[part 2 of 2: package /MICROSAR/Dem_swc/ComponentTypes]
AUTOSAR XML (schema 00049)
package /MICROSAR/Dem_swc/ComponentTypes  (continued)
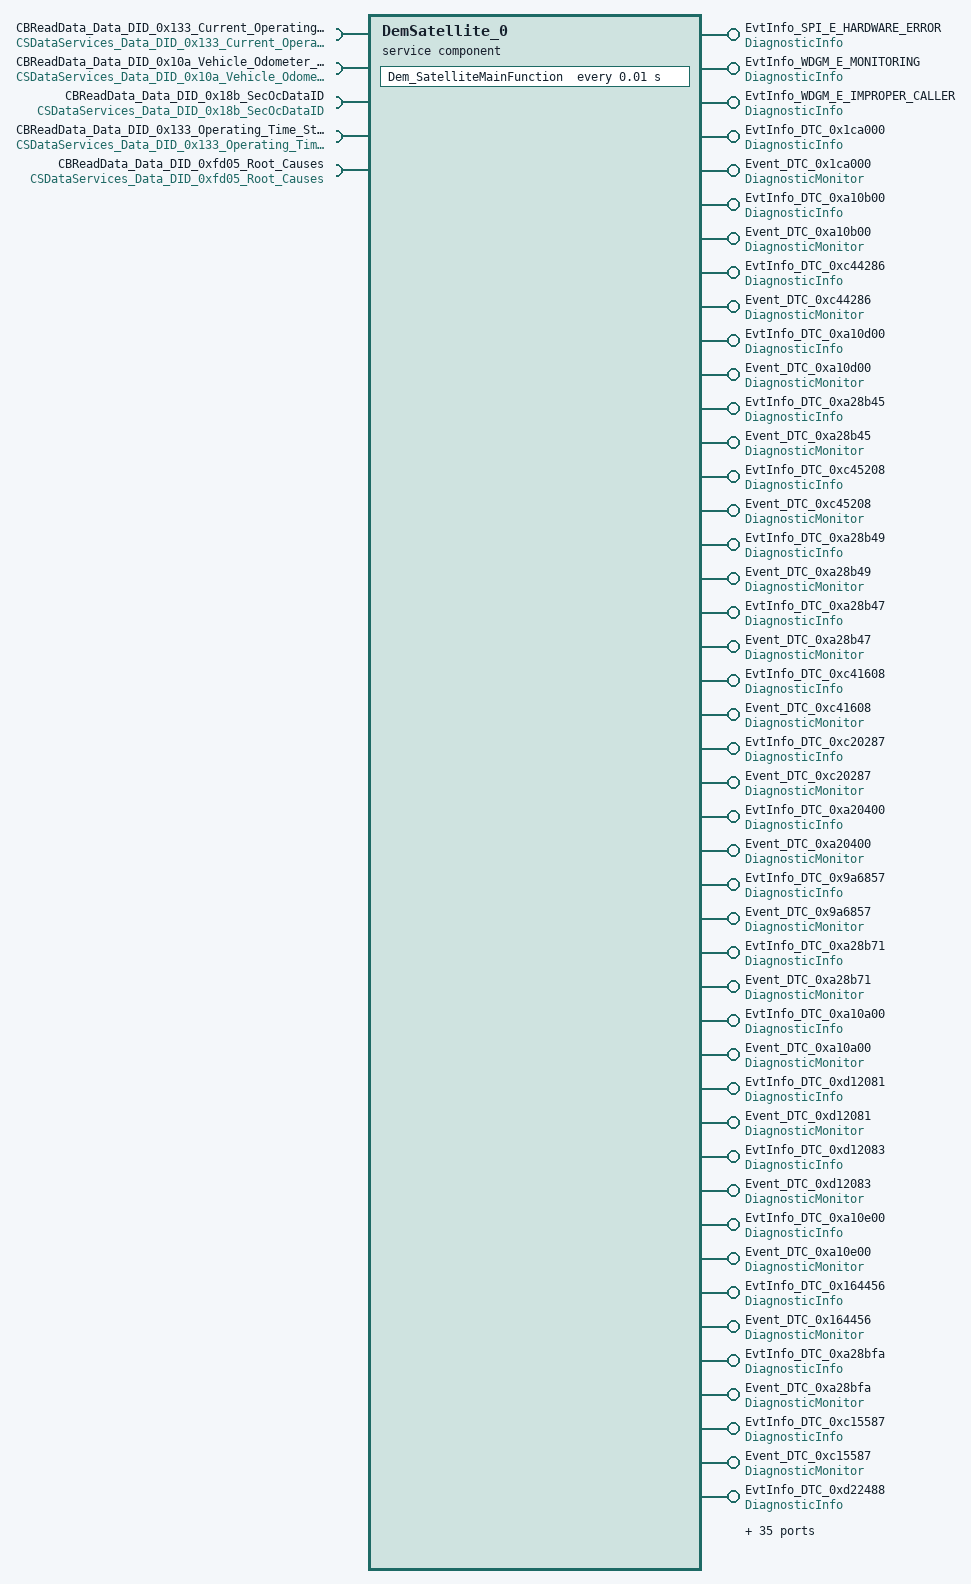
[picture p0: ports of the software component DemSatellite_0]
  service sw component type DemSatellite_0: category=SERVICE_COMPONENT
    70 x provide port:
      EvtInfo_SPI_E_HARDWARE_ERROR: provided-interface=DiagnosticInfo
      EvtInfo_WDGM_E_MONITORING: provided-interface=DiagnosticInfo
      EvtInfo_WDGM_E_IMPROPER_CALLER: provided-interface=DiagnosticInfo
      EvtInfo_DTC_0x1ca000: provided-interface=DiagnosticInfo
      Event_DTC_0x1ca000: provided-interface=DiagnosticMonitor
      EvtInfo_DTC_0xa10b00: provided-interface=DiagnosticInfo
      Event_DTC_0xa10b00: provided-interface=DiagnosticMonitor
      EvtInfo_DTC_0xc44286: provided-interface=DiagnosticInfo
      Event_DTC_0xc44286: provided-interface=DiagnosticMonitor
      EvtInfo_DTC_0xa10d00: provided-interface=DiagnosticInfo
      Event_DTC_0xa10d00: provided-interface=DiagnosticMonitor
      EvtInfo_DTC_0xa28b45: provided-interface=DiagnosticInfo
      Event_DTC_0xa28b45: provided-interface=DiagnosticMonitor
      EvtInfo_DTC_0xc45208: provided-interface=DiagnosticInfo
      Event_DTC_0xc45208: provided-interface=DiagnosticMonitor
      EvtInfo_DTC_0xa28b49: provided-interface=DiagnosticInfo
      Event_DTC_0xa28b49: provided-interface=DiagnosticMonitor
      EvtInfo_DTC_0xa28b47: provided-interface=DiagnosticInfo
      Event_DTC_0xa28b47: provided-interface=DiagnosticMonitor
      EvtInfo_DTC_0xc41608: provided-interface=DiagnosticInfo
      Event_DTC_0xc41608: provided-interface=DiagnosticMonitor
      EvtInfo_DTC_0xc20287: provided-interface=DiagnosticInfo
      Event_DTC_0xc20287: provided-interface=DiagnosticMonitor
      EvtInfo_DTC_0xa20400: provided-interface=DiagnosticInfo
      Event_DTC_0xa20400: provided-interface=DiagnosticMonitor
      EvtInfo_DTC_0x9a6857: provided-interface=DiagnosticInfo
      Event_DTC_0x9a6857: provided-interface=DiagnosticMonitor
      EvtInfo_DTC_0xa28b71: provided-interface=DiagnosticInfo
      Event_DTC_0xa28b71: provided-interface=DiagnosticMonitor
      EvtInfo_DTC_0xa10a00: provided-interface=DiagnosticInfo
      Event_DTC_0xa10a00: provided-interface=DiagnosticMonitor
      EvtInfo_DTC_0xd12081: provided-interface=DiagnosticInfo
      Event_DTC_0xd12081: provided-interface=DiagnosticMonitor
      EvtInfo_DTC_0xd12083: provided-interface=DiagnosticInfo
      Event_DTC_0xd12083: provided-interface=DiagnosticMonitor
      EvtInfo_DTC_0xa10e00: provided-interface=DiagnosticInfo
      Event_DTC_0xa10e00: provided-interface=DiagnosticMonitor
      EvtInfo_DTC_0x164456: provided-interface=DiagnosticInfo
      Event_DTC_0x164456: provided-interface=DiagnosticMonitor
      EvtInfo_DTC_0xa28bfa: provided-interface=DiagnosticInfo
      Event_DTC_0xa28bfa: provided-interface=DiagnosticMonitor
      EvtInfo_DTC_0xc15587: provided-interface=DiagnosticInfo
      Event_DTC_0xc15587: provided-interface=DiagnosticMonitor
      EvtInfo_DTC_0xd22488: provided-interface=DiagnosticInfo
      Event_DTC_0xd22488: provided-interface=DiagnosticMonitor
      EvtInfo_DTC_0xd12087: provided-interface=DiagnosticInfo
      Event_DTC_0xd12087: provided-interface=DiagnosticMonitor
      EvtInfo_DTC_0xc11587: provided-interface=DiagnosticInfo
      Event_DTC_0xc11587: provided-interface=DiagnosticMonitor
      EvtInfo_DTC_0xc15187: provided-interface=DiagnosticInfo
      Event_DTC_0xc15187: provided-interface=DiagnosticMonitor
      EvtInfo_DTC_0xc20187: provided-interface=DiagnosticInfo
      Event_DTC_0xc20187: provided-interface=DiagnosticMonitor
      EvtInfo_DTC_0xa28b4b: provided-interface=DiagnosticInfo
      Event_DTC_0xa28b4b: provided-interface=DiagnosticMonitor
      EvtInfo_DTC_0xa28b96: provided-interface=DiagnosticInfo
      Event_DTC_0xa28b96: provided-interface=DiagnosticMonitor
      EvtInfo_DTC_0xc12287: provided-interface=DiagnosticInfo
      Event_DTC_0xc12287: provided-interface=DiagnosticMonitor
      EvtInfo_DTC_0xc16887: provided-interface=DiagnosticInfo
      Event_DTC_0xc16887: provided-interface=DiagnosticMonitor
      EvtInfo_DTC_0xa28b97: provided-interface=DiagnosticInfo
      Event_DTC_0xa28b97: provided-interface=DiagnosticMonitor
      EvtInfo_DTC_0xa28b16: provided-interface=DiagnosticInfo
      Event_DTC_0xa28b16: provided-interface=DiagnosticMonitor
      EvtInfo_DTC_0xc42708: provided-interface=DiagnosticInfo
      Event_DTC_0xc42708: provided-interface=DiagnosticMonitor
      EvtInfo_DTC_0xa28b17: provided-interface=DiagnosticInfo
      Event_DTC_0xa28b17: provided-interface=DiagnosticMonitor
      GeneralEvtInfo: provided-interface=GeneralDiagnosticInfo
    4 x require port:
      CBReadData_Data_DID_0x133_Current_Operating_Time: required-interface=CSDataServices_Data_DID_0x133_Current_Operating_Time
      CBReadData_Data_DID_0x10a_Vehicle_Odometer_in_Low_Resolution: required-interface=CSDataServices_Data_DID_0x10a_Vehicle_Odometer_in_Low_Resolution
      CBReadData_Data_DID_0x18b_SecOcDataID: required-interface=CSDataServices_Data_DID_0x18b_SecOcDataID
      CBReadData_Data_DID_0x133_Operating_Time_Status: required-interface=CSDataServices_Data_DID_0x133_Operating_Time_Status
    9 x provide port:
      EvtInfo_ADC_ERROR_Dummy: provided-interface=DiagnosticInfo
      Event_ADC_ERROR_Dummy: provided-interface=DiagnosticMonitor
      EvtInfo_MCU_E_OSC_FAILURE: provided-interface=DiagnosticInfo
      EvtInfo_MCU_E_SYSTEM_PLL_LOCK_LOSS: provided-interface=DiagnosticInfo
      EvtInfo_FEE_E_READ: provided-interface=DiagnosticInfo
      EvtInfo_DTC_0xd88987: provided-interface=DiagnosticInfo
      Event_DTC_0xd88987: provided-interface=DiagnosticMonitor
      EvtInfo_DTC_0xd88a08: provided-interface=DiagnosticInfo
      Event_DTC_0xd88a08: provided-interface=DiagnosticMonitor
    require port CBReadData_Data_DID_0xfd05_Root_Causes: required-interface=CSDataServices_Data_DID_0xfd05_Root_Causes
    behavior DemSatellite_0InternalBehavior: handle-termination-and-restart=NO-SUPPORT, included-data-type-set=data-type=[Dem_EventIdType, Dem_RatioIdType, Dem_EventStatusType, Dem_UdsStatusByteType, Dem_DTCFormatType, Dem_InitMonitorReasonType, Dem_OperationCycleStateType, Dem_DTCStatusMaskType, Dem_IndicatorStatusType, Dem_MaxDataValueType, Dem_DTCKindType, Dem_DTCGroupType, Dem_IumprDenomCondIdType, Dem_IumprDenomCondStatusType, Dem_DebounceResetStatusType, Dem_DebouncingStateType, Dem_IumprReadinessGroupType, Dem_DTRControlType, Dem_DTCSeverityType, Dem_MonitorStatusType]
      timing event Timer_Dem_SatelliteMainFunction: start-on-event=Dem_SatelliteMainFunction, period=0.01
      869 x operation invoked event:
        OpEventGetEventUdsStatus_GetEventUdsStatus_EvtInfo_SPI_E_HARDWARE_ERROR: start-on-event=DemSatellite_0InternalBehavior/GetEventUdsStatus, operation=EvtInfo_SPI_E_HARDWARE_ERROR.GetEventUdsStatus
        OpEventGetEventUdsStatus_GetEventUdsStatus_EvtInfo_WDGM_E_MONITORING: start-on-event=DemSatellite_0InternalBehavior/GetEventUdsStatus, operation=EvtInfo_WDGM_E_MONITORING.GetEventUdsStatus
        OpEventGetEventUdsStatus_GetEventUdsStatus_EvtInfo_WDGM_E_IMPROPER_CALLER: start-on-event=DemSatellite_0InternalBehavior/GetEventUdsStatus, operation=EvtInfo_WDGM_E_IMPROPER_CALLER.GetEventUdsStatus
        OpEventGetEventUdsStatus_GetEventUdsStatus_EvtInfo_DTC_0x1ca000: start-on-event=DemSatellite_0InternalBehavior/GetEventUdsStatus, operation=EvtInfo_DTC_0x1ca000.GetEventUdsStatus
        OpEventGetEventUdsStatus_GetEventUdsStatus_Event_DTC_0x1ca000: start-on-event=DemSatellite_0InternalBehavior/GetEventUdsStatus, operation=Event_DTC_0x1ca000.GetEventUdsStatus
        OpEventGetEventUdsStatus_GetEventUdsStatus_EvtInfo_DTC_0xa10b00: start-on-event=DemSatellite_0InternalBehavior/GetEventUdsStatus, operation=EvtInfo_DTC_0xa10b00.GetEventUdsStatus
        OpEventGetEventUdsStatus_GetEventUdsStatus_Event_DTC_0xa10b00: start-on-event=DemSatellite_0InternalBehavior/GetEventUdsStatus, operation=Event_DTC_0xa10b00.GetEventUdsStatus
        OpEventGetEventUdsStatus_GetEventUdsStatus_EvtInfo_DTC_0xc44286: start-on-event=DemSatellite_0InternalBehavior/GetEventUdsStatus, operation=EvtInfo_DTC_0xc44286.GetEventUdsStatus
        OpEventGetEventUdsStatus_GetEventUdsStatus_Event_DTC_0xc44286: start-on-event=DemSatellite_0InternalBehavior/GetEventUdsStatus, operation=Event_DTC_0xc44286.GetEventUdsStatus
        OpEventGetEventUdsStatus_GetEventUdsStatus_EvtInfo_DTC_0xa10d00: start-on-event=DemSatellite_0InternalBehavior/GetEventUdsStatus, operation=EvtInfo_DTC_0xa10d00.GetEventUdsStatus
        OpEventGetEventUdsStatus_GetEventUdsStatus_Event_DTC_0xa10d00: start-on-event=DemSatellite_0InternalBehavior/GetEventUdsStatus, operation=Event_DTC_0xa10d00.GetEventUdsStatus
        OpEventGetEventUdsStatus_GetEventUdsStatus_EvtInfo_DTC_0xa28b45: start-on-event=DemSatellite_0InternalBehavior/GetEventUdsStatus, operation=EvtInfo_DTC_0xa28b45.GetEventUdsStatus
        OpEventGetEventUdsStatus_GetEventUdsStatus_Event_DTC_0xa28b45: start-on-event=DemSatellite_0InternalBehavior/GetEventUdsStatus, operation=Event_DTC_0xa28b45.GetEventUdsStatus
        OpEventGetEventUdsStatus_GetEventUdsStatus_EvtInfo_DTC_0xc45208: start-on-event=DemSatellite_0InternalBehavior/GetEventUdsStatus, operation=EvtInfo_DTC_0xc45208.GetEventUdsStatus
        OpEventGetEventUdsStatus_GetEventUdsStatus_Event_DTC_0xc45208: start-on-event=DemSatellite_0InternalBehavior/GetEventUdsStatus, operation=Event_DTC_0xc45208.GetEventUdsStatus
        OpEventGetEventUdsStatus_GetEventUdsStatus_EvtInfo_DTC_0xa28b49: start-on-event=DemSatellite_0InternalBehavior/GetEventUdsStatus, operation=EvtInfo_DTC_0xa28b49.GetEventUdsStatus
        OpEventGetEventUdsStatus_GetEventUdsStatus_Event_DTC_0xa28b49: start-on-event=DemSatellite_0InternalBehavior/GetEventUdsStatus, operation=Event_DTC_0xa28b49.GetEventUdsStatus
        OpEventGetEventUdsStatus_GetEventUdsStatus_EvtInfo_DTC_0xa28b47: start-on-event=DemSatellite_0InternalBehavior/GetEventUdsStatus, operation=EvtInfo_DTC_0xa28b47.GetEventUdsStatus
        OpEventGetEventUdsStatus_GetEventUdsStatus_Event_DTC_0xa28b47: start-on-event=DemSatellite_0InternalBehavior/GetEventUdsStatus, operation=Event_DTC_0xa28b47.GetEventUdsStatus
        OpEventGetEventUdsStatus_GetEventUdsStatus_EvtInfo_DTC_0xc41608: start-on-event=DemSatellite_0InternalBehavior/GetEventUdsStatus, operation=EvtInfo_DTC_0xc41608.GetEventUdsStatus
        OpEventGetEventUdsStatus_GetEventUdsStatus_Event_DTC_0xc41608: start-on-event=DemSatellite_0InternalBehavior/GetEventUdsStatus, operation=Event_DTC_0xc41608.GetEventUdsStatus
        OpEventGetEventUdsStatus_GetEventUdsStatus_EvtInfo_DTC_0xc20287: start-on-event=DemSatellite_0InternalBehavior/GetEventUdsStatus, operation=EvtInfo_DTC_0xc20287.GetEventUdsStatus
        OpEventGetEventUdsStatus_GetEventUdsStatus_Event_DTC_0xc20287: start-on-event=DemSatellite_0InternalBehavior/GetEventUdsStatus, operation=Event_DTC_0xc20287.GetEventUdsStatus
        OpEventGetEventUdsStatus_GetEventUdsStatus_EvtInfo_DTC_0xa20400: start-on-event=DemSatellite_0InternalBehavior/GetEventUdsStatus, operation=EvtInfo_DTC_0xa20400.GetEventUdsStatus
        OpEventGetEventUdsStatus_GetEventUdsStatus_Event_DTC_0xa20400: start-on-event=DemSatellite_0InternalBehavior/GetEventUdsStatus, operation=Event_DTC_0xa20400.GetEventUdsStatus
        OpEventGetEventUdsStatus_GetEventUdsStatus_EvtInfo_DTC_0x9a6857: start-on-event=DemSatellite_0InternalBehavior/GetEventUdsStatus, operation=EvtInfo_DTC_0x9a6857.GetEventUdsStatus
        OpEventGetEventUdsStatus_GetEventUdsStatus_Event_DTC_0x9a6857: start-on-event=DemSatellite_0InternalBehavior/GetEventUdsStatus, operation=Event_DTC_0x9a6857.GetEventUdsStatus
        OpEventGetEventUdsStatus_GetEventUdsStatus_EvtInfo_DTC_0xa28b71: start-on-event=DemSatellite_0InternalBehavior/GetEventUdsStatus, operation=EvtInfo_DTC_0xa28b71.GetEventUdsStatus
        OpEventGetEventUdsStatus_GetEventUdsStatus_Event_DTC_0xa28b71: start-on-event=DemSatellite_0InternalBehavior/GetEventUdsStatus, operation=Event_DTC_0xa28b71.GetEventUdsStatus
        OpEventGetEventUdsStatus_GetEventUdsStatus_EvtInfo_DTC_0xa10a00: start-on-event=DemSatellite_0InternalBehavior/GetEventUdsStatus, operation=EvtInfo_DTC_0xa10a00.GetEventUdsStatus
        OpEventGetEventUdsStatus_GetEventUdsStatus_Event_DTC_0xa10a00: start-on-event=DemSatellite_0InternalBehavior/GetEventUdsStatus, operation=Event_DTC_0xa10a00.GetEventUdsStatus
        OpEventGetEventUdsStatus_GetEventUdsStatus_EvtInfo_DTC_0xd12081: start-on-event=DemSatellite_0InternalBehavior/GetEventUdsStatus, operation=EvtInfo_DTC_0xd12081.GetEventUdsStatus
        OpEventGetEventUdsStatus_GetEventUdsStatus_Event_DTC_0xd12081: start-on-event=DemSatellite_0InternalBehavior/GetEventUdsStatus, operation=Event_DTC_0xd12081.GetEventUdsStatus
        OpEventGetEventUdsStatus_GetEventUdsStatus_EvtInfo_DTC_0xd12083: start-on-event=DemSatellite_0InternalBehavior/GetEventUdsStatus, operation=EvtInfo_DTC_0xd12083.GetEventUdsStatus
        OpEventGetEventUdsStatus_GetEventUdsStatus_Event_DTC_0xd12083: start-on-event=DemSatellite_0InternalBehavior/GetEventUdsStatus, operation=Event_DTC_0xd12083.GetEventUdsStatus
        OpEventGetEventUdsStatus_GetEventUdsStatus_EvtInfo_DTC_0xa10e00: start-on-event=DemSatellite_0InternalBehavior/GetEventUdsStatus, operation=EvtInfo_DTC_0xa10e00.GetEventUdsStatus
        OpEventGetEventUdsStatus_GetEventUdsStatus_Event_DTC_0xa10e00: start-on-event=DemSatellite_0InternalBehavior/GetEventUdsStatus, operation=Event_DTC_0xa10e00.GetEventUdsStatus
        OpEventGetEventUdsStatus_GetEventUdsStatus_EvtInfo_DTC_0x164456: start-on-event=DemSatellite_0InternalBehavior/GetEventUdsStatus, operation=EvtInfo_DTC_0x164456.GetEventUdsStatus
        OpEventGetEventUdsStatus_GetEventUdsStatus_Event_DTC_0x164456: start-on-event=DemSatellite_0InternalBehavior/GetEventUdsStatus, operation=Event_DTC_0x164456.GetEventUdsStatus
        OpEventGetEventUdsStatus_GetEventUdsStatus_EvtInfo_DTC_0xa28bfa: start-on-event=DemSatellite_0InternalBehavior/GetEventUdsStatus, operation=EvtInfo_DTC_0xa28bfa.GetEventUdsStatus
        OpEventGetEventUdsStatus_GetEventUdsStatus_Event_DTC_0xa28bfa: start-on-event=DemSatellite_0InternalBehavior/GetEventUdsStatus, operation=Event_DTC_0xa28bfa.GetEventUdsStatus
        OpEventGetEventUdsStatus_GetEventUdsStatus_EvtInfo_DTC_0xc15587: start-on-event=DemSatellite_0InternalBehavior/GetEventUdsStatus, operation=EvtInfo_DTC_0xc15587.GetEventUdsStatus
        OpEventGetEventUdsStatus_GetEventUdsStatus_Event_DTC_0xc15587: start-on-event=DemSatellite_0InternalBehavior/GetEventUdsStatus, operation=Event_DTC_0xc15587.GetEventUdsStatus
        OpEventGetEventUdsStatus_GetEventUdsStatus_EvtInfo_DTC_0xd22488: start-on-event=DemSatellite_0InternalBehavior/GetEventUdsStatus, operation=EvtInfo_DTC_0xd22488.GetEventUdsStatus
        OpEventGetEventUdsStatus_GetEventUdsStatus_Event_DTC_0xd22488: start-on-event=DemSatellite_0InternalBehavior/GetEventUdsStatus, operation=Event_DTC_0xd22488.GetEventUdsStatus
        OpEventGetEventUdsStatus_GetEventUdsStatus_EvtInfo_DTC_0xd12087: start-on-event=DemSatellite_0InternalBehavior/GetEventUdsStatus, operation=EvtInfo_DTC_0xd12087.GetEventUdsStatus
        OpEventGetEventUdsStatus_GetEventUdsStatus_Event_DTC_0xd12087: start-on-event=DemSatellite_0InternalBehavior/GetEventUdsStatus, operation=Event_DTC_0xd12087.GetEventUdsStatus
        OpEventGetEventUdsStatus_GetEventUdsStatus_EvtInfo_DTC_0xc11587: start-on-event=DemSatellite_0InternalBehavior/GetEventUdsStatus, operation=EvtInfo_DTC_0xc11587.GetEventUdsStatus
        OpEventGetEventUdsStatus_GetEventUdsStatus_Event_DTC_0xc11587: start-on-event=DemSatellite_0InternalBehavior/GetEventUdsStatus, operation=Event_DTC_0xc11587.GetEventUdsStatus
        OpEventGetEventUdsStatus_GetEventUdsStatus_EvtInfo_DTC_0xc15187: start-on-event=DemSatellite_0InternalBehavior/GetEventUdsStatus, operation=EvtInfo_DTC_0xc15187.GetEventUdsStatus
        OpEventGetEventUdsStatus_GetEventUdsStatus_Event_DTC_0xc15187: start-on-event=DemSatellite_0InternalBehavior/GetEventUdsStatus, operation=Event_DTC_0xc15187.GetEventUdsStatus
        OpEventGetEventUdsStatus_GetEventUdsStatus_EvtInfo_DTC_0xc20187: start-on-event=DemSatellite_0InternalBehavior/GetEventUdsStatus, operation=EvtInfo_DTC_0xc20187.GetEventUdsStatus
        OpEventGetEventUdsStatus_GetEventUdsStatus_Event_DTC_0xc20187: start-on-event=DemSatellite_0InternalBehavior/GetEventUdsStatus, operation=Event_DTC_0xc20187.GetEventUdsStatus
        OpEventGetEventUdsStatus_GetEventUdsStatus_EvtInfo_DTC_0xa28b4b: start-on-event=DemSatellite_0InternalBehavior/GetEventUdsStatus, operation=EvtInfo_DTC_0xa28b4b.GetEventUdsStatus
        OpEventGetEventUdsStatus_GetEventUdsStatus_Event_DTC_0xa28b4b: start-on-event=DemSatellite_0InternalBehavior/GetEventUdsStatus, operation=Event_DTC_0xa28b4b.GetEventUdsStatus
        OpEventGetEventUdsStatus_GetEventUdsStatus_EvtInfo_DTC_0xa28b96: start-on-event=DemSatellite_0InternalBehavior/GetEventUdsStatus, operation=EvtInfo_DTC_0xa28b96.GetEventUdsStatus
        OpEventGetEventUdsStatus_GetEventUdsStatus_Event_DTC_0xa28b96: start-on-event=DemSatellite_0InternalBehavior/GetEventUdsStatus, operation=Event_DTC_0xa28b96.GetEventUdsStatus
        OpEventGetEventUdsStatus_GetEventUdsStatus_EvtInfo_DTC_0xc12287: start-on-event=DemSatellite_0InternalBehavior/GetEventUdsStatus, operation=EvtInfo_DTC_0xc12287.GetEventUdsStatus
        OpEventGetEventUdsStatus_GetEventUdsStatus_Event_DTC_0xc12287: start-on-event=DemSatellite_0InternalBehavior/GetEventUdsStatus, operation=Event_DTC_0xc12287.GetEventUdsStatus
        OpEventGetEventUdsStatus_GetEventUdsStatus_EvtInfo_DTC_0xc16887: start-on-event=DemSatellite_0InternalBehavior/GetEventUdsStatus, operation=EvtInfo_DTC_0xc16887.GetEventUdsStatus
        OpEventGetEventUdsStatus_GetEventUdsStatus_Event_DTC_0xc16887: start-on-event=DemSatellite_0InternalBehavior/GetEventUdsStatus, operation=Event_DTC_0xc16887.GetEventUdsStatus
        OpEventGetEventUdsStatus_GetEventUdsStatus_EvtInfo_DTC_0xa28b97: start-on-event=DemSatellite_0InternalBehavior/GetEventUdsStatus, operation=EvtInfo_DTC_0xa28b97.GetEventUdsStatus
        OpEventGetEventUdsStatus_GetEventUdsStatus_Event_DTC_0xa28b97: start-on-event=DemSatellite_0InternalBehavior/GetEventUdsStatus, operation=Event_DTC_0xa28b97.GetEventUdsStatus
        OpEventGetEventUdsStatus_GetEventUdsStatus_EvtInfo_DTC_0xa28b16: start-on-event=DemSatellite_0InternalBehavior/GetEventUdsStatus, operation=EvtInfo_DTC_0xa28b16.GetEventUdsStatus
        OpEventGetEventUdsStatus_GetEventUdsStatus_Event_DTC_0xa28b16: start-on-event=DemSatellite_0InternalBehavior/GetEventUdsStatus, operation=Event_DTC_0xa28b16.GetEventUdsStatus
        OpEventGetEventUdsStatus_GetEventUdsStatus_EvtInfo_DTC_0xc42708: start-on-event=DemSatellite_0InternalBehavior/GetEventUdsStatus, operation=EvtInfo_DTC_0xc42708.GetEventUdsStatus
        OpEventGetEventUdsStatus_GetEventUdsStatus_Event_DTC_0xc42708: start-on-event=DemSatellite_0InternalBehavior/GetEventUdsStatus, operation=Event_DTC_0xc42708.GetEventUdsStatus
        OpEventGetEventUdsStatus_GetEventUdsStatus_EvtInfo_DTC_0xa28b17: start-on-event=DemSatellite_0InternalBehavior/GetEventUdsStatus, operation=EvtInfo_DTC_0xa28b17.GetEventUdsStatus
        OpEventGetEventUdsStatus_GetEventUdsStatus_Event_DTC_0xa28b17: start-on-event=DemSatellite_0InternalBehavior/GetEventUdsStatus, operation=Event_DTC_0xa28b17.GetEventUdsStatus
        OpEventGetEventUdsStatus_GetEventUdsStatus_GeneralEvtInfo: start-on-event=DemSatellite_0InternalBehavior/GetEventUdsStatus, operation=GeneralEvtInfo.GetEventUdsStatus
        OpEventGetEventStatus_GetEventStatus_EvtInfo_SPI_E_HARDWARE_ERROR: start-on-event=DemSatellite_0InternalBehavior/GetEventStatus, operation=EvtInfo_SPI_E_HARDWARE_ERROR.GetEventStatus
        OpEventGetEventStatus_GetEventStatus_EvtInfo_WDGM_E_MONITORING: start-on-event=DemSatellite_0InternalBehavior/GetEventStatus, operation=EvtInfo_WDGM_E_MONITORING.GetEventStatus
        OpEventGetEventStatus_GetEventStatus_EvtInfo_WDGM_E_IMPROPER_CALLER: start-on-event=DemSatellite_0InternalBehavior/GetEventStatus, operation=EvtInfo_WDGM_E_IMPROPER_CALLER.GetEventStatus
        OpEventGetEventStatus_GetEventStatus_EvtInfo_DTC_0x1ca000: start-on-event=DemSatellite_0InternalBehavior/GetEventStatus, operation=EvtInfo_DTC_0x1ca000.GetEventStatus
        OpEventGetEventStatus_GetEventStatus_Event_DTC_0x1ca000: start-on-event=DemSatellite_0InternalBehavior/GetEventStatus, operation=Event_DTC_0x1ca000.GetEventStatus
        OpEventGetEventStatus_GetEventStatus_EvtInfo_DTC_0xa10b00: start-on-event=DemSatellite_0InternalBehavior/GetEventStatus, operation=EvtInfo_DTC_0xa10b00.GetEventStatus
        OpEventGetEventStatus_GetEventStatus_Event_DTC_0xa10b00: start-on-event=DemSatellite_0InternalBehavior/GetEventStatus, operation=Event_DTC_0xa10b00.GetEventStatus
        OpEventGetEventStatus_GetEventStatus_EvtInfo_DTC_0xc44286: start-on-event=DemSatellite_0InternalBehavior/GetEventStatus, operation=EvtInfo_DTC_0xc44286.GetEventStatus
        OpEventGetEventStatus_GetEventStatus_Event_DTC_0xc44286: start-on-event=DemSatellite_0InternalBehavior/GetEventStatus, operation=Event_DTC_0xc44286.GetEventStatus
        OpEventGetEventStatus_GetEventStatus_EvtInfo_DTC_0xa10d00: start-on-event=DemSatellite_0InternalBehavior/GetEventStatus, operation=EvtInfo_DTC_0xa10d00.GetEventStatus
        OpEventGetEventStatus_GetEventStatus_Event_DTC_0xa10d00: start-on-event=DemSatellite_0InternalBehavior/GetEventStatus, operation=Event_DTC_0xa10d00.GetEventStatus
        OpEventGetEventStatus_GetEventStatus_EvtInfo_DTC_0xa28b45: start-on-event=DemSatellite_0InternalBehavior/GetEventStatus, operation=EvtInfo_DTC_0xa28b45.GetEventStatus
        OpEventGetEventStatus_GetEventStatus_Event_DTC_0xa28b45: start-on-event=DemSatellite_0InternalBehavior/GetEventStatus, operation=Event_DTC_0xa28b45.GetEventStatus
        OpEventGetEventStatus_GetEventStatus_EvtInfo_DTC_0xc45208: start-on-event=DemSatellite_0InternalBehavior/GetEventStatus, operation=EvtInfo_DTC_0xc45208.GetEventStatus
        OpEventGetEventStatus_GetEventStatus_Event_DTC_0xc45208: start-on-event=DemSatellite_0InternalBehavior/GetEventStatus, operation=Event_DTC_0xc45208.GetEventStatus
        OpEventGetEventStatus_GetEventStatus_EvtInfo_DTC_0xa28b49: start-on-event=DemSatellite_0InternalBehavior/GetEventStatus, operation=EvtInfo_DTC_0xa28b49.GetEventStatus
        OpEventGetEventStatus_GetEventStatus_Event_DTC_0xa28b49: start-on-event=DemSatellite_0InternalBehavior/GetEventStatus, operation=Event_DTC_0xa28b49.GetEventStatus
        OpEventGetEventStatus_GetEventStatus_EvtInfo_DTC_0xa28b47: start-on-event=DemSatellite_0InternalBehavior/GetEventStatus, operation=EvtInfo_DTC_0xa28b47.GetEventStatus
        OpEventGetEventStatus_GetEventStatus_Event_DTC_0xa28b47: start-on-event=DemSatellite_0InternalBehavior/GetEventStatus, operation=Event_DTC_0xa28b47.GetEventStatus
        OpEventGetEventStatus_GetEventStatus_EvtInfo_DTC_0xc41608: start-on-event=DemSatellite_0InternalBehavior/GetEventStatus, operation=EvtInfo_DTC_0xc41608.GetEventStatus
        OpEventGetEventStatus_GetEventStatus_Event_DTC_0xc41608: start-on-event=DemSatellite_0InternalBehavior/GetEventStatus, operation=Event_DTC_0xc41608.GetEventStatus
        OpEventGetEventStatus_GetEventStatus_EvtInfo_DTC_0xc20287: start-on-event=DemSatellite_0InternalBehavior/GetEventStatus, operation=EvtInfo_DTC_0xc20287.GetEventStatus
        OpEventGetEventStatus_GetEventStatus_Event_DTC_0xc20287: start-on-event=DemSatellite_0InternalBehavior/GetEventStatus, operation=Event_DTC_0xc20287.GetEventStatus
        OpEventGetEventStatus_GetEventStatus_EvtInfo_DTC_0xa20400: start-on-event=DemSatellite_0InternalBehavior/GetEventStatus, operation=EvtInfo_DTC_0xa20400.GetEventStatus
        OpEventGetEventStatus_GetEventStatus_Event_DTC_0xa20400: start-on-event=DemSatellite_0InternalBehavior/GetEventStatus, operation=Event_DTC_0xa20400.GetEventStatus
        OpEventGetEventStatus_GetEventStatus_EvtInfo_DTC_0x9a6857: start-on-event=DemSatellite_0InternalBehavior/GetEventStatus, operation=EvtInfo_DTC_0x9a6857.GetEventStatus
        OpEventGetEventStatus_GetEventStatus_Event_DTC_0x9a6857: start-on-event=DemSatellite_0InternalBehavior/GetEventStatus, operation=Event_DTC_0x9a6857.GetEventStatus
        OpEventGetEventStatus_GetEventStatus_EvtInfo_DTC_0xa28b71: start-on-event=DemSatellite_0InternalBehavior/GetEventStatus, operation=EvtInfo_DTC_0xa28b71.GetEventStatus
        OpEventGetEventStatus_GetEventStatus_Event_DTC_0xa28b71: start-on-event=DemSatellite_0InternalBehavior/GetEventStatus, operation=Event_DTC_0xa28b71.GetEventStatus
        OpEventGetEventStatus_GetEventStatus_EvtInfo_DTC_0xa10a00: start-on-event=DemSatellite_0InternalBehavior/GetEventStatus, operation=EvtInfo_DTC_0xa10a00.GetEventStatus
        OpEventGetEventStatus_GetEventStatus_Event_DTC_0xa10a00: start-on-event=DemSatellite_0InternalBehavior/GetEventStatus, operation=Event_DTC_0xa10a00.GetEventStatus
        OpEventGetEventStatus_GetEventStatus_EvtInfo_DTC_0xd12081: start-on-event=DemSatellite_0InternalBehavior/GetEventStatus, operation=EvtInfo_DTC_0xd12081.GetEventStatus
        OpEventGetEventStatus_GetEventStatus_Event_DTC_0xd12081: start-on-event=DemSatellite_0InternalBehavior/GetEventStatus, operation=Event_DTC_0xd12081.GetEventStatus
        OpEventGetEventStatus_GetEventStatus_EvtInfo_DTC_0xd12083: start-on-event=DemSatellite_0InternalBehavior/GetEventStatus, operation=EvtInfo_DTC_0xd12083.GetEventStatus
        OpEventGetEventStatus_GetEventStatus_Event_DTC_0xd12083: start-on-event=DemSatellite_0InternalBehavior/GetEventStatus, operation=Event_DTC_0xd12083.GetEventStatus
        OpEventGetEventStatus_GetEventStatus_EvtInfo_DTC_0xa10e00: start-on-event=DemSatellite_0InternalBehavior/GetEventStatus, operation=EvtInfo_DTC_0xa10e00.GetEventStatus
        OpEventGetEventStatus_GetEventStatus_Event_DTC_0xa10e00: start-on-event=DemSatellite_0InternalBehavior/GetEventStatus, operation=Event_DTC_0xa10e00.GetEventStatus
        OpEventGetEventStatus_GetEventStatus_EvtInfo_DTC_0x164456: start-on-event=DemSatellite_0InternalBehavior/GetEventStatus, operation=EvtInfo_DTC_0x164456.GetEventStatus
        OpEventGetEventStatus_GetEventStatus_Event_DTC_0x164456: start-on-event=DemSatellite_0InternalBehavior/GetEventStatus, operation=Event_DTC_0x164456.GetEventStatus
        OpEventGetEventStatus_GetEventStatus_EvtInfo_DTC_0xa28bfa: start-on-event=DemSatellite_0InternalBehavior/GetEventStatus, operation=EvtInfo_DTC_0xa28bfa.GetEventStatus
        OpEventGetEventStatus_GetEventStatus_Event_DTC_0xa28bfa: start-on-event=DemSatellite_0InternalBehavior/GetEventStatus, operation=Event_DTC_0xa28bfa.GetEventStatus
        OpEventGetEventStatus_GetEventStatus_EvtInfo_DTC_0xc15587: start-on-event=DemSatellite_0InternalBehavior/GetEventStatus, operation=EvtInfo_DTC_0xc15587.GetEventStatus
        OpEventGetEventStatus_GetEventStatus_Event_DTC_0xc15587: start-on-event=DemSatellite_0InternalBehavior/GetEventStatus, operation=Event_DTC_0xc15587.GetEventStatus
        OpEventGetEventStatus_GetEventStatus_EvtInfo_DTC_0xd22488: start-on-event=DemSatellite_0InternalBehavior/GetEventStatus, operation=EvtInfo_DTC_0xd22488.GetEventStatus
        OpEventGetEventStatus_GetEventStatus_Event_DTC_0xd22488: start-on-event=DemSatellite_0InternalBehavior/GetEventStatus, operation=Event_DTC_0xd22488.GetEventStatus
        OpEventGetEventStatus_GetEventStatus_EvtInfo_DTC_0xd12087: start-on-event=DemSatellite_0InternalBehavior/GetEventStatus, operation=EvtInfo_DTC_0xd12087.GetEventStatus
        OpEventGetEventStatus_GetEventStatus_Event_DTC_0xd12087: start-on-event=DemSatellite_0InternalBehavior/GetEventStatus, operation=Event_DTC_0xd12087.GetEventStatus
        OpEventGetEventStatus_GetEventStatus_EvtInfo_DTC_0xc11587: start-on-event=DemSatellite_0InternalBehavior/GetEventStatus, operation=EvtInfo_DTC_0xc11587.GetEventStatus
        OpEventGetEventStatus_GetEventStatus_Event_DTC_0xc11587: start-on-event=DemSatellite_0InternalBehavior/GetEventStatus, operation=Event_DTC_0xc11587.GetEventStatus
        OpEventGetEventStatus_GetEventStatus_EvtInfo_DTC_0xc15187: start-on-event=DemSatellite_0InternalBehavior/GetEventStatus, operation=EvtInfo_DTC_0xc15187.GetEventStatus
        OpEventGetEventStatus_GetEventStatus_Event_DTC_0xc15187: start-on-event=DemSatellite_0InternalBehavior/GetEventStatus, operation=Event_DTC_0xc15187.GetEventStatus
        OpEventGetEventStatus_GetEventStatus_EvtInfo_DTC_0xc20187: start-on-event=DemSatellite_0InternalBehavior/GetEventStatus, operation=EvtInfo_DTC_0xc20187.GetEventStatus
        OpEventGetEventStatus_GetEventStatus_Event_DTC_0xc20187: start-on-event=DemSatellite_0InternalBehavior/GetEventStatus, operation=Event_DTC_0xc20187.GetEventStatus
        OpEventGetEventStatus_GetEventStatus_EvtInfo_DTC_0xa28b4b: start-on-event=DemSatellite_0InternalBehavior/GetEventStatus, operation=EvtInfo_DTC_0xa28b4b.GetEventStatus
        OpEventGetEventStatus_GetEventStatus_Event_DTC_0xa28b4b: start-on-event=DemSatellite_0InternalBehavior/GetEventStatus, operation=Event_DTC_0xa28b4b.GetEventStatus
        OpEventGetEventStatus_GetEventStatus_EvtInfo_DTC_0xa28b96: start-on-event=DemSatellite_0InternalBehavior/GetEventStatus, operation=EvtInfo_DTC_0xa28b96.GetEventStatus
        OpEventGetEventStatus_GetEventStatus_Event_DTC_0xa28b96: start-on-event=DemSatellite_0InternalBehavior/GetEventStatus, operation=Event_DTC_0xa28b96.GetEventStatus
        OpEventGetEventStatus_GetEventStatus_EvtInfo_DTC_0xc12287: start-on-event=DemSatellite_0InternalBehavior/GetEventStatus, operation=EvtInfo_DTC_0xc12287.GetEventStatus
        OpEventGetEventStatus_GetEventStatus_Event_DTC_0xc12287: start-on-event=DemSatellite_0InternalBehavior/GetEventStatus, operation=Event_DTC_0xc12287.GetEventStatus
        OpEventGetEventStatus_GetEventStatus_EvtInfo_DTC_0xc16887: start-on-event=DemSatellite_0InternalBehavior/GetEventStatus, operation=EvtInfo_DTC_0xc16887.GetEventStatus
        OpEventGetEventStatus_GetEventStatus_Event_DTC_0xc16887: start-on-event=DemSatellite_0InternalBehavior/GetEventStatus, operation=Event_DTC_0xc16887.GetEventStatus
        OpEventGetEventStatus_GetEventStatus_EvtInfo_DTC_0xa28b97: start-on-event=DemSatellite_0InternalBehavior/GetEventStatus, operation=EvtInfo_DTC_0xa28b97.GetEventStatus
        OpEventGetEventStatus_GetEventStatus_Event_DTC_0xa28b97: start-on-event=DemSatellite_0InternalBehavior/GetEventStatus, operation=Event_DTC_0xa28b97.GetEventStatus
        OpEventGetEventStatus_GetEventStatus_EvtInfo_DTC_0xa28b16: start-on-event=DemSatellite_0InternalBehavior/GetEventStatus, operation=EvtInfo_DTC_0xa28b16.GetEventStatus
        OpEventGetEventStatus_GetEventStatus_Event_DTC_0xa28b16: start-on-event=DemSatellite_0InternalBehavior/GetEventStatus, operation=Event_DTC_0xa28b16.GetEventStatus
        OpEventGetEventStatus_GetEventStatus_EvtInfo_DTC_0xc42708: start-on-event=DemSatellite_0InternalBehavior/GetEventStatus, operation=EvtInfo_DTC_0xc42708.GetEventStatus
        OpEventGetEventStatus_GetEventStatus_Event_DTC_0xc42708: start-on-event=DemSatellite_0InternalBehavior/GetEventStatus, operation=Event_DTC_0xc42708.GetEventStatus
        OpEventGetEventStatus_GetEventStatus_EvtInfo_DTC_0xa28b17: start-on-event=DemSatellite_0InternalBehavior/GetEventStatus, operation=EvtInfo_DTC_0xa28b17.GetEventStatus
        OpEventGetEventStatus_GetEventStatus_Event_DTC_0xa28b17: start-on-event=DemSatellite_0InternalBehavior/GetEventStatus, operation=Event_DTC_0xa28b17.GetEventStatus
        OpEventGetEventStatus_GetEventStatus_GeneralEvtInfo: start-on-event=DemSatellite_0InternalBehavior/GetEventStatus, operation=GeneralEvtInfo.GetEventStatus
        OpEventGetEventFailed_GetEventFailed_EvtInfo_SPI_E_HARDWARE_ERROR: start-on-event=DemSatellite_0InternalBehavior/GetEventFailed, operation=EvtInfo_SPI_E_HARDWARE_ERROR.GetEventFailed
        OpEventGetEventFailed_GetEventFailed_EvtInfo_WDGM_E_MONITORING: start-on-event=DemSatellite_0InternalBehavior/GetEventFailed, operation=EvtInfo_WDGM_E_MONITORING.GetEventFailed
        OpEventGetEventFailed_GetEventFailed_EvtInfo_WDGM_E_IMPROPER_CALLER: start-on-event=DemSatellite_0InternalBehavior/GetEventFailed, operation=EvtInfo_WDGM_E_IMPROPER_CALLER.GetEventFailed
        OpEventGetEventFailed_GetEventFailed_EvtInfo_DTC_0x1ca000: start-on-event=DemSatellite_0InternalBehavior/GetEventFailed, operation=EvtInfo_DTC_0x1ca000.GetEventFailed
        OpEventGetEventFailed_GetEventFailed_Event_DTC_0x1ca000: start-on-event=DemSatellite_0InternalBehavior/GetEventFailed, operation=Event_DTC_0x1ca000.GetEventFailed
        OpEventGetEventFailed_GetEventFailed_EvtInfo_DTC_0xa10b00: start-on-event=DemSatellite_0InternalBehavior/GetEventFailed, operation=EvtInfo_DTC_0xa10b00.GetEventFailed
        OpEventGetEventFailed_GetEventFailed_Event_DTC_0xa10b00: start-on-event=DemSatellite_0InternalBehavior/GetEventFailed, operation=Event_DTC_0xa10b00.GetEventFailed
        OpEventGetEventFailed_GetEventFailed_EvtInfo_DTC_0xc44286: start-on-event=DemSatellite_0InternalBehavior/GetEventFailed, operation=EvtInfo_DTC_0xc44286.GetEventFailed
        OpEventGetEventFailed_GetEventFailed_Event_DTC_0xc44286: start-on-event=DemSatellite_0InternalBehavior/GetEventFailed, operation=Event_DTC_0xc44286.GetEventFailed
        OpEventGetEventFailed_GetEventFailed_EvtInfo_DTC_0xa10d00: start-on-event=DemSatellite_0InternalBehavior/GetEventFailed, operation=EvtInfo_DTC_0xa10d00.GetEventFailed
        OpEventGetEventFailed_GetEventFailed_Event_DTC_0xa10d00: start-on-event=DemSatellite_0InternalBehavior/GetEventFailed, operation=Event_DTC_0xa10d00.GetEventFailed
        OpEventGetEventFailed_GetEventFailed_EvtInfo_DTC_0xa28b45: start-on-event=DemSatellite_0InternalBehavior/GetEventFailed, operation=EvtInfo_DTC_0xa28b45.GetEventFailed
        OpEventGetEventFailed_GetEventFailed_Event_DTC_0xa28b45: start-on-event=DemSatellite_0InternalBehavior/GetEventFailed, operation=Event_DTC_0xa28b45.GetEventFailed
        OpEventGetEventFailed_GetEventFailed_EvtInfo_DTC_0xc45208: start-on-event=DemSatellite_0InternalBehavior/GetEventFailed, operation=EvtInfo_DTC_0xc45208.GetEventFailed
        OpEventGetEventFailed_GetEventFailed_Event_DTC_0xc45208: start-on-event=DemSatellite_0InternalBehavior/GetEventFailed, operation=Event_DTC_0xc45208.GetEventFailed
        OpEventGetEventFailed_GetEventFailed_EvtInfo_DTC_0xa28b49: start-on-event=DemSatellite_0InternalBehavior/GetEventFailed, operation=EvtInfo_DTC_0xa28b49.GetEventFailed
        OpEventGetEventFailed_GetEventFailed_Event_DTC_0xa28b49: start-on-event=DemSatellite_0InternalBehavior/GetEventFailed, operation=Event_DTC_0xa28b49.GetEventFailed
        OpEventGetEventFailed_GetEventFailed_EvtInfo_DTC_0xa28b47: start-on-event=DemSatellite_0InternalBehavior/GetEventFailed, operation=EvtInfo_DTC_0xa28b47.GetEventFailed
        OpEventGetEventFailed_GetEventFailed_Event_DTC_0xa28b47: start-on-event=DemSatellite_0InternalBehavior/GetEventFailed, operation=Event_DTC_0xa28b47.GetEventFailed
        OpEventGetEventFailed_GetEventFailed_EvtInfo_DTC_0xc41608: start-on-event=DemSatellite_0InternalBehavior/GetEventFailed, operation=EvtInfo_DTC_0xc41608.GetEventFailed
        OpEventGetEventFailed_GetEventFailed_Event_DTC_0xc41608: start-on-event=DemSatellite_0InternalBehavior/GetEventFailed, operation=Event_DTC_0xc41608.GetEventFailed
        OpEventGetEventFailed_GetEventFailed_EvtInfo_DTC_0xc20287: start-on-event=DemSatellite_0InternalBehavior/GetEventFailed, operation=EvtInfo_DTC_0xc20287.GetEventFailed
        OpEventGetEventFailed_GetEventFailed_Event_DTC_0xc20287: start-on-event=DemSatellite_0InternalBehavior/GetEventFailed, operation=Event_DTC_0xc20287.GetEventFailed
        OpEventGetEventFailed_GetEventFailed_EvtInfo_DTC_0xa20400: start-on-event=DemSatellite_0InternalBehavior/GetEventFailed, operation=EvtInfo_DTC_0xa20400.GetEventFailed
        OpEventGetEventFailed_GetEventFailed_Event_DTC_0xa20400: start-on-event=DemSatellite_0InternalBehavior/GetEventFailed, operation=Event_DTC_0xa20400.GetEventFailed
        OpEventGetEventFailed_GetEventFailed_EvtInfo_DTC_0x9a6857: start-on-event=DemSatellite_0InternalBehavior/GetEventFailed, operation=EvtInfo_DTC_0x9a6857.GetEventFailed
        OpEventGetEventFailed_GetEventFailed_Event_DTC_0x9a6857: start-on-event=DemSatellite_0InternalBehavior/GetEventFailed, operation=Event_DTC_0x9a6857.GetEventFailed
        OpEventGetEventFailed_GetEventFailed_EvtInfo_DTC_0xa28b71: start-on-event=DemSatellite_0InternalBehavior/GetEventFailed, operation=EvtInfo_DTC_0xa28b71.GetEventFailed
        OpEventGetEventFailed_GetEventFailed_Event_DTC_0xa28b71: start-on-event=DemSatellite_0InternalBehavior/GetEventFailed, operation=Event_DTC_0xa28b71.GetEventFailed
        OpEventGetEventFailed_GetEventFailed_EvtInfo_DTC_0xa10a00: start-on-event=DemSatellite_0InternalBehavior/GetEventFailed, operation=EvtInfo_DTC_0xa10a00.GetEventFailed
        OpEventGetEventFailed_GetEventFailed_Event_DTC_0xa10a00: start-on-event=DemSatellite_0InternalBehavior/GetEventFailed, operation=Event_DTC_0xa10a00.GetEventFailed
        OpEventGetEventFailed_GetEventFailed_EvtInfo_DTC_0xd12081: start-on-event=DemSatellite_0InternalBehavior/GetEventFailed, operation=EvtInfo_DTC_0xd12081.GetEventFailed
        OpEventGetEventFailed_GetEventFailed_Event_DTC_0xd12081: start-on-event=DemSatellite_0InternalBehavior/GetEventFailed, operation=Event_DTC_0xd12081.GetEventFailed
        OpEventGetEventFailed_GetEventFailed_EvtInfo_DTC_0xd12083: start-on-event=DemSatellite_0InternalBehavior/GetEventFailed, operation=EvtInfo_DTC_0xd12083.GetEventFailed
        OpEventGetEventFailed_GetEventFailed_Event_DTC_0xd12083: start-on-event=DemSatellite_0InternalBehavior/GetEventFailed, operation=Event_DTC_0xd12083.GetEventFailed
        OpEventGetEventFailed_GetEventFailed_EvtInfo_DTC_0xa10e00: start-on-event=DemSatellite_0InternalBehavior/GetEventFailed, operation=EvtInfo_DTC_0xa10e00.GetEventFailed
        OpEventGetEventFailed_GetEventFailed_Event_DTC_0xa10e00: start-on-event=DemSatellite_0InternalBehavior/GetEventFailed, operation=Event_DTC_0xa10e00.GetEventFailed
        OpEventGetEventFailed_GetEventFailed_EvtInfo_DTC_0x164456: start-on-event=DemSatellite_0InternalBehavior/GetEventFailed, operation=EvtInfo_DTC_0x164456.GetEventFailed
        OpEventGetEventFailed_GetEventFailed_Event_DTC_0x164456: start-on-event=DemSatellite_0InternalBehavior/GetEventFailed, operation=Event_DTC_0x164456.GetEventFailed
        OpEventGetEventFailed_GetEventFailed_EvtInfo_DTC_0xa28bfa: start-on-event=DemSatellite_0InternalBehavior/GetEventFailed, operation=EvtInfo_DTC_0xa28bfa.GetEventFailed
        OpEventGetEventFailed_GetEventFailed_Event_DTC_0xa28bfa: start-on-event=DemSatellite_0InternalBehavior/GetEventFailed, operation=Event_DTC_0xa28bfa.GetEventFailed
        OpEventGetEventFailed_GetEventFailed_EvtInfo_DTC_0xc15587: start-on-event=DemSatellite_0InternalBehavior/GetEventFailed, operation=EvtInfo_DTC_0xc15587.GetEventFailed
        OpEventGetEventFailed_GetEventFailed_Event_DTC_0xc15587: start-on-event=DemSatellite_0InternalBehavior/GetEventFailed, operation=Event_DTC_0xc15587.GetEventFailed
        OpEventGetEventFailed_GetEventFailed_EvtInfo_DTC_0xd22488: start-on-event=DemSatellite_0InternalBehavior/GetEventFailed, operation=EvtInfo_DTC_0xd22488.GetEventFailed
        OpEventGetEventFailed_GetEventFailed_Event_DTC_0xd22488: start-on-event=DemSatellite_0InternalBehavior/GetEventFailed, operation=Event_DTC_0xd22488.GetEventFailed
        OpEventGetEventFailed_GetEventFailed_EvtInfo_DTC_0xd12087: start-on-event=DemSatellite_0InternalBehavior/GetEventFailed, operation=EvtInfo_DTC_0xd12087.GetEventFailed
        OpEventGetEventFailed_GetEventFailed_Event_DTC_0xd12087: start-on-event=DemSatellite_0InternalBehavior/GetEventFailed, operation=Event_DTC_0xd12087.GetEventFailed
        OpEventGetEventFailed_GetEventFailed_EvtInfo_DTC_0xc11587: start-on-event=DemSatellite_0InternalBehavior/GetEventFailed, operation=EvtInfo_DTC_0xc11587.GetEventFailed
        OpEventGetEventFailed_GetEventFailed_Event_DTC_0xc11587: start-on-event=DemSatellite_0InternalBehavior/GetEventFailed, operation=Event_DTC_0xc11587.GetEventFailed
        OpEventGetEventFailed_GetEventFailed_EvtInfo_DTC_0xc15187: start-on-event=DemSatellite_0InternalBehavior/GetEventFailed, operation=EvtInfo_DTC_0xc15187.GetEventFailed
        OpEventGetEventFailed_GetEventFailed_Event_DTC_0xc15187: start-on-event=DemSatellite_0InternalBehavior/GetEventFailed, operation=Event_DTC_0xc15187.GetEventFailed
        OpEventGetEventFailed_GetEventFailed_EvtInfo_DTC_0xc20187: start-on-event=DemSatellite_0InternalBehavior/GetEventFailed, operation=EvtInfo_DTC_0xc20187.GetEventFailed
        OpEventGetEventFailed_GetEventFailed_Event_DTC_0xc20187: start-on-event=DemSatellite_0InternalBehavior/GetEventFailed, operation=Event_DTC_0xc20187.GetEventFailed
        OpEventGetEventFailed_GetEventFailed_EvtInfo_DTC_0xa28b4b: start-on-event=DemSatellite_0InternalBehavior/GetEventFailed, operation=EvtInfo_DTC_0xa28b4b.GetEventFailed
        OpEventGetEventFailed_GetEventFailed_Event_DTC_0xa28b4b: start-on-event=DemSatellite_0InternalBehavior/GetEventFailed, operation=Event_DTC_0xa28b4b.GetEventFailed
        OpEventGetEventFailed_GetEventFailed_EvtInfo_DTC_0xa28b96: start-on-event=DemSatellite_0InternalBehavior/GetEventFailed, operation=EvtInfo_DTC_0xa28b96.GetEventFailed
        OpEventGetEventFailed_GetEventFailed_Event_DTC_0xa28b96: start-on-event=DemSatellite_0InternalBehavior/GetEventFailed, operation=Event_DTC_0xa28b96.GetEventFailed
        OpEventGetEventFailed_GetEventFailed_EvtInfo_DTC_0xc12287: start-on-event=DemSatellite_0InternalBehavior/GetEventFailed, operation=EvtInfo_DTC_0xc12287.GetEventFailed
        OpEventGetEventFailed_GetEventFailed_Event_DTC_0xc12287: start-on-event=DemSatellite_0InternalBehavior/GetEventFailed, operation=Event_DTC_0xc12287.GetEventFailed
        OpEventGetEventFailed_GetEventFailed_EvtInfo_DTC_0xc16887: start-on-event=DemSatellite_0InternalBehavior/GetEventFailed, operation=EvtInfo_DTC_0xc16887.GetEventFailed
        OpEventGetEventFailed_GetEventFailed_Event_DTC_0xc16887: start-on-event=DemSatellite_0InternalBehavior/GetEventFailed, operation=Event_DTC_0xc16887.GetEventFailed
        OpEventGetEventFailed_GetEventFailed_EvtInfo_DTC_0xa28b97: start-on-event=DemSatellite_0InternalBehavior/GetEventFailed, operation=EvtInfo_DTC_0xa28b97.GetEventFailed
        OpEventGetEventFailed_GetEventFailed_Event_DTC_0xa28b97: start-on-event=DemSatellite_0InternalBehavior/GetEventFailed, operation=Event_DTC_0xa28b97.GetEventFailed
        OpEventGetEventFailed_GetEventFailed_EvtInfo_DTC_0xa28b16: start-on-event=DemSatellite_0InternalBehavior/GetEventFailed, operation=EvtInfo_DTC_0xa28b16.GetEventFailed
        OpEventGetEventFailed_GetEventFailed_Event_DTC_0xa28b16: start-on-event=DemSatellite_0InternalBehavior/GetEventFailed, operation=Event_DTC_0xa28b16.GetEventFailed
        OpEventGetEventFailed_GetEventFailed_EvtInfo_DTC_0xc42708: start-on-event=DemSatellite_0InternalBehavior/GetEventFailed, operation=EvtInfo_DTC_0xc42708.GetEventFailed
        OpEventGetEventFailed_GetEventFailed_Event_DTC_0xc42708: start-on-event=DemSatellite_0InternalBehavior/GetEventFailed, operation=Event_DTC_0xc42708.GetEventFailed
        OpEventGetEventFailed_GetEventFailed_EvtInfo_DTC_0xa28b17: start-on-event=DemSatellite_0InternalBehavior/GetEventFailed, operation=EvtInfo_DTC_0xa28b17.GetEventFailed
        OpEventGetEventFailed_GetEventFailed_Event_DTC_0xa28b17: start-on-event=DemSatellite_0InternalBehavior/GetEventFailed, operation=Event_DTC_0xa28b17.GetEventFailed
        OpEventGetEventFailed_GetEventFailed_GeneralEvtInfo: start-on-event=DemSatellite_0InternalBehavior/GetEventFailed, operation=GeneralEvtInfo.GetEventFailed
        OpEventGetEventTested_GetEventTested_EvtInfo_SPI_E_HARDWARE_ERROR: start-on-event=DemSatellite_0InternalBehavior/GetEventTested, operation=EvtInfo_SPI_E_HARDWARE_ERROR.GetEventTested
        OpEventGetEventTested_GetEventTested_EvtInfo_WDGM_E_MONITORING: start-on-event=DemSatellite_0InternalBehavior/GetEventTested, operation=EvtInfo_WDGM_E_MONITORING.GetEventTested
        OpEventGetEventTested_GetEventTested_EvtInfo_WDGM_E_IMPROPER_CALLER: start-on-event=DemSatellite_0InternalBehavior/GetEventTested, operation=EvtInfo_WDGM_E_IMPROPER_CALLER.GetEventTested
        OpEventGetEventTested_GetEventTested_EvtInfo_DTC_0x1ca000: start-on-event=DemSatellite_0InternalBehavior/GetEventTested, operation=EvtInfo_DTC_0x1ca000.GetEventTested
        OpEventGetEventTested_GetEventTested_Event_DTC_0x1ca000: start-on-event=DemSatellite_0InternalBehavior/GetEventTested, operation=Event_DTC_0x1ca000.GetEventTested
        OpEventGetEventTested_GetEventTested_EvtInfo_DTC_0xa10b00: start-on-event=DemSatellite_0InternalBehavior/GetEventTested, operation=EvtInfo_DTC_0xa10b00.GetEventTested
        OpEventGetEventTested_GetEventTested_Event_DTC_0xa10b00: start-on-event=DemSatellite_0InternalBehavior/GetEventTested, operation=Event_DTC_0xa10b00.GetEventTested
        OpEventGetEventTested_GetEventTested_EvtInfo_DTC_0xc44286: start-on-event=DemSatellite_0InternalBehavior/GetEventTested, operation=EvtInfo_DTC_0xc44286.GetEventTested
        OpEventGetEventTested_GetEventTested_Event_DTC_0xc44286: start-on-event=DemSatellite_0InternalBehavior/GetEventTested, operation=Event_DTC_0xc44286.GetEventTested
        OpEventGetEventTested_GetEventTested_EvtInfo_DTC_0xa10d00: start-on-event=DemSatellite_0InternalBehavior/GetEventTested, operation=EvtInfo_DTC_0xa10d00.GetEventTested
        OpEventGetEventTested_GetEventTested_Event_DTC_0xa10d00: start-on-event=DemSatellite_0InternalBehavior/GetEventTested, operation=Event_DTC_0xa10d00.GetEventTested
        OpEventGetEventTested_GetEventTested_EvtInfo_DTC_0xa28b45: start-on-event=DemSatellite_0InternalBehavior/GetEventTested, operation=EvtInfo_DTC_0xa28b45.GetEventTested
        OpEventGetEventTested_GetEventTested_Event_DTC_0xa28b45: start-on-event=DemSatellite_0InternalBehavior/GetEventTested, operation=Event_DTC_0xa28b45.GetEventTested
        OpEventGetEventTested_GetEventTested_EvtInfo_DTC_0xc45208: start-on-event=DemSatellite_0InternalBehavior/GetEventTested, operation=EvtInfo_DTC_0xc45208.GetEventTested
        OpEventGetEventTested_GetEventTested_Event_DTC_0xc45208: start-on-event=DemSatellite_0InternalBehavior/GetEventTested, operation=Event_DTC_0xc45208.GetEventTested
        OpEventGetEventTested_GetEventTested_EvtInfo_DTC_0xa28b49: start-on-event=DemSatellite_0InternalBehavior/GetEventTested, operation=EvtInfo_DTC_0xa28b49.GetEventTested
        OpEventGetEventTested_GetEventTested_Event_DTC_0xa28b49: start-on-event=DemSatellite_0InternalBehavior/GetEventTested, operation=Event_DTC_0xa28b49.GetEventTested
        OpEventGetEventTested_GetEventTested_EvtInfo_DTC_0xa28b47: start-on-event=DemSatellite_0InternalBehavior/GetEventTested, operation=EvtInfo_DTC_0xa28b47.GetEventTested
        OpEventGetEventTested_GetEventTested_Event_DTC_0xa28b47: start-on-event=DemSatellite_0InternalBehavior/GetEventTested, operation=Event_DTC_0xa28b47.GetEventTested
        OpEventGetEventTested_GetEventTested_EvtInfo_DTC_0xc41608: start-on-event=DemSatellite_0InternalBehavior/GetEventTested, operation=EvtInfo_DTC_0xc41608.GetEventTested
        OpEventGetEventTested_GetEventTested_Event_DTC_0xc41608: start-on-event=DemSatellite_0InternalBehavior/GetEventTested, operation=Event_DTC_0xc41608.GetEventTested
        OpEventGetEventTested_GetEventTested_EvtInfo_DTC_0xc20287: start-on-event=DemSatellite_0InternalBehavior/GetEventTested, operation=EvtInfo_DTC_0xc20287.GetEventTested
        OpEventGetEventTested_GetEventTested_Event_DTC_0xc20287: start-on-event=DemSatellite_0InternalBehavior/GetEventTested, operation=Event_DTC_0xc20287.GetEventTested
        OpEventGetEventTested_GetEventTested_EvtInfo_DTC_0xa20400: start-on-event=DemSatellite_0InternalBehavior/GetEventTested, operation=EvtInfo_DTC_0xa20400.GetEventTested
        OpEventGetEventTested_GetEventTested_Event_DTC_0xa20400: start-on-event=DemSatellite_0InternalBehavior/GetEventTested, operation=Event_DTC_0xa20400.GetEventTested
        OpEventGetEventTested_GetEventTested_EvtInfo_DTC_0x9a6857: start-on-event=DemSatellite_0InternalBehavior/GetEventTested, operation=EvtInfo_DTC_0x9a6857.GetEventTested
        OpEventGetEventTested_GetEventTested_Event_DTC_0x9a6857: start-on-event=DemSatellite_0InternalBehavior/GetEventTested, operation=Event_DTC_0x9a6857.GetEventTested
        OpEventGetEventTested_GetEventTested_EvtInfo_DTC_0xa28b71: start-on-event=DemSatellite_0InternalBehavior/GetEventTested, operation=EvtInfo_DTC_0xa28b71.GetEventTested
        OpEventGetEventTested_GetEventTested_Event_DTC_0xa28b71: start-on-event=DemSatellite_0InternalBehavior/GetEventTested, operation=Event_DTC_0xa28b71.GetEventTested
        OpEventGetEventTested_GetEventTested_EvtInfo_DTC_0xa10a00: start-on-event=DemSatellite_0InternalBehavior/GetEventTested, operation=EvtInfo_DTC_0xa10a00.GetEventTested
        OpEventGetEventTested_GetEventTested_Event_DTC_0xa10a00: start-on-event=DemSatellite_0InternalBehavior/GetEventTested, operation=Event_DTC_0xa10a00.GetEventTested
        OpEventGetEventTested_GetEventTested_EvtInfo_DTC_0xd12081: start-on-event=DemSatellite_0InternalBehavior/GetEventTested, operation=EvtInfo_DTC_0xd12081.GetEventTested
        OpEventGetEventTested_GetEventTested_Event_DTC_0xd12081: start-on-event=DemSatellite_0InternalBehavior/GetEventTested, operation=Event_DTC_0xd12081.GetEventTested
        OpEventGetEventTested_GetEventTested_EvtInfo_DTC_0xd12083: start-on-event=DemSatellite_0InternalBehavior/GetEventTested, operation=EvtInfo_DTC_0xd12083.GetEventTested
        OpEventGetEventTested_GetEventTested_Event_DTC_0xd12083: start-on-event=DemSatellite_0InternalBehavior/GetEventTested, operation=Event_DTC_0xd12083.GetEventTested
        OpEventGetEventTested_GetEventTested_EvtInfo_DTC_0xa10e00: start-on-event=DemSatellite_0InternalBehavior/GetEventTested, operation=EvtInfo_DTC_0xa10e00.GetEventTested
        OpEventGetEventTested_GetEventTested_Event_DTC_0xa10e00: start-on-event=DemSatellite_0InternalBehavior/GetEventTested, operation=Event_DTC_0xa10e00.GetEventTested
        OpEventGetEventTested_GetEventTested_EvtInfo_DTC_0x164456: start-on-event=DemSatellite_0InternalBehavior/GetEventTested, operation=EvtInfo_DTC_0x164456.GetEventTested
        OpEventGetEventTested_GetEventTested_Event_DTC_0x164456: start-on-event=DemSatellite_0InternalBehavior/GetEventTested, operation=Event_DTC_0x164456.GetEventTested
        OpEventGetEventTested_GetEventTested_EvtInfo_DTC_0xa28bfa: start-on-event=DemSatellite_0InternalBehavior/GetEventTested, operation=EvtInfo_DTC_0xa28bfa.GetEventTested
        OpEventGetEventTested_GetEventTested_Event_DTC_0xa28bfa: start-on-event=DemSatellite_0InternalBehavior/GetEventTested, operation=Event_DTC_0xa28bfa.GetEventTested
        OpEventGetEventTested_GetEventTested_EvtInfo_DTC_0xc15587: start-on-event=DemSatellite_0InternalBehavior/GetEventTested, operation=EvtInfo_DTC_0xc15587.GetEventTested
        OpEventGetEventTested_GetEventTested_Event_DTC_0xc15587: start-on-event=DemSatellite_0InternalBehavior/GetEventTested, operation=Event_DTC_0xc15587.GetEventTested
        OpEventGetEventTested_GetEventTested_EvtInfo_DTC_0xd22488: start-on-event=DemSatellite_0InternalBehavior/GetEventTested, operation=EvtInfo_DTC_0xd22488.GetEventTested
        OpEventGetEventTested_GetEventTested_Event_DTC_0xd22488: start-on-event=DemSatellite_0InternalBehavior/GetEventTested, operation=Event_DTC_0xd22488.GetEventTested
        OpEventGetEventTested_GetEventTested_EvtInfo_DTC_0xd12087: start-on-event=DemSatellite_0InternalBehavior/GetEventTested, operation=EvtInfo_DTC_0xd12087.GetEventTested
        OpEventGetEventTested_GetEventTested_Event_DTC_0xd12087: start-on-event=DemSatellite_0InternalBehavior/GetEventTested, operation=Event_DTC_0xd12087.GetEventTested
        OpEventGetEventTested_GetEventTested_EvtInfo_DTC_0xc11587: start-on-event=DemSatellite_0InternalBehavior/GetEventTested, operation=EvtInfo_DTC_0xc11587.GetEventTested
        OpEventGetEventTested_GetEventTested_Event_DTC_0xc11587: start-on-event=DemSatellite_0InternalBehavior/GetEventTested, operation=Event_DTC_0xc11587.GetEventTested
        OpEventGetEventTested_GetEventTested_EvtInfo_DTC_0xc15187: start-on-event=DemSatellite_0InternalBehavior/GetEventTested, operation=EvtInfo_DTC_0xc15187.GetEventTested
        OpEventGetEventTested_GetEventTested_Event_DTC_0xc15187: start-on-event=DemSatellite_0InternalBehavior/GetEventTested, operation=Event_DTC_0xc15187.GetEventTested
        OpEventGetEventTested_GetEventTested_EvtInfo_DTC_0xc20187: start-on-event=DemSatellite_0InternalBehavior/GetEventTested, operation=EvtInfo_DTC_0xc20187.GetEventTested
        OpEventGetEventTested_GetEventTested_Event_DTC_0xc20187: start-on-event=DemSatellite_0InternalBehavior/GetEventTested, operation=Event_DTC_0xc20187.GetEventTested
        OpEventGetEventTested_GetEventTested_EvtInfo_DTC_0xa28b4b: start-on-event=DemSatellite_0InternalBehavior/GetEventTested, operation=EvtInfo_DTC_0xa28b4b.GetEventTested
        OpEventGetEventTested_GetEventTested_Event_DTC_0xa28b4b: start-on-event=DemSatellite_0InternalBehavior/GetEventTested, operation=Event_DTC_0xa28b4b.GetEventTested
        OpEventGetEventTested_GetEventTested_EvtInfo_DTC_0xa28b96: start-on-event=DemSatellite_0InternalBehavior/GetEventTested, operation=EvtInfo_DTC_0xa28b96.GetEventTested
        OpEventGetEventTested_GetEventTested_Event_DTC_0xa28b96: start-on-event=DemSatellite_0InternalBehavior/GetEventTested, operation=Event_DTC_0xa28b96.GetEventTested
        OpEventGetEventTested_GetEventTested_EvtInfo_DTC_0xc12287: start-on-event=DemSatellite_0InternalBehavior/GetEventTested, operation=EvtInfo_DTC_0xc12287.GetEventTested
        OpEventGetEventTested_GetEventTested_Event_DTC_0xc12287: start-on-event=DemSatellite_0InternalBehavior/GetEventTested, operation=Event_DTC_0xc12287.GetEventTested
        OpEventGetEventTested_GetEventTested_EvtInfo_DTC_0xc16887: start-on-event=DemSatellite_0InternalBehavior/GetEventTested, operation=EvtInfo_DTC_0xc16887.GetEventTested
        OpEventGetEventTested_GetEventTested_Event_DTC_0xc16887: start-on-event=DemSatellite_0InternalBehavior/GetEventTested, operation=Event_DTC_0xc16887.GetEventTested
        OpEventGetEventTested_GetEventTested_EvtInfo_DTC_0xa28b97: start-on-event=DemSatellite_0InternalBehavior/GetEventTested, operation=EvtInfo_DTC_0xa28b97.GetEventTested
        OpEventGetEventTested_GetEventTested_Event_DTC_0xa28b97: start-on-event=DemSatellite_0InternalBehavior/GetEventTested, operation=Event_DTC_0xa28b97.GetEventTested
        OpEventGetEventTested_GetEventTested_EvtInfo_DTC_0xa28b16: start-on-event=DemSatellite_0InternalBehavior/GetEventTested, operation=EvtInfo_DTC_0xa28b16.GetEventTested
        OpEventGetEventTested_GetEventTested_Event_DTC_0xa28b16: start-on-event=DemSatellite_0InternalBehavior/GetEventTested, operation=Event_DTC_0xa28b16.GetEventTested
        OpEventGetEventTested_GetEventTested_EvtInfo_DTC_0xc42708: start-on-event=DemSatellite_0InternalBehavior/GetEventTested, operation=EvtInfo_DTC_0xc42708.GetEventTested
        OpEventGetEventTested_GetEventTested_Event_DTC_0xc42708: start-on-event=DemSatellite_0InternalBehavior/GetEventTested, operation=Event_DTC_0xc42708.GetEventTested
        OpEventGetEventTested_GetEventTested_EvtInfo_DTC_0xa28b17: start-on-event=DemSatellite_0InternalBehavior/GetEventTested, operation=EvtInfo_DTC_0xa28b17.GetEventTested
        OpEventGetEventTested_GetEventTested_Event_DTC_0xa28b17: start-on-event=DemSatellite_0InternalBehavior/GetEventTested, operation=Event_DTC_0xa28b17.GetEventTested
        OpEventGetEventTested_GetEventTested_GeneralEvtInfo: start-on-event=DemSatellite_0InternalBehavior/GetEventTested, operation=GeneralEvtInfo.GetEventTested
        OpEventGetDTCOfEvent_GetDTCOfEvent_EvtInfo_SPI_E_HARDWARE_ERROR: start-on-event=DemSatellite_0InternalBehavior/GetDTCOfEvent, operation=EvtInfo_SPI_E_HARDWARE_ERROR.GetDTCOfEvent
        OpEventGetDTCOfEvent_GetDTCOfEvent_EvtInfo_WDGM_E_MONITORING: start-on-event=DemSatellite_0InternalBehavior/GetDTCOfEvent, operation=EvtInfo_WDGM_E_MONITORING.GetDTCOfEvent
        OpEventGetDTCOfEvent_GetDTCOfEvent_EvtInfo_WDGM_E_IMPROPER_CALLER: start-on-event=DemSatellite_0InternalBehavior/GetDTCOfEvent, operation=EvtInfo_WDGM_E_IMPROPER_CALLER.GetDTCOfEvent
        OpEventGetDTCOfEvent_GetDTCOfEvent_EvtInfo_DTC_0x1ca000: start-on-event=DemSatellite_0InternalBehavior/GetDTCOfEvent, operation=EvtInfo_DTC_0x1ca000.GetDTCOfEvent
        OpEventGetDTCOfEvent_GetDTCOfEvent_Event_DTC_0x1ca000: start-on-event=DemSatellite_0InternalBehavior/GetDTCOfEvent, operation=Event_DTC_0x1ca000.GetDTCOfEvent
        OpEventGetDTCOfEvent_GetDTCOfEvent_EvtInfo_DTC_0xa10b00: start-on-event=DemSatellite_0InternalBehavior/GetDTCOfEvent, operation=EvtInfo_DTC_0xa10b00.GetDTCOfEvent
        OpEventGetDTCOfEvent_GetDTCOfEvent_Event_DTC_0xa10b00: start-on-event=DemSatellite_0InternalBehavior/GetDTCOfEvent, operation=Event_DTC_0xa10b00.GetDTCOfEvent
        OpEventGetDTCOfEvent_GetDTCOfEvent_EvtInfo_DTC_0xc44286: start-on-event=DemSatellite_0InternalBehavior/GetDTCOfEvent, operation=EvtInfo_DTC_0xc44286.GetDTCOfEvent
        OpEventGetDTCOfEvent_GetDTCOfEvent_Event_DTC_0xc44286: start-on-event=DemSatellite_0InternalBehavior/GetDTCOfEvent, operation=Event_DTC_0xc44286.GetDTCOfEvent
        OpEventGetDTCOfEvent_GetDTCOfEvent_EvtInfo_DTC_0xa10d00: start-on-event=DemSatellite_0InternalBehavior/GetDTCOfEvent, operation=EvtInfo_DTC_0xa10d00.GetDTCOfEvent
        OpEventGetDTCOfEvent_GetDTCOfEvent_Event_DTC_0xa10d00: start-on-event=DemSatellite_0InternalBehavior/GetDTCOfEvent, operation=Event_DTC_0xa10d00.GetDTCOfEvent
        OpEventGetDTCOfEvent_GetDTCOfEvent_EvtInfo_DTC_0xa28b45: start-on-event=DemSatellite_0InternalBehavior/GetDTCOfEvent, operation=EvtInfo_DTC_0xa28b45.GetDTCOfEvent
        OpEventGetDTCOfEvent_GetDTCOfEvent_Event_DTC_0xa28b45: start-on-event=DemSatellite_0InternalBehavior/GetDTCOfEvent, operation=Event_DTC_0xa28b45.GetDTCOfEvent
        OpEventGetDTCOfEvent_GetDTCOfEvent_EvtInfo_DTC_0xc45208: start-on-event=DemSatellite_0InternalBehavior/GetDTCOfEvent, operation=EvtInfo_DTC_0xc45208.GetDTCOfEvent
        OpEventGetDTCOfEvent_GetDTCOfEvent_Event_DTC_0xc45208: start-on-event=DemSatellite_0InternalBehavior/GetDTCOfEvent, operation=Event_DTC_0xc45208.GetDTCOfEvent
        OpEventGetDTCOfEvent_GetDTCOfEvent_EvtInfo_DTC_0xa28b49: start-on-event=DemSatellite_0InternalBehavior/GetDTCOfEvent, operation=EvtInfo_DTC_0xa28b49.GetDTCOfEvent
        OpEventGetDTCOfEvent_GetDTCOfEvent_Event_DTC_0xa28b49: start-on-event=DemSatellite_0InternalBehavior/GetDTCOfEvent, operation=Event_DTC_0xa28b49.GetDTCOfEvent
        OpEventGetDTCOfEvent_GetDTCOfEvent_EvtInfo_DTC_0xa28b47: start-on-event=DemSatellite_0InternalBehavior/GetDTCOfEvent, operation=EvtInfo_DTC_0xa28b47.GetDTCOfEvent
        OpEventGetDTCOfEvent_GetDTCOfEvent_Event_DTC_0xa28b47: start-on-event=DemSatellite_0InternalBehavior/GetDTCOfEvent, operation=Event_DTC_0xa28b47.GetDTCOfEvent
        OpEventGetDTCOfEvent_GetDTCOfEvent_EvtInfo_DTC_0xc41608: start-on-event=DemSatellite_0InternalBehavior/GetDTCOfEvent, operation=EvtInfo_DTC_0xc41608.GetDTCOfEvent
        OpEventGetDTCOfEvent_GetDTCOfEvent_Event_DTC_0xc41608: start-on-event=DemSatellite_0InternalBehavior/GetDTCOfEvent, operation=Event_DTC_0xc41608.GetDTCOfEvent
        OpEventGetDTCOfEvent_GetDTCOfEvent_EvtInfo_DTC_0xc20287: start-on-event=DemSatellite_0InternalBehavior/GetDTCOfEvent, operation=EvtInfo_DTC_0xc20287.GetDTCOfEvent
        OpEventGetDTCOfEvent_GetDTCOfEvent_Event_DTC_0xc20287: start-on-event=DemSatellite_0InternalBehavior/GetDTCOfEvent, operation=Event_DTC_0xc20287.GetDTCOfEvent
        OpEventGetDTCOfEvent_GetDTCOfEvent_EvtInfo_DTC_0xa20400: start-on-event=DemSatellite_0InternalBehavior/GetDTCOfEvent, operation=EvtInfo_DTC_0xa20400.GetDTCOfEvent
        OpEventGetDTCOfEvent_GetDTCOfEvent_Event_DTC_0xa20400: start-on-event=DemSatellite_0InternalBehavior/GetDTCOfEvent, operation=Event_DTC_0xa20400.GetDTCOfEvent
        OpEventGetDTCOfEvent_GetDTCOfEvent_EvtInfo_DTC_0x9a6857: start-on-event=DemSatellite_0InternalBehavior/GetDTCOfEvent, operation=EvtInfo_DTC_0x9a6857.GetDTCOfEvent
        OpEventGetDTCOfEvent_GetDTCOfEvent_Event_DTC_0x9a6857: start-on-event=DemSatellite_0InternalBehavior/GetDTCOfEvent, operation=Event_DTC_0x9a6857.GetDTCOfEvent
        OpEventGetDTCOfEvent_GetDTCOfEvent_EvtInfo_DTC_0xa28b71: start-on-event=DemSatellite_0InternalBehavior/GetDTCOfEvent, operation=EvtInfo_DTC_0xa28b71.GetDTCOfEvent
        OpEventGetDTCOfEvent_GetDTCOfEvent_Event_DTC_0xa28b71: start-on-event=DemSatellite_0InternalBehavior/GetDTCOfEvent, operation=Event_DTC_0xa28b71.GetDTCOfEvent
        OpEventGetDTCOfEvent_GetDTCOfEvent_EvtInfo_DTC_0xa10a00: start-on-event=DemSatellite_0InternalBehavior/GetDTCOfEvent, operation=EvtInfo_DTC_0xa10a00.GetDTCOfEvent
        OpEventGetDTCOfEvent_GetDTCOfEvent_Event_DTC_0xa10a00: start-on-event=DemSatellite_0InternalBehavior/GetDTCOfEvent, operation=Event_DTC_0xa10a00.GetDTCOfEvent
        OpEventGetDTCOfEvent_GetDTCOfEvent_EvtInfo_DTC_0xd12081: start-on-event=DemSatellite_0InternalBehavior/GetDTCOfEvent, operation=EvtInfo_DTC_0xd12081.GetDTCOfEvent
        OpEventGetDTCOfEvent_GetDTCOfEvent_Event_DTC_0xd12081: start-on-event=DemSatellite_0InternalBehavior/GetDTCOfEvent, operation=Event_DTC_0xd12081.GetDTCOfEvent
        OpEventGetDTCOfEvent_GetDTCOfEvent_EvtInfo_DTC_0xd12083: start-on-event=DemSatellite_0InternalBehavior/GetDTCOfEvent, operation=EvtInfo_DTC_0xd12083.GetDTCOfEvent
        OpEventGetDTCOfEvent_GetDTCOfEvent_Event_DTC_0xd12083: start-on-event=DemSatellite_0InternalBehavior/GetDTCOfEvent, operation=Event_DTC_0xd12083.GetDTCOfEvent
        OpEventGetDTCOfEvent_GetDTCOfEvent_EvtInfo_DTC_0xa10e00: start-on-event=DemSatellite_0InternalBehavior/GetDTCOfEvent, operation=EvtInfo_DTC_0xa10e00.GetDTCOfEvent
        OpEventGetDTCOfEvent_GetDTCOfEvent_Event_DTC_0xa10e00: start-on-event=DemSatellite_0InternalBehavior/GetDTCOfEvent, operation=Event_DTC_0xa10e00.GetDTCOfEvent
        OpEventGetDTCOfEvent_GetDTCOfEvent_EvtInfo_DTC_0x164456: start-on-event=DemSatellite_0InternalBehavior/GetDTCOfEvent, operation=EvtInfo_DTC_0x164456.GetDTCOfEvent
        OpEventGetDTCOfEvent_GetDTCOfEvent_Event_DTC_0x164456: start-on-event=DemSatellite_0InternalBehavior/GetDTCOfEvent, operation=Event_DTC_0x164456.GetDTCOfEvent
        OpEventGetDTCOfEvent_GetDTCOfEvent_EvtInfo_DTC_0xa28bfa: start-on-event=DemSatellite_0InternalBehavior/GetDTCOfEvent, operation=EvtInfo_DTC_0xa28bfa.GetDTCOfEvent
        OpEventGetDTCOfEvent_GetDTCOfEvent_Event_DTC_0xa28bfa: start-on-event=DemSatellite_0InternalBehavior/GetDTCOfEvent, operation=Event_DTC_0xa28bfa.GetDTCOfEvent
        OpEventGetDTCOfEvent_GetDTCOfEvent_EvtInfo_DTC_0xc15587: start-on-event=DemSatellite_0InternalBehavior/GetDTCOfEvent, operation=EvtInfo_DTC_0xc15587.GetDTCOfEvent
        OpEventGetDTCOfEvent_GetDTCOfEvent_Event_DTC_0xc15587: start-on-event=DemSatellite_0InternalBehavior/GetDTCOfEvent, operation=Event_DTC_0xc15587.GetDTCOfEvent
        OpEventGetDTCOfEvent_GetDTCOfEvent_EvtInfo_DTC_0xd22488: start-on-event=DemSatellite_0InternalBehavior/GetDTCOfEvent, operation=EvtInfo_DTC_0xd22488.GetDTCOfEvent
        OpEventGetDTCOfEvent_GetDTCOfEvent_Event_DTC_0xd22488: start-on-event=DemSatellite_0InternalBehavior/GetDTCOfEvent, operation=Event_DTC_0xd22488.GetDTCOfEvent
        OpEventGetDTCOfEvent_GetDTCOfEvent_EvtInfo_DTC_0xd12087: start-on-event=DemSatellite_0InternalBehavior/GetDTCOfEvent, operation=EvtInfo_DTC_0xd12087.GetDTCOfEvent
        OpEventGetDTCOfEvent_GetDTCOfEvent_Event_DTC_0xd12087: start-on-event=DemSatellite_0InternalBehavior/GetDTCOfEvent, operation=Event_DTC_0xd12087.GetDTCOfEvent
        OpEventGetDTCOfEvent_GetDTCOfEvent_EvtInfo_DTC_0xc11587: start-on-event=DemSatellite_0InternalBehavior/GetDTCOfEvent, operation=EvtInfo_DTC_0xc11587.GetDTCOfEvent
        OpEventGetDTCOfEvent_GetDTCOfEvent_Event_DTC_0xc11587: start-on-event=DemSatellite_0InternalBehavior/GetDTCOfEvent, operation=Event_DTC_0xc11587.GetDTCOfEvent
        OpEventGetDTCOfEvent_GetDTCOfEvent_EvtInfo_DTC_0xc15187: start-on-event=DemSatellite_0InternalBehavior/GetDTCOfEvent, operation=EvtInfo_DTC_0xc15187.GetDTCOfEvent
        OpEventGetDTCOfEvent_GetDTCOfEvent_Event_DTC_0xc15187: start-on-event=DemSatellite_0InternalBehavior/GetDTCOfEvent, operation=Event_DTC_0xc15187.GetDTCOfEvent
        OpEventGetDTCOfEvent_GetDTCOfEvent_EvtInfo_DTC_0xc20187: start-on-event=DemSatellite_0InternalBehavior/GetDTCOfEvent, operation=EvtInfo_DTC_0xc20187.GetDTCOfEvent
        OpEventGetDTCOfEvent_GetDTCOfEvent_Event_DTC_0xc20187: start-on-event=DemSatellite_0InternalBehavior/GetDTCOfEvent, operation=Event_DTC_0xc20187.GetDTCOfEvent
        OpEventGetDTCOfEvent_GetDTCOfEvent_EvtInfo_DTC_0xa28b4b: start-on-event=DemSatellite_0InternalBehavior/GetDTCOfEvent, operation=EvtInfo_DTC_0xa28b4b.GetDTCOfEvent
        OpEventGetDTCOfEvent_GetDTCOfEvent_Event_DTC_0xa28b4b: start-on-event=DemSatellite_0InternalBehavior/GetDTCOfEvent, operation=Event_DTC_0xa28b4b.GetDTCOfEvent
        OpEventGetDTCOfEvent_GetDTCOfEvent_EvtInfo_DTC_0xa28b96: start-on-event=DemSatellite_0InternalBehavior/GetDTCOfEvent, operation=EvtInfo_DTC_0xa28b96.GetDTCOfEvent
        OpEventGetDTCOfEvent_GetDTCOfEvent_Event_DTC_0xa28b96: start-on-event=DemSatellite_0InternalBehavior/GetDTCOfEvent, operation=Event_DTC_0xa28b96.GetDTCOfEvent
        OpEventGetDTCOfEvent_GetDTCOfEvent_EvtInfo_DTC_0xc12287: start-on-event=DemSatellite_0InternalBehavior/GetDTCOfEvent, operation=EvtInfo_DTC_0xc12287.GetDTCOfEvent
        OpEventGetDTCOfEvent_GetDTCOfEvent_Event_DTC_0xc12287: start-on-event=DemSatellite_0InternalBehavior/GetDTCOfEvent, operation=Event_DTC_0xc12287.GetDTCOfEvent
        OpEventGetDTCOfEvent_GetDTCOfEvent_EvtInfo_DTC_0xc16887: start-on-event=DemSatellite_0InternalBehavior/GetDTCOfEvent, operation=EvtInfo_DTC_0xc16887.GetDTCOfEvent
        OpEventGetDTCOfEvent_GetDTCOfEvent_Event_DTC_0xc16887: start-on-event=DemSatellite_0InternalBehavior/GetDTCOfEvent, operation=Event_DTC_0xc16887.GetDTCOfEvent
        OpEventGetDTCOfEvent_GetDTCOfEvent_EvtInfo_DTC_0xa28b97: start-on-event=DemSatellite_0InternalBehavior/GetDTCOfEvent, operation=EvtInfo_DTC_0xa28b97.GetDTCOfEvent
        OpEventGetDTCOfEvent_GetDTCOfEvent_Event_DTC_0xa28b97: start-on-event=DemSatellite_0InternalBehavior/GetDTCOfEvent, operation=Event_DTC_0xa28b97.GetDTCOfEvent
        OpEventGetDTCOfEvent_GetDTCOfEvent_EvtInfo_DTC_0xa28b16: start-on-event=DemSatellite_0InternalBehavior/GetDTCOfEvent, operation=EvtInfo_DTC_0xa28b16.GetDTCOfEvent
        OpEventGetDTCOfEvent_GetDTCOfEvent_Event_DTC_0xa28b16: start-on-event=DemSatellite_0InternalBehavior/GetDTCOfEvent, operation=Event_DTC_0xa28b16.GetDTCOfEvent
        OpEventGetDTCOfEvent_GetDTCOfEvent_EvtInfo_DTC_0xc42708: start-on-event=DemSatellite_0InternalBehavior/GetDTCOfEvent, operation=EvtInfo_DTC_0xc42708.GetDTCOfEvent
        OpEventGetDTCOfEvent_GetDTCOfEvent_Event_DTC_0xc42708: start-on-event=DemSatellite_0InternalBehavior/GetDTCOfEvent, operation=Event_DTC_0xc42708.GetDTCOfEvent
        OpEventGetDTCOfEvent_GetDTCOfEvent_EvtInfo_DTC_0xa28b17: start-on-event=DemSatellite_0InternalBehavior/GetDTCOfEvent, operation=EvtInfo_DTC_0xa28b17.GetDTCOfEvent
        OpEventGetDTCOfEvent_GetDTCOfEvent_Event_DTC_0xa28b17: start-on-event=DemSatellite_0InternalBehavior/GetDTCOfEvent, operation=Event_DTC_0xa28b17.GetDTCOfEvent
        OpEventGetDTCOfEvent_GetDTCOfEvent_GeneralEvtInfo: start-on-event=DemSatellite_0InternalBehavior/GetDTCOfEvent, operation=GeneralEvtInfo.GetDTCOfEvent
        OpEventGetFaultDetectionCounter_GetFaultDetectionCounter_EvtInfo_SPI_E_HARDWARE_ERROR: start-on-event=DemSatellite_0InternalBehavior/GetFaultDetectionCounter, operation=EvtInfo_SPI_E_HARDWARE_ERROR.GetFaultDetectionCounter
        OpEventGetFaultDetectionCounter_GetFaultDetectionCounter_EvtInfo_WDGM_E_MONITORING: start-on-event=DemSatellite_0InternalBehavior/GetFaultDetectionCounter, operation=EvtInfo_WDGM_E_MONITORING.GetFaultDetectionCounter
        OpEventGetFaultDetectionCounter_GetFaultDetectionCounter_EvtInfo_WDGM_E_IMPROPER_CALLER: start-on-event=DemSatellite_0InternalBehavior/GetFaultDetectionCounter, operation=EvtInfo_WDGM_E_IMPROPER_CALLER.GetFaultDetectionCounter
        OpEventGetFaultDetectionCounter_GetFaultDetectionCounter_EvtInfo_DTC_0x1ca000: start-on-event=DemSatellite_0InternalBehavior/GetFaultDetectionCounter, operation=EvtInfo_DTC_0x1ca000.GetFaultDetectionCounter
        OpEventGetFaultDetectionCounter_GetFaultDetectionCounter_Event_DTC_0x1ca000: start-on-event=DemSatellite_0InternalBehavior/GetFaultDetectionCounter, operation=Event_DTC_0x1ca000.GetFaultDetectionCounter
        OpEventGetFaultDetectionCounter_GetFaultDetectionCounter_EvtInfo_DTC_0xa10b00: start-on-event=DemSatellite_0InternalBehavior/GetFaultDetectionCounter, operation=EvtInfo_DTC_0xa10b00.GetFaultDetectionCounter
        OpEventGetFaultDetectionCounter_GetFaultDetectionCounter_Event_DTC_0xa10b00: start-on-event=DemSatellite_0InternalBehavior/GetFaultDetectionCounter, operation=Event_DTC_0xa10b00.GetFaultDetectionCounter
        OpEventGetFaultDetectionCounter_GetFaultDetectionCounter_EvtInfo_DTC_0xc44286: start-on-event=DemSatellite_0InternalBehavior/GetFaultDetectionCounter, operation=EvtInfo_DTC_0xc44286.GetFaultDetectionCounter
        OpEventGetFaultDetectionCounter_GetFaultDetectionCounter_Event_DTC_0xc44286: start-on-event=DemSatellite_0InternalBehavior/GetFaultDetectionCounter, operation=Event_DTC_0xc44286.GetFaultDetectionCounter
        OpEventGetFaultDetectionCounter_GetFaultDetectionCounter_EvtInfo_DTC_0xa10d00: start-on-event=DemSatellite_0InternalBehavior/GetFaultDetectionCounter, operation=EvtInfo_DTC_0xa10d00.GetFaultDetectionCounter
        OpEventGetFaultDetectionCounter_GetFaultDetectionCounter_Event_DTC_0xa10d00: start-on-event=DemSatellite_0InternalBehavior/GetFaultDetectionCounter, operation=Event_DTC_0xa10d00.GetFaultDetectionCounter
        OpEventGetFaultDetectionCounter_GetFaultDetectionCounter_EvtInfo_DTC_0xa28b45: start-on-event=DemSatellite_0InternalBehavior/GetFaultDetectionCounter, operation=EvtInfo_DTC_0xa28b45.GetFaultDetectionCounter
        OpEventGetFaultDetectionCounter_GetFaultDetectionCounter_Event_DTC_0xa28b45: start-on-event=DemSatellite_0InternalBehavior/GetFaultDetectionCounter, operation=Event_DTC_0xa28b45.GetFaultDetectionCounter
        OpEventGetFaultDetectionCounter_GetFaultDetectionCounter_EvtInfo_DTC_0xc45208: start-on-event=DemSatellite_0InternalBehavior/GetFaultDetectionCounter, operation=EvtInfo_DTC_0xc45208.GetFaultDetectionCounter
        OpEventGetFaultDetectionCounter_GetFaultDetectionCounter_Event_DTC_0xc45208: start-on-event=DemSatellite_0InternalBehavior/GetFaultDetectionCounter, operation=Event_DTC_0xc45208.GetFaultDetectionCounter
        OpEventGetFaultDetectionCounter_GetFaultDetectionCounter_EvtInfo_DTC_0xa28b49: start-on-event=DemSatellite_0InternalBehavior/GetFaultDetectionCounter, operation=EvtInfo_DTC_0xa28b49.GetFaultDetectionCounter
        OpEventGetFaultDetectionCounter_GetFaultDetectionCounter_Event_DTC_0xa28b49: start-on-event=DemSatellite_0InternalBehavior/GetFaultDetectionCounter, operation=Event_DTC_0xa28b49.GetFaultDetectionCounter
        OpEventGetFaultDetectionCounter_GetFaultDetectionCounter_EvtInfo_DTC_0xa28b47: start-on-event=DemSatellite_0InternalBehavior/GetFaultDetectionCounter, operation=EvtInfo_DTC_0xa28b47.GetFaultDetectionCounter
        OpEventGetFaultDetectionCounter_GetFaultDetectionCounter_Event_DTC_0xa28b47: start-on-event=DemSatellite_0InternalBehavior/GetFaultDetectionCounter, operation=Event_DTC_0xa28b47.GetFaultDetectionCounter
        OpEventGetFaultDetectionCounter_GetFaultDetectionCounter_EvtInfo_DTC_0xc41608: start-on-event=DemSatellite_0InternalBehavior/GetFaultDetectionCounter, operation=EvtInfo_DTC_0xc41608.GetFaultDetectionCounter
        OpEventGetFaultDetectionCounter_GetFaultDetectionCounter_Event_DTC_0xc41608: start-on-event=DemSatellite_0InternalBehavior/GetFaultDetectionCounter, operation=Event_DTC_0xc41608.GetFaultDetectionCounter
        OpEventGetFaultDetectionCounter_GetFaultDetectionCounter_EvtInfo_DTC_0xc20287: start-on-event=DemSatellite_0InternalBehavior/GetFaultDetectionCounter, operation=EvtInfo_DTC_0xc20287.GetFaultDetectionCounter
        OpEventGetFaultDetectionCounter_GetFaultDetectionCounter_Event_DTC_0xc20287: start-on-event=DemSatellite_0InternalBehavior/GetFaultDetectionCounter, operation=Event_DTC_0xc20287.GetFaultDetectionCounter
        OpEventGetFaultDetectionCounter_GetFaultDetectionCounter_EvtInfo_DTC_0xa20400: start-on-event=DemSatellite_0InternalBehavior/GetFaultDetectionCounter, operation=EvtInfo_DTC_0xa20400.GetFaultDetectionCounter
        OpEventGetFaultDetectionCounter_GetFaultDetectionCounter_Event_DTC_0xa20400: start-on-event=DemSatellite_0InternalBehavior/GetFaultDetectionCounter, operation=Event_DTC_0xa20400.GetFaultDetectionCounter
        OpEventGetFaultDetectionCounter_GetFaultDetectionCounter_EvtInfo_DTC_0x9a6857: start-on-event=DemSatellite_0InternalBehavior/GetFaultDetectionCounter, operation=EvtInfo_DTC_0x9a6857.GetFaultDetectionCounter
        OpEventGetFaultDetectionCounter_GetFaultDetectionCounter_Event_DTC_0x9a6857: start-on-event=DemSatellite_0InternalBehavior/GetFaultDetectionCounter, operation=Event_DTC_0x9a6857.GetFaultDetectionCounter
        OpEventGetFaultDetectionCounter_GetFaultDetectionCounter_EvtInfo_DTC_0xa28b71: start-on-event=DemSatellite_0InternalBehavior/GetFaultDetectionCounter, operation=EvtInfo_DTC_0xa28b71.GetFaultDetectionCounter
        OpEventGetFaultDetectionCounter_GetFaultDetectionCounter_Event_DTC_0xa28b71: start-on-event=DemSatellite_0InternalBehavior/GetFaultDetectionCounter, operation=Event_DTC_0xa28b71.GetFaultDetectionCounter
        OpEventGetFaultDetectionCounter_GetFaultDetectionCounter_EvtInfo_DTC_0xa10a00: start-on-event=DemSatellite_0InternalBehavior/GetFaultDetectionCounter, operation=EvtInfo_DTC_0xa10a00.GetFaultDetectionCounter
        OpEventGetFaultDetectionCounter_GetFaultDetectionCounter_Event_DTC_0xa10a00: start-on-event=DemSatellite_0InternalBehavior/GetFaultDetectionCounter, operation=Event_DTC_0xa10a00.GetFaultDetectionCounter
        OpEventGetFaultDetectionCounter_GetFaultDetectionCounter_EvtInfo_DTC_0xd12081: start-on-event=DemSatellite_0InternalBehavior/GetFaultDetectionCounter, operation=EvtInfo_DTC_0xd12081.GetFaultDetectionCounter
        OpEventGetFaultDetectionCounter_GetFaultDetectionCounter_Event_DTC_0xd12081: start-on-event=DemSatellite_0InternalBehavior/GetFaultDetectionCounter, operation=Event_DTC_0xd12081.GetFaultDetectionCounter
        OpEventGetFaultDetectionCounter_GetFaultDetectionCounter_EvtInfo_DTC_0xd12083: start-on-event=DemSatellite_0InternalBehavior/GetFaultDetectionCounter, operation=EvtInfo_DTC_0xd12083.GetFaultDetectionCounter
        OpEventGetFaultDetectionCounter_GetFaultDetectionCounter_Event_DTC_0xd12083: start-on-event=DemSatellite_0InternalBehavior/GetFaultDetectionCounter, operation=Event_DTC_0xd12083.GetFaultDetectionCounter
        OpEventGetFaultDetectionCounter_GetFaultDetectionCounter_EvtInfo_DTC_0xa10e00: start-on-event=DemSatellite_0InternalBehavior/GetFaultDetectionCounter, operation=EvtInfo_DTC_0xa10e00.GetFaultDetectionCounter
        OpEventGetFaultDetectionCounter_GetFaultDetectionCounter_Event_DTC_0xa10e00: start-on-event=DemSatellite_0InternalBehavior/GetFaultDetectionCounter, operation=Event_DTC_0xa10e00.GetFaultDetectionCounter
        OpEventGetFaultDetectionCounter_GetFaultDetectionCounter_EvtInfo_DTC_0x164456: start-on-event=DemSatellite_0InternalBehavior/GetFaultDetectionCounter, operation=EvtInfo_DTC_0x164456.GetFaultDetectionCounter
        OpEventGetFaultDetectionCounter_GetFaultDetectionCounter_Event_DTC_0x164456: start-on-event=DemSatellite_0InternalBehavior/GetFaultDetectionCounter, operation=Event_DTC_0x164456.GetFaultDetectionCounter
        OpEventGetFaultDetectionCounter_GetFaultDetectionCounter_EvtInfo_DTC_0xa28bfa: start-on-event=DemSatellite_0InternalBehavior/GetFaultDetectionCounter, operation=EvtInfo_DTC_0xa28bfa.GetFaultDetectionCounter
        OpEventGetFaultDetectionCounter_GetFaultDetectionCounter_Event_DTC_0xa28bfa: start-on-event=DemSatellite_0InternalBehavior/GetFaultDetectionCounter, operation=Event_DTC_0xa28bfa.GetFaultDetectionCounter
        OpEventGetFaultDetectionCounter_GetFaultDetectionCounter_EvtInfo_DTC_0xc15587: start-on-event=DemSatellite_0InternalBehavior/GetFaultDetectionCounter, operation=EvtInfo_DTC_0xc15587.GetFaultDetectionCounter
        OpEventGetFaultDetectionCounter_GetFaultDetectionCounter_Event_DTC_0xc15587: start-on-event=DemSatellite_0InternalBehavior/GetFaultDetectionCounter, operation=Event_DTC_0xc15587.GetFaultDetectionCounter
        OpEventGetFaultDetectionCounter_GetFaultDetectionCounter_EvtInfo_DTC_0xd22488: start-on-event=DemSatellite_0InternalBehavior/GetFaultDetectionCounter, operation=EvtInfo_DTC_0xd22488.GetFaultDetectionCounter
        OpEventGetFaultDetectionCounter_GetFaultDetectionCounter_Event_DTC_0xd22488: start-on-event=DemSatellite_0InternalBehavior/GetFaultDetectionCounter, operation=Event_DTC_0xd22488.GetFaultDetectionCounter
        OpEventGetFaultDetectionCounter_GetFaultDetectionCounter_EvtInfo_DTC_0xd12087: start-on-event=DemSatellite_0InternalBehavior/GetFaultDetectionCounter, operation=EvtInfo_DTC_0xd12087.GetFaultDetectionCounter
        OpEventGetFaultDetectionCounter_GetFaultDetectionCounter_Event_DTC_0xd12087: start-on-event=DemSatellite_0InternalBehavior/GetFaultDetectionCounter, operation=Event_DTC_0xd12087.GetFaultDetectionCounter
        OpEventGetFaultDetectionCounter_GetFaultDetectionCounter_EvtInfo_DTC_0xc11587: start-on-event=DemSatellite_0InternalBehavior/GetFaultDetectionCounter, operation=EvtInfo_DTC_0xc11587.GetFaultDetectionCounter
        OpEventGetFaultDetectionCounter_GetFaultDetectionCounter_Event_DTC_0xc11587: start-on-event=DemSatellite_0InternalBehavior/GetFaultDetectionCounter, operation=Event_DTC_0xc11587.GetFaultDetectionCounter
        OpEventGetFaultDetectionCounter_GetFaultDetectionCounter_EvtInfo_DTC_0xc15187: start-on-event=DemSatellite_0InternalBehavior/GetFaultDetectionCounter, operation=EvtInfo_DTC_0xc15187.GetFaultDetectionCounter
        OpEventGetFaultDetectionCounter_GetFaultDetectionCounter_Event_DTC_0xc15187: start-on-event=DemSatellite_0InternalBehavior/GetFaultDetectionCounter, operation=Event_DTC_0xc15187.GetFaultDetectionCounter
        OpEventGetFaultDetectionCounter_GetFaultDetectionCounter_EvtInfo_DTC_0xc20187: start-on-event=DemSatellite_0InternalBehavior/GetFaultDetectionCounter, operation=EvtInfo_DTC_0xc20187.GetFaultDetectionCounter
        OpEventGetFaultDetectionCounter_GetFaultDetectionCounter_Event_DTC_0xc20187: start-on-event=DemSatellite_0InternalBehavior/GetFaultDetectionCounter, operation=Event_DTC_0xc20187.GetFaultDetectionCounter
        OpEventGetFaultDetectionCounter_GetFaultDetectionCounter_EvtInfo_DTC_0xa28b4b: start-on-event=DemSatellite_0InternalBehavior/GetFaultDetectionCounter, operation=EvtInfo_DTC_0xa28b4b.GetFaultDetectionCounter
        OpEventGetFaultDetectionCounter_GetFaultDetectionCounter_Event_DTC_0xa28b4b: start-on-event=DemSatellite_0InternalBehavior/GetFaultDetectionCounter, operation=Event_DTC_0xa28b4b.GetFaultDetectionCounter
        OpEventGetFaultDetectionCounter_GetFaultDetectionCounter_EvtInfo_DTC_0xa28b96: start-on-event=DemSatellite_0InternalBehavior/GetFaultDetectionCounter, operation=EvtInfo_DTC_0xa28b96.GetFaultDetectionCounter
        OpEventGetFaultDetectionCounter_GetFaultDetectionCounter_Event_DTC_0xa28b96: start-on-event=DemSatellite_0InternalBehavior/GetFaultDetectionCounter, operation=Event_DTC_0xa28b96.GetFaultDetectionCounter
        OpEventGetFaultDetectionCounter_GetFaultDetectionCounter_EvtInfo_DTC_0xc12287: start-on-event=DemSatellite_0InternalBehavior/GetFaultDetectionCounter, operation=EvtInfo_DTC_0xc12287.GetFaultDetectionCounter
        OpEventGetFaultDetectionCounter_GetFaultDetectionCounter_Event_DTC_0xc12287: start-on-event=DemSatellite_0InternalBehavior/GetFaultDetectionCounter, operation=Event_DTC_0xc12287.GetFaultDetectionCounter
        OpEventGetFaultDetectionCounter_GetFaultDetectionCounter_EvtInfo_DTC_0xc16887: start-on-event=DemSatellite_0InternalBehavior/GetFaultDetectionCounter, operation=EvtInfo_DTC_0xc16887.GetFaultDetectionCounter
        OpEventGetFaultDetectionCounter_GetFaultDetectionCounter_Event_DTC_0xc16887: start-on-event=DemSatellite_0InternalBehavior/GetFaultDetectionCounter, operation=Event_DTC_0xc16887.GetFaultDetectionCounter
        OpEventGetFaultDetectionCounter_GetFaultDetectionCounter_EvtInfo_DTC_0xa28b97: start-on-event=DemSatellite_0InternalBehavior/GetFaultDetectionCounter, operation=EvtInfo_DTC_0xa28b97.GetFaultDetectionCounter
        OpEventGetFaultDetectionCounter_GetFaultDetectionCounter_Event_DTC_0xa28b97: start-on-event=DemSatellite_0InternalBehavior/GetFaultDetectionCounter, operation=Event_DTC_0xa28b97.GetFaultDetectionCounter
        OpEventGetFaultDetectionCounter_GetFaultDetectionCounter_EvtInfo_DTC_0xa28b16: start-on-event=DemSatellite_0InternalBehavior/GetFaultDetectionCounter, operation=EvtInfo_DTC_0xa28b16.GetFaultDetectionCounter
        OpEventGetFaultDetectionCounter_GetFaultDetectionCounter_Event_DTC_0xa28b16: start-on-event=DemSatellite_0InternalBehavior/GetFaultDetectionCounter, operation=Event_DTC_0xa28b16.GetFaultDetectionCounter
        OpEventGetFaultDetectionCounter_GetFaultDetectionCounter_EvtInfo_DTC_0xc42708: start-on-event=DemSatellite_0InternalBehavior/GetFaultDetectionCounter, operation=EvtInfo_DTC_0xc42708.GetFaultDetectionCounter
        OpEventGetFaultDetectionCounter_GetFaultDetectionCounter_Event_DTC_0xc42708: start-on-event=DemSatellite_0InternalBehavior/GetFaultDetectionCounter, operation=Event_DTC_0xc42708.GetFaultDetectionCounter
        OpEventGetFaultDetectionCounter_GetFaultDetectionCounter_EvtInfo_DTC_0xa28b17: start-on-event=DemSatellite_0InternalBehavior/GetFaultDetectionCounter, operation=EvtInfo_DTC_0xa28b17.GetFaultDetectionCounter
        OpEventGetFaultDetectionCounter_GetFaultDetectionCounter_Event_DTC_0xa28b17: start-on-event=DemSatellite_0InternalBehavior/GetFaultDetectionCounter, operation=Event_DTC_0xa28b17.GetFaultDetectionCounter
        OpEventGetFaultDetectionCounter_GetFaultDetectionCounter_GeneralEvtInfo: start-on-event=DemSatellite_0InternalBehavior/GetFaultDetectionCounter, operation=GeneralEvtInfo.GetFaultDetectionCounter
        OpEventGetEventFreezeFrameDataEx_GetEventFreezeFrameDataEx_EvtInfo_SPI_E_HARDWARE_ERROR: start-on-event=DemSatellite_0InternalBehavior/GetEventFreezeFrameDataEx, operation=EvtInfo_SPI_E_HARDWARE_ERROR.GetEventFreezeFrameDataEx
        OpEventGetEventFreezeFrameDataEx_GetEventFreezeFrameDataEx_EvtInfo_WDGM_E_MONITORING: start-on-event=DemSatellite_0InternalBehavior/GetEventFreezeFrameDataEx, operation=EvtInfo_WDGM_E_MONITORING.GetEventFreezeFrameDataEx
        OpEventGetEventFreezeFrameDataEx_GetEventFreezeFrameDataEx_EvtInfo_WDGM_E_IMPROPER_CALLER: start-on-event=DemSatellite_0InternalBehavior/GetEventFreezeFrameDataEx, operation=EvtInfo_WDGM_E_IMPROPER_CALLER.GetEventFreezeFrameDataEx
        OpEventGetEventFreezeFrameDataEx_GetEventFreezeFrameDataEx_EvtInfo_DTC_0x1ca000: start-on-event=DemSatellite_0InternalBehavior/GetEventFreezeFrameDataEx, operation=EvtInfo_DTC_0x1ca000.GetEventFreezeFrameDataEx
        OpEventGetEventFreezeFrameDataEx_GetEventFreezeFrameDataEx_Event_DTC_0x1ca000: start-on-event=DemSatellite_0InternalBehavior/GetEventFreezeFrameDataEx, operation=Event_DTC_0x1ca000.GetEventFreezeFrameDataEx
        OpEventGetEventFreezeFrameDataEx_GetEventFreezeFrameDataEx_EvtInfo_DTC_0xa10b00: start-on-event=DemSatellite_0InternalBehavior/GetEventFreezeFrameDataEx, operation=EvtInfo_DTC_0xa10b00.GetEventFreezeFrameDataEx
        OpEventGetEventFreezeFrameDataEx_GetEventFreezeFrameDataEx_Event_DTC_0xa10b00: start-on-event=DemSatellite_0InternalBehavior/GetEventFreezeFrameDataEx, operation=Event_DTC_0xa10b00.GetEventFreezeFrameDataEx
        OpEventGetEventFreezeFrameDataEx_GetEventFreezeFrameDataEx_EvtInfo_DTC_0xc44286: start-on-event=DemSatellite_0InternalBehavior/GetEventFreezeFrameDataEx, operation=EvtInfo_DTC_0xc44286.GetEventFreezeFrameDataEx
        OpEventGetEventFreezeFrameDataEx_GetEventFreezeFrameDataEx_Event_DTC_0xc44286: start-on-event=DemSatellite_0InternalBehavior/GetEventFreezeFrameDataEx, operation=Event_DTC_0xc44286.GetEventFreezeFrameDataEx
        OpEventGetEventFreezeFrameDataEx_GetEventFreezeFrameDataEx_EvtInfo_DTC_0xa10d00: start-on-event=DemSatellite_0InternalBehavior/GetEventFreezeFrameDataEx, operation=EvtInfo_DTC_0xa10d00.GetEventFreezeFrameDataEx
        OpEventGetEventFreezeFrameDataEx_GetEventFreezeFrameDataEx_Event_DTC_0xa10d00: start-on-event=DemSatellite_0InternalBehavior/GetEventFreezeFrameDataEx, operation=Event_DTC_0xa10d00.GetEventFreezeFrameDataEx
        OpEventGetEventFreezeFrameDataEx_GetEventFreezeFrameDataEx_EvtInfo_DTC_0xa28b45: start-on-event=DemSatellite_0InternalBehavior/GetEventFreezeFrameDataEx, operation=EvtInfo_DTC_0xa28b45.GetEventFreezeFrameDataEx
        OpEventGetEventFreezeFrameDataEx_GetEventFreezeFrameDataEx_Event_DTC_0xa28b45: start-on-event=DemSatellite_0InternalBehavior/GetEventFreezeFrameDataEx, operation=Event_DTC_0xa28b45.GetEventFreezeFrameDataEx
        OpEventGetEventFreezeFrameDataEx_GetEventFreezeFrameDataEx_EvtInfo_DTC_0xc45208: start-on-event=DemSatellite_0InternalBehavior/GetEventFreezeFrameDataEx, operation=EvtInfo_DTC_0xc45208.GetEventFreezeFrameDataEx
        OpEventGetEventFreezeFrameDataEx_GetEventFreezeFrameDataEx_Event_DTC_0xc45208: start-on-event=DemSatellite_0InternalBehavior/GetEventFreezeFrameDataEx, operation=Event_DTC_0xc45208.GetEventFreezeFrameDataEx
        OpEventGetEventFreezeFrameDataEx_GetEventFreezeFrameDataEx_EvtInfo_DTC_0xa28b49: start-on-event=DemSatellite_0InternalBehavior/GetEventFreezeFrameDataEx, operation=EvtInfo_DTC_0xa28b49.GetEventFreezeFrameDataEx
        OpEventGetEventFreezeFrameDataEx_GetEventFreezeFrameDataEx_Event_DTC_0xa28b49: start-on-event=DemSatellite_0InternalBehavior/GetEventFreezeFrameDataEx, operation=Event_DTC_0xa28b49.GetEventFreezeFrameDataEx
        OpEventGetEventFreezeFrameDataEx_GetEventFreezeFrameDataEx_EvtInfo_DTC_0xa28b47: start-on-event=DemSatellite_0InternalBehavior/GetEventFreezeFrameDataEx, operation=EvtInfo_DTC_0xa28b47.GetEventFreezeFrameDataEx
        OpEventGetEventFreezeFrameDataEx_GetEventFreezeFrameDataEx_Event_DTC_0xa28b47: start-on-event=DemSatellite_0InternalBehavior/GetEventFreezeFrameDataEx, operation=Event_DTC_0xa28b47.GetEventFreezeFrameDataEx
        OpEventGetEventFreezeFrameDataEx_GetEventFreezeFrameDataEx_EvtInfo_DTC_0xc41608: start-on-event=DemSatellite_0InternalBehavior/GetEventFreezeFrameDataEx, operation=EvtInfo_DTC_0xc41608.GetEventFreezeFrameDataEx
        OpEventGetEventFreezeFrameDataEx_GetEventFreezeFrameDataEx_Event_DTC_0xc41608: start-on-event=DemSatellite_0InternalBehavior/GetEventFreezeFrameDataEx, operation=Event_DTC_0xc41608.GetEventFreezeFrameDataEx
        OpEventGetEventFreezeFrameDataEx_GetEventFreezeFrameDataEx_EvtInfo_DTC_0xc20287: start-on-event=DemSatellite_0InternalBehavior/GetEventFreezeFrameDataEx, operation=EvtInfo_DTC_0xc20287.GetEventFreezeFrameDataEx
        OpEventGetEventFreezeFrameDataEx_GetEventFreezeFrameDataEx_Event_DTC_0xc20287: start-on-event=DemSatellite_0InternalBehavior/GetEventFreezeFrameDataEx, operation=Event_DTC_0xc20287.GetEventFreezeFrameDataEx
        OpEventGetEventFreezeFrameDataEx_GetEventFreezeFrameDataEx_EvtInfo_DTC_0xa20400: start-on-event=DemSatellite_0InternalBehavior/GetEventFreezeFrameDataEx, operation=EvtInfo_DTC_0xa20400.GetEventFreezeFrameDataEx
        OpEventGetEventFreezeFrameDataEx_GetEventFreezeFrameDataEx_Event_DTC_0xa20400: start-on-event=DemSatellite_0InternalBehavior/GetEventFreezeFrameDataEx, operation=Event_DTC_0xa20400.GetEventFreezeFrameDataEx
        OpEventGetEventFreezeFrameDataEx_GetEventFreezeFrameDataEx_EvtInfo_DTC_0x9a6857: start-on-event=DemSatellite_0InternalBehavior/GetEventFreezeFrameDataEx, operation=EvtInfo_DTC_0x9a6857.GetEventFreezeFrameDataEx
        OpEventGetEventFreezeFrameDataEx_GetEventFreezeFrameDataEx_Event_DTC_0x9a6857: start-on-event=DemSatellite_0InternalBehavior/GetEventFreezeFrameDataEx, operation=Event_DTC_0x9a6857.GetEventFreezeFrameDataEx
        OpEventGetEventFreezeFrameDataEx_GetEventFreezeFrameDataEx_EvtInfo_DTC_0xa28b71: start-on-event=DemSatellite_0InternalBehavior/GetEventFreezeFrameDataEx, operation=EvtInfo_DTC_0xa28b71.GetEventFreezeFrameDataEx
        OpEventGetEventFreezeFrameDataEx_GetEventFreezeFrameDataEx_Event_DTC_0xa28b71: start-on-event=DemSatellite_0InternalBehavior/GetEventFreezeFrameDataEx, operation=Event_DTC_0xa28b71.GetEventFreezeFrameDataEx
        OpEventGetEventFreezeFrameDataEx_GetEventFreezeFrameDataEx_EvtInfo_DTC_0xa10a00: start-on-event=DemSatellite_0InternalBehavior/GetEventFreezeFrameDataEx, operation=EvtInfo_DTC_0xa10a00.GetEventFreezeFrameDataEx
        OpEventGetEventFreezeFrameDataEx_GetEventFreezeFrameDataEx_Event_DTC_0xa10a00: start-on-event=DemSatellite_0InternalBehavior/GetEventFreezeFrameDataEx, operation=Event_DTC_0xa10a00.GetEventFreezeFrameDataEx
        OpEventGetEventFreezeFrameDataEx_GetEventFreezeFrameDataEx_EvtInfo_DTC_0xd12081: start-on-event=DemSatellite_0InternalBehavior/GetEventFreezeFrameDataEx, operation=EvtInfo_DTC_0xd12081.GetEventFreezeFrameDataEx
        OpEventGetEventFreezeFrameDataEx_GetEventFreezeFrameDataEx_Event_DTC_0xd12081: start-on-event=DemSatellite_0InternalBehavior/GetEventFreezeFrameDataEx, operation=Event_DTC_0xd12081.GetEventFreezeFrameDataEx
        OpEventGetEventFreezeFrameDataEx_GetEventFreezeFrameDataEx_EvtInfo_DTC_0xd12083: start-on-event=DemSatellite_0InternalBehavior/GetEventFreezeFrameDataEx, operation=EvtInfo_DTC_0xd12083.GetEventFreezeFrameDataEx
        OpEventGetEventFreezeFrameDataEx_GetEventFreezeFrameDataEx_Event_DTC_0xd12083: start-on-event=DemSatellite_0InternalBehavior/GetEventFreezeFrameDataEx, operation=Event_DTC_0xd12083.GetEventFreezeFrameDataEx
        OpEventGetEventFreezeFrameDataEx_GetEventFreezeFrameDataEx_EvtInfo_DTC_0xa10e00: start-on-event=DemSatellite_0InternalBehavior/GetEventFreezeFrameDataEx, operation=EvtInfo_DTC_0xa10e00.GetEventFreezeFrameDataEx
        OpEventGetEventFreezeFrameDataEx_GetEventFreezeFrameDataEx_Event_DTC_0xa10e00: start-on-event=DemSatellite_0InternalBehavior/GetEventFreezeFrameDataEx, operation=Event_DTC_0xa10e00.GetEventFreezeFrameDataEx
        OpEventGetEventFreezeFrameDataEx_GetEventFreezeFrameDataEx_EvtInfo_DTC_0x164456: start-on-event=DemSatellite_0InternalBehavior/GetEventFreezeFrameDataEx, operation=EvtInfo_DTC_0x164456.GetEventFreezeFrameDataEx
        OpEventGetEventFreezeFrameDataEx_GetEventFreezeFrameDataEx_Event_DTC_0x164456: start-on-event=DemSatellite_0InternalBehavior/GetEventFreezeFrameDataEx, operation=Event_DTC_0x164456.GetEventFreezeFrameDataEx
        OpEventGetEventFreezeFrameDataEx_GetEventFreezeFrameDataEx_EvtInfo_DTC_0xa28bfa: start-on-event=DemSatellite_0InternalBehavior/GetEventFreezeFrameDataEx, operation=EvtInfo_DTC_0xa28bfa.GetEventFreezeFrameDataEx
        OpEventGetEventFreezeFrameDataEx_GetEventFreezeFrameDataEx_Event_DTC_0xa28bfa: start-on-event=DemSatellite_0InternalBehavior/GetEventFreezeFrameDataEx, operation=Event_DTC_0xa28bfa.GetEventFreezeFrameDataEx
        OpEventGetEventFreezeFrameDataEx_GetEventFreezeFrameDataEx_EvtInfo_DTC_0xc15587: start-on-event=DemSatellite_0InternalBehavior/GetEventFreezeFrameDataEx, operation=EvtInfo_DTC_0xc15587.GetEventFreezeFrameDataEx
        OpEventGetEventFreezeFrameDataEx_GetEventFreezeFrameDataEx_Event_DTC_0xc15587: start-on-event=DemSatellite_0InternalBehavior/GetEventFreezeFrameDataEx, operation=Event_DTC_0xc15587.GetEventFreezeFrameDataEx
        OpEventGetEventFreezeFrameDataEx_GetEventFreezeFrameDataEx_EvtInfo_DTC_0xd22488: start-on-event=DemSatellite_0InternalBehavior/GetEventFreezeFrameDataEx, operation=EvtInfo_DTC_0xd22488.GetEventFreezeFrameDataEx
        OpEventGetEventFreezeFrameDataEx_GetEventFreezeFrameDataEx_Event_DTC_0xd22488: start-on-event=DemSatellite_0InternalBehavior/GetEventFreezeFrameDataEx, operation=Event_DTC_0xd22488.GetEventFreezeFrameDataEx
        OpEventGetEventFreezeFrameDataEx_GetEventFreezeFrameDataEx_EvtInfo_DTC_0xd12087: start-on-event=DemSatellite_0InternalBehavior/GetEventFreezeFrameDataEx, operation=EvtInfo_DTC_0xd12087.GetEventFreezeFrameDataEx
        OpEventGetEventFreezeFrameDataEx_GetEventFreezeFrameDataEx_Event_DTC_0xd12087: start-on-event=DemSatellite_0InternalBehavior/GetEventFreezeFrameDataEx, operation=Event_DTC_0xd12087.GetEventFreezeFrameDataEx
        OpEventGetEventFreezeFrameDataEx_GetEventFreezeFrameDataEx_EvtInfo_DTC_0xc11587: start-on-event=DemSatellite_0InternalBehavior/GetEventFreezeFrameDataEx, operation=EvtInfo_DTC_0xc11587.GetEventFreezeFrameDataEx
        OpEventGetEventFreezeFrameDataEx_GetEventFreezeFrameDataEx_Event_DTC_0xc11587: start-on-event=DemSatellite_0InternalBehavior/GetEventFreezeFrameDataEx, operation=Event_DTC_0xc11587.GetEventFreezeFrameDataEx
        OpEventGetEventFreezeFrameDataEx_GetEventFreezeFrameDataEx_EvtInfo_DTC_0xc15187: start-on-event=DemSatellite_0InternalBehavior/GetEventFreezeFrameDataEx, operation=EvtInfo_DTC_0xc15187.GetEventFreezeFrameDataEx
        OpEventGetEventFreezeFrameDataEx_GetEventFreezeFrameDataEx_Event_DTC_0xc15187: start-on-event=DemSatellite_0InternalBehavior/GetEventFreezeFrameDataEx, operation=Event_DTC_0xc15187.GetEventFreezeFrameDataEx
        OpEventGetEventFreezeFrameDataEx_GetEventFreezeFrameDataEx_EvtInfo_DTC_0xc20187: start-on-event=DemSatellite_0InternalBehavior/GetEventFreezeFrameDataEx, operation=EvtInfo_DTC_0xc20187.GetEventFreezeFrameDataEx
        OpEventGetEventFreezeFrameDataEx_GetEventFreezeFrameDataEx_Event_DTC_0xc20187: start-on-event=DemSatellite_0InternalBehavior/GetEventFreezeFrameDataEx, operation=Event_DTC_0xc20187.GetEventFreezeFrameDataEx
        OpEventGetEventFreezeFrameDataEx_GetEventFreezeFrameDataEx_EvtInfo_DTC_0xa28b4b: start-on-event=DemSatellite_0InternalBehavior/GetEventFreezeFrameDataEx, operation=EvtInfo_DTC_0xa28b4b.GetEventFreezeFrameDataEx
        OpEventGetEventFreezeFrameDataEx_GetEventFreezeFrameDataEx_Event_DTC_0xa28b4b: start-on-event=DemSatellite_0InternalBehavior/GetEventFreezeFrameDataEx, operation=Event_DTC_0xa28b4b.GetEventFreezeFrameDataEx
        OpEventGetEventFreezeFrameDataEx_GetEventFreezeFrameDataEx_EvtInfo_DTC_0xa28b96: start-on-event=DemSatellite_0InternalBehavior/GetEventFreezeFrameDataEx, operation=EvtInfo_DTC_0xa28b96.GetEventFreezeFrameDataEx
        OpEventGetEventFreezeFrameDataEx_GetEventFreezeFrameDataEx_Event_DTC_0xa28b96: start-on-event=DemSatellite_0InternalBehavior/GetEventFreezeFrameDataEx, operation=Event_DTC_0xa28b96.GetEventFreezeFrameDataEx
        OpEventGetEventFreezeFrameDataEx_GetEventFreezeFrameDataEx_EvtInfo_DTC_0xc12287: start-on-event=DemSatellite_0InternalBehavior/GetEventFreezeFrameDataEx, operation=EvtInfo_DTC_0xc12287.GetEventFreezeFrameDataEx
        OpEventGetEventFreezeFrameDataEx_GetEventFreezeFrameDataEx_Event_DTC_0xc12287: start-on-event=DemSatellite_0InternalBehavior/GetEventFreezeFrameDataEx, operation=Event_DTC_0xc12287.GetEventFreezeFrameDataEx
        OpEventGetEventFreezeFrameDataEx_GetEventFreezeFrameDataEx_EvtInfo_DTC_0xc16887: start-on-event=DemSatellite_0InternalBehavior/GetEventFreezeFrameDataEx, operation=EvtInfo_DTC_0xc16887.GetEventFreezeFrameDataEx
        OpEventGetEventFreezeFrameDataEx_GetEventFreezeFrameDataEx_Event_DTC_0xc16887: start-on-event=DemSatellite_0InternalBehavior/GetEventFreezeFrameDataEx, operation=Event_DTC_0xc16887.GetEventFreezeFrameDataEx
        OpEventGetEventFreezeFrameDataEx_GetEventFreezeFrameDataEx_EvtInfo_DTC_0xa28b97: start-on-event=DemSatellite_0InternalBehavior/GetEventFreezeFrameDataEx, operation=EvtInfo_DTC_0xa28b97.GetEventFreezeFrameDataEx
        OpEventGetEventFreezeFrameDataEx_GetEventFreezeFrameDataEx_Event_DTC_0xa28b97: start-on-event=DemSatellite_0InternalBehavior/GetEventFreezeFrameDataEx, operation=Event_DTC_0xa28b97.GetEventFreezeFrameDataEx
        OpEventGetEventFreezeFrameDataEx_GetEventFreezeFrameDataEx_EvtInfo_DTC_0xa28b16: start-on-event=DemSatellite_0InternalBehavior/GetEventFreezeFrameDataEx, operation=EvtInfo_DTC_0xa28b16.GetEventFreezeFrameDataEx
        OpEventGetEventFreezeFrameDataEx_GetEventFreezeFrameDataEx_Event_DTC_0xa28b16: start-on-event=DemSatellite_0InternalBehavior/GetEventFreezeFrameDataEx, operation=Event_DTC_0xa28b16.GetEventFreezeFrameDataEx
        OpEventGetEventFreezeFrameDataEx_GetEventFreezeFrameDataEx_EvtInfo_DTC_0xc42708: start-on-event=DemSatellite_0InternalBehavior/GetEventFreezeFrameDataEx, operation=EvtInfo_DTC_0xc42708.GetEventFreezeFrameDataEx
        OpEventGetEventFreezeFrameDataEx_GetEventFreezeFrameDataEx_Event_DTC_0xc42708: start-on-event=DemSatellite_0InternalBehavior/GetEventFreezeFrameDataEx, operation=Event_DTC_0xc42708.GetEventFreezeFrameDataEx
        OpEventGetEventFreezeFrameDataEx_GetEventFreezeFrameDataEx_EvtInfo_DTC_0xa28b17: start-on-event=DemSatellite_0InternalBehavior/GetEventFreezeFrameDataEx, operation=EvtInfo_DTC_0xa28b17.GetEventFreezeFrameDataEx
        OpEventGetEventFreezeFrameDataEx_GetEventFreezeFrameDataEx_Event_DTC_0xa28b17: start-on-event=DemSatellite_0InternalBehavior/GetEventFreezeFrameDataEx, operation=Event_DTC_0xa28b17.GetEventFreezeFrameDataEx
        OpEventGetEventFreezeFrameDataEx_GetEventFreezeFrameDataEx_GeneralEvtInfo: start-on-event=DemSatellite_0InternalBehavior/GetEventFreezeFrameDataEx, operation=GeneralEvtInfo.GetEventFreezeFrameDataEx
        OpEventGetEventExtendedDataRecordEx_GetEventExtendedDataRecordEx_EvtInfo_SPI_E_HARDWARE_ERROR: start-on-event=DemSatellite_0InternalBehavior/GetEventExtendedDataRecordEx, operation=EvtInfo_SPI_E_HARDWARE_ERROR.GetEventExtendedDataRecordEx
        OpEventGetEventExtendedDataRecordEx_GetEventExtendedDataRecordEx_EvtInfo_WDGM_E_MONITORING: start-on-event=DemSatellite_0InternalBehavior/GetEventExtendedDataRecordEx, operation=EvtInfo_WDGM_E_MONITORING.GetEventExtendedDataRecordEx
        OpEventGetEventExtendedDataRecordEx_GetEventExtendedDataRecordEx_EvtInfo_WDGM_E_IMPROPER_CALLER: start-on-event=DemSatellite_0InternalBehavior/GetEventExtendedDataRecordEx, operation=EvtInfo_WDGM_E_IMPROPER_CALLER.GetEventExtendedDataRecordEx
        OpEventGetEventExtendedDataRecordEx_GetEventExtendedDataRecordEx_EvtInfo_DTC_0x1ca000: start-on-event=DemSatellite_0InternalBehavior/GetEventExtendedDataRecordEx, operation=EvtInfo_DTC_0x1ca000.GetEventExtendedDataRecordEx
        OpEventGetEventExtendedDataRecordEx_GetEventExtendedDataRecordEx_Event_DTC_0x1ca000: start-on-event=DemSatellite_0InternalBehavior/GetEventExtendedDataRecordEx, operation=Event_DTC_0x1ca000.GetEventExtendedDataRecordEx
        OpEventGetEventExtendedDataRecordEx_GetEventExtendedDataRecordEx_EvtInfo_DTC_0xa10b00: start-on-event=DemSatellite_0InternalBehavior/GetEventExtendedDataRecordEx, operation=EvtInfo_DTC_0xa10b00.GetEventExtendedDataRecordEx
        OpEventGetEventExtendedDataRecordEx_GetEventExtendedDataRecordEx_Event_DTC_0xa10b00: start-on-event=DemSatellite_0InternalBehavior/GetEventExtendedDataRecordEx, operation=Event_DTC_0xa10b00.GetEventExtendedDataRecordEx
        OpEventGetEventExtendedDataRecordEx_GetEventExtendedDataRecordEx_EvtInfo_DTC_0xc44286: start-on-event=DemSatellite_0InternalBehavior/GetEventExtendedDataRecordEx, operation=EvtInfo_DTC_0xc44286.GetEventExtendedDataRecordEx
        OpEventGetEventExtendedDataRecordEx_GetEventExtendedDataRecordEx_Event_DTC_0xc44286: start-on-event=DemSatellite_0InternalBehavior/GetEventExtendedDataRecordEx, operation=Event_DTC_0xc44286.GetEventExtendedDataRecordEx
        OpEventGetEventExtendedDataRecordEx_GetEventExtendedDataRecordEx_EvtInfo_DTC_0xa10d00: start-on-event=DemSatellite_0InternalBehavior/GetEventExtendedDataRecordEx, operation=EvtInfo_DTC_0xa10d00.GetEventExtendedDataRecordEx
        OpEventGetEventExtendedDataRecordEx_GetEventExtendedDataRecordEx_Event_DTC_0xa10d00: start-on-event=DemSatellite_0InternalBehavior/GetEventExtendedDataRecordEx, operation=Event_DTC_0xa10d00.GetEventExtendedDataRecordEx
        OpEventGetEventExtendedDataRecordEx_GetEventExtendedDataRecordEx_EvtInfo_DTC_0xa28b45: start-on-event=DemSatellite_0InternalBehavior/GetEventExtendedDataRecordEx, operation=EvtInfo_DTC_0xa28b45.GetEventExtendedDataRecordEx
        OpEventGetEventExtendedDataRecordEx_GetEventExtendedDataRecordEx_Event_DTC_0xa28b45: start-on-event=DemSatellite_0InternalBehavior/GetEventExtendedDataRecordEx, operation=Event_DTC_0xa28b45.GetEventExtendedDataRecordEx
        OpEventGetEventExtendedDataRecordEx_GetEventExtendedDataRecordEx_EvtInfo_DTC_0xc45208: start-on-event=DemSatellite_0InternalBehavior/GetEventExtendedDataRecordEx, operation=EvtInfo_DTC_0xc45208.GetEventExtendedDataRecordEx
        OpEventGetEventExtendedDataRecordEx_GetEventExtendedDataRecordEx_Event_DTC_0xc45208: start-on-event=DemSatellite_0InternalBehavior/GetEventExtendedDataRecordEx, operation=Event_DTC_0xc45208.GetEventExtendedDataRecordEx
        OpEventGetEventExtendedDataRecordEx_GetEventExtendedDataRecordEx_EvtInfo_DTC_0xa28b49: start-on-event=DemSatellite_0InternalBehavior/GetEventExtendedDataRecordEx, operation=EvtInfo_DTC_0xa28b49.GetEventExtendedDataRecordEx
        OpEventGetEventExtendedDataRecordEx_GetEventExtendedDataRecordEx_Event_DTC_0xa28b49: start-on-event=DemSatellite_0InternalBehavior/GetEventExtendedDataRecordEx, operation=Event_DTC_0xa28b49.GetEventExtendedDataRecordEx
        OpEventGetEventExtendedDataRecordEx_GetEventExtendedDataRecordEx_EvtInfo_DTC_0xa28b47: start-on-event=DemSatellite_0InternalBehavior/GetEventExtendedDataRecordEx, operation=EvtInfo_DTC_0xa28b47.GetEventExtendedDataRecordEx
        OpEventGetEventExtendedDataRecordEx_GetEventExtendedDataRecordEx_Event_DTC_0xa28b47: start-on-event=DemSatellite_0InternalBehavior/GetEventExtendedDataRecordEx, operation=Event_DTC_0xa28b47.GetEventExtendedDataRecordEx
        OpEventGetEventExtendedDataRecordEx_GetEventExtendedDataRecordEx_EvtInfo_DTC_0xc41608: start-on-event=DemSatellite_0InternalBehavior/GetEventExtendedDataRecordEx, operation=EvtInfo_DTC_0xc41608.GetEventExtendedDataRecordEx
        OpEventGetEventExtendedDataRecordEx_GetEventExtendedDataRecordEx_Event_DTC_0xc41608: start-on-event=DemSatellite_0InternalBehavior/GetEventExtendedDataRecordEx, operation=Event_DTC_0xc41608.GetEventExtendedDataRecordEx
        OpEventGetEventExtendedDataRecordEx_GetEventExtendedDataRecordEx_EvtInfo_DTC_0xc20287: start-on-event=DemSatellite_0InternalBehavior/GetEventExtendedDataRecordEx, operation=EvtInfo_DTC_0xc20287.GetEventExtendedDataRecordEx
        OpEventGetEventExtendedDataRecordEx_GetEventExtendedDataRecordEx_Event_DTC_0xc20287: start-on-event=DemSatellite_0InternalBehavior/GetEventExtendedDataRecordEx, operation=Event_DTC_0xc20287.GetEventExtendedDataRecordEx
        OpEventGetEventExtendedDataRecordEx_GetEventExtendedDataRecordEx_EvtInfo_DTC_0xa20400: start-on-event=DemSatellite_0InternalBehavior/GetEventExtendedDataRecordEx, operation=EvtInfo_DTC_0xa20400.GetEventExtendedDataRecordEx
        OpEventGetEventExtendedDataRecordEx_GetEventExtendedDataRecordEx_Event_DTC_0xa20400: start-on-event=DemSatellite_0InternalBehavior/GetEventExtendedDataRecordEx, operation=Event_DTC_0xa20400.GetEventExtendedDataRecordEx
        OpEventGetEventExtendedDataRecordEx_GetEventExtendedDataRecordEx_EvtInfo_DTC_0x9a6857: start-on-event=DemSatellite_0InternalBehavior/GetEventExtendedDataRecordEx, operation=EvtInfo_DTC_0x9a6857.GetEventExtendedDataRecordEx
        OpEventGetEventExtendedDataRecordEx_GetEventExtendedDataRecordEx_Event_DTC_0x9a6857: start-on-event=DemSatellite_0InternalBehavior/GetEventExtendedDataRecordEx, operation=Event_DTC_0x9a6857.GetEventExtendedDataRecordEx
        OpEventGetEventExtendedDataRecordEx_GetEventExtendedDataRecordEx_EvtInfo_DTC_0xa28b71: start-on-event=DemSatellite_0InternalBehavior/GetEventExtendedDataRecordEx, operation=EvtInfo_DTC_0xa28b71.GetEventExtendedDataRecordEx
        OpEventGetEventExtendedDataRecordEx_GetEventExtendedDataRecordEx_Event_DTC_0xa28b71: start-on-event=DemSatellite_0InternalBehavior/GetEventExtendedDataRecordEx, operation=Event_DTC_0xa28b71.GetEventExtendedDataRecordEx
        OpEventGetEventExtendedDataRecordEx_GetEventExtendedDataRecordEx_EvtInfo_DTC_0xa10a00: start-on-event=DemSatellite_0InternalBehavior/GetEventExtendedDataRecordEx, operation=EvtInfo_DTC_0xa10a00.GetEventExtendedDataRecordEx
        OpEventGetEventExtendedDataRecordEx_GetEventExtendedDataRecordEx_Event_DTC_0xa10a00: start-on-event=DemSatellite_0InternalBehavior/GetEventExtendedDataRecordEx, operation=Event_DTC_0xa10a00.GetEventExtendedDataRecordEx
        OpEventGetEventExtendedDataRecordEx_GetEventExtendedDataRecordEx_EvtInfo_DTC_0xd12081: start-on-event=DemSatellite_0InternalBehavior/GetEventExtendedDataRecordEx, operation=EvtInfo_DTC_0xd12081.GetEventExtendedDataRecordEx
        OpEventGetEventExtendedDataRecordEx_GetEventExtendedDataRecordEx_Event_DTC_0xd12081: start-on-event=DemSatellite_0InternalBehavior/GetEventExtendedDataRecordEx, operation=Event_DTC_0xd12081.GetEventExtendedDataRecordEx
        OpEventGetEventExtendedDataRecordEx_GetEventExtendedDataRecordEx_EvtInfo_DTC_0xd12083: start-on-event=DemSatellite_0InternalBehavior/GetEventExtendedDataRecordEx, operation=EvtInfo_DTC_0xd12083.GetEventExtendedDataRecordEx
        OpEventGetEventExtendedDataRecordEx_GetEventExtendedDataRecordEx_Event_DTC_0xd12083: start-on-event=DemSatellite_0InternalBehavior/GetEventExtendedDataRecordEx, operation=Event_DTC_0xd12083.GetEventExtendedDataRecordEx
        OpEventGetEventExtendedDataRecordEx_GetEventExtendedDataRecordEx_EvtInfo_DTC_0xa10e00: start-on-event=DemSatellite_0InternalBehavior/GetEventExtendedDataRecordEx, operation=EvtInfo_DTC_0xa10e00.GetEventExtendedDataRecordEx
        OpEventGetEventExtendedDataRecordEx_GetEventExtendedDataRecordEx_Event_DTC_0xa10e00: start-on-event=DemSatellite_0InternalBehavior/GetEventExtendedDataRecordEx, operation=Event_DTC_0xa10e00.GetEventExtendedDataRecordEx
        OpEventGetEventExtendedDataRecordEx_GetEventExtendedDataRecordEx_EvtInfo_DTC_0x164456: start-on-event=DemSatellite_0InternalBehavior/GetEventExtendedDataRecordEx, operation=EvtInfo_DTC_0x164456.GetEventExtendedDataRecordEx
        OpEventGetEventExtendedDataRecordEx_GetEventExtendedDataRecordEx_Event_DTC_0x164456: start-on-event=DemSatellite_0InternalBehavior/GetEventExtendedDataRecordEx, operation=Event_DTC_0x164456.GetEventExtendedDataRecordEx
        OpEventGetEventExtendedDataRecordEx_GetEventExtendedDataRecordEx_EvtInfo_DTC_0xa28bfa: start-on-event=DemSatellite_0InternalBehavior/GetEventExtendedDataRecordEx, operation=EvtInfo_DTC_0xa28bfa.GetEventExtendedDataRecordEx
        OpEventGetEventExtendedDataRecordEx_GetEventExtendedDataRecordEx_Event_DTC_0xa28bfa: start-on-event=DemSatellite_0InternalBehavior/GetEventExtendedDataRecordEx, operation=Event_DTC_0xa28bfa.GetEventExtendedDataRecordEx
        OpEventGetEventExtendedDataRecordEx_GetEventExtendedDataRecordEx_EvtInfo_DTC_0xc15587: start-on-event=DemSatellite_0InternalBehavior/GetEventExtendedDataRecordEx, operation=EvtInfo_DTC_0xc15587.GetEventExtendedDataRecordEx
        OpEventGetEventExtendedDataRecordEx_GetEventExtendedDataRecordEx_Event_DTC_0xc15587: start-on-event=DemSatellite_0InternalBehavior/GetEventExtendedDataRecordEx, operation=Event_DTC_0xc15587.GetEventExtendedDataRecordEx
        OpEventGetEventExtendedDataRecordEx_GetEventExtendedDataRecordEx_EvtInfo_DTC_0xd22488: start-on-event=DemSatellite_0InternalBehavior/GetEventExtendedDataRecordEx, operation=EvtInfo_DTC_0xd22488.GetEventExtendedDataRecordEx
        OpEventGetEventExtendedDataRecordEx_GetEventExtendedDataRecordEx_Event_DTC_0xd22488: start-on-event=DemSatellite_0InternalBehavior/GetEventExtendedDataRecordEx, operation=Event_DTC_0xd22488.GetEventExtendedDataRecordEx
        OpEventGetEventExtendedDataRecordEx_GetEventExtendedDataRecordEx_EvtInfo_DTC_0xd12087: start-on-event=DemSatellite_0InternalBehavior/GetEventExtendedDataRecordEx, operation=EvtInfo_DTC_0xd12087.GetEventExtendedDataRecordEx
        OpEventGetEventExtendedDataRecordEx_GetEventExtendedDataRecordEx_Event_DTC_0xd12087: start-on-event=DemSatellite_0InternalBehavior/GetEventExtendedDataRecordEx, operation=Event_DTC_0xd12087.GetEventExtendedDataRecordEx
        OpEventGetEventExtendedDataRecordEx_GetEventExtendedDataRecordEx_EvtInfo_DTC_0xc11587: start-on-event=DemSatellite_0InternalBehavior/GetEventExtendedDataRecordEx, operation=EvtInfo_DTC_0xc11587.GetEventExtendedDataRecordEx
        OpEventGetEventExtendedDataRecordEx_GetEventExtendedDataRecordEx_Event_DTC_0xc11587: start-on-event=DemSatellite_0InternalBehavior/GetEventExtendedDataRecordEx, operation=Event_DTC_0xc11587.GetEventExtendedDataRecordEx
        OpEventGetEventExtendedDataRecordEx_GetEventExtendedDataRecordEx_EvtInfo_DTC_0xc15187: start-on-event=DemSatellite_0InternalBehavior/GetEventExtendedDataRecordEx, operation=EvtInfo_DTC_0xc15187.GetEventExtendedDataRecordEx
        OpEventGetEventExtendedDataRecordEx_GetEventExtendedDataRecordEx_Event_DTC_0xc15187: start-on-event=DemSatellite_0InternalBehavior/GetEventExtendedDataRecordEx, operation=Event_DTC_0xc15187.GetEventExtendedDataRecordEx
        OpEventGetEventExtendedDataRecordEx_GetEventExtendedDataRecordEx_EvtInfo_DTC_0xc20187: start-on-event=DemSatellite_0InternalBehavior/GetEventExtendedDataRecordEx, operation=EvtInfo_DTC_0xc20187.GetEventExtendedDataRecordEx
        OpEventGetEventExtendedDataRecordEx_GetEventExtendedDataRecordEx_Event_DTC_0xc20187: start-on-event=DemSatellite_0InternalBehavior/GetEventExtendedDataRecordEx, operation=Event_DTC_0xc20187.GetEventExtendedDataRecordEx
        OpEventGetEventExtendedDataRecordEx_GetEventExtendedDataRecordEx_EvtInfo_DTC_0xa28b4b: start-on-event=DemSatellite_0InternalBehavior/GetEventExtendedDataRecordEx, operation=EvtInfo_DTC_0xa28b4b.GetEventExtendedDataRecordEx
        OpEventGetEventExtendedDataRecordEx_GetEventExtendedDataRecordEx_Event_DTC_0xa28b4b: start-on-event=DemSatellite_0InternalBehavior/GetEventExtendedDataRecordEx, operation=Event_DTC_0xa28b4b.GetEventExtendedDataRecordEx
        OpEventGetEventExtendedDataRecordEx_GetEventExtendedDataRecordEx_EvtInfo_DTC_0xa28b96: start-on-event=DemSatellite_0InternalBehavior/GetEventExtendedDataRecordEx, operation=EvtInfo_DTC_0xa28b96.GetEventExtendedDataRecordEx
        OpEventGetEventExtendedDataRecordEx_GetEventExtendedDataRecordEx_Event_DTC_0xa28b96: start-on-event=DemSatellite_0InternalBehavior/GetEventExtendedDataRecordEx, operation=Event_DTC_0xa28b96.GetEventExtendedDataRecordEx
        OpEventGetEventExtendedDataRecordEx_GetEventExtendedDataRecordEx_EvtInfo_DTC_0xc12287: start-on-event=DemSatellite_0InternalBehavior/GetEventExtendedDataRecordEx, operation=EvtInfo_DTC_0xc12287.GetEventExtendedDataRecordEx
        OpEventGetEventExtendedDataRecordEx_GetEventExtendedDataRecordEx_Event_DTC_0xc12287: start-on-event=DemSatellite_0InternalBehavior/GetEventExtendedDataRecordEx, operation=Event_DTC_0xc12287.GetEventExtendedDataRecordEx
        OpEventGetEventExtendedDataRecordEx_GetEventExtendedDataRecordEx_EvtInfo_DTC_0xc16887: start-on-event=DemSatellite_0InternalBehavior/GetEventExtendedDataRecordEx, operation=EvtInfo_DTC_0xc16887.GetEventExtendedDataRecordEx
        OpEventGetEventExtendedDataRecordEx_GetEventExtendedDataRecordEx_Event_DTC_0xc16887: start-on-event=DemSatellite_0InternalBehavior/GetEventExtendedDataRecordEx, operation=Event_DTC_0xc16887.GetEventExtendedDataRecordEx
        OpEventGetEventExtendedDataRecordEx_GetEventExtendedDataRecordEx_EvtInfo_DTC_0xa28b97: start-on-event=DemSatellite_0InternalBehavior/GetEventExtendedDataRecordEx, operation=EvtInfo_DTC_0xa28b97.GetEventExtendedDataRecordEx
        OpEventGetEventExtendedDataRecordEx_GetEventExtendedDataRecordEx_Event_DTC_0xa28b97: start-on-event=DemSatellite_0InternalBehavior/GetEventExtendedDataRecordEx, operation=Event_DTC_0xa28b97.GetEventExtendedDataRecordEx
        OpEventGetEventExtendedDataRecordEx_GetEventExtendedDataRecordEx_EvtInfo_DTC_0xa28b16: start-on-event=DemSatellite_0InternalBehavior/GetEventExtendedDataRecordEx, operation=EvtInfo_DTC_0xa28b16.GetEventExtendedDataRecordEx
        OpEventGetEventExtendedDataRecordEx_GetEventExtendedDataRecordEx_Event_DTC_0xa28b16: start-on-event=DemSatellite_0InternalBehavior/GetEventExtendedDataRecordEx, operation=Event_DTC_0xa28b16.GetEventExtendedDataRecordEx
        OpEventGetEventExtendedDataRecordEx_GetEventExtendedDataRecordEx_EvtInfo_DTC_0xc42708: start-on-event=DemSatellite_0InternalBehavior/GetEventExtendedDataRecordEx, operation=EvtInfo_DTC_0xc42708.GetEventExtendedDataRecordEx
        OpEventGetEventExtendedDataRecordEx_GetEventExtendedDataRecordEx_Event_DTC_0xc42708: start-on-event=DemSatellite_0InternalBehavior/GetEventExtendedDataRecordEx, operation=Event_DTC_0xc42708.GetEventExtendedDataRecordEx
        OpEventGetEventExtendedDataRecordEx_GetEventExtendedDataRecordEx_EvtInfo_DTC_0xa28b17: start-on-event=DemSatellite_0InternalBehavior/GetEventExtendedDataRecordEx, operation=EvtInfo_DTC_0xa28b17.GetEventExtendedDataRecordEx
        OpEventGetEventExtendedDataRecordEx_GetEventExtendedDataRecordEx_Event_DTC_0xa28b17: start-on-event=DemSatellite_0InternalBehavior/GetEventExtendedDataRecordEx, operation=Event_DTC_0xa28b17.GetEventExtendedDataRecordEx
        OpEventGetEventExtendedDataRecordEx_GetEventExtendedDataRecordEx_GeneralEvtInfo: start-on-event=DemSatellite_0InternalBehavior/GetEventExtendedDataRecordEx, operation=GeneralEvtInfo.GetEventExtendedDataRecordEx
        OpEventGetEventEnableCondition_GetEventEnableCondition_EvtInfo_SPI_E_HARDWARE_ERROR: start-on-event=DemSatellite_0InternalBehavior/GetEventEnableCondition, operation=EvtInfo_SPI_E_HARDWARE_ERROR.GetEventEnableCondition
        OpEventGetEventEnableCondition_GetEventEnableCondition_EvtInfo_WDGM_E_MONITORING: start-on-event=DemSatellite_0InternalBehavior/GetEventEnableCondition, operation=EvtInfo_WDGM_E_MONITORING.GetEventEnableCondition
        OpEventGetEventEnableCondition_GetEventEnableCondition_EvtInfo_WDGM_E_IMPROPER_CALLER: start-on-event=DemSatellite_0InternalBehavior/GetEventEnableCondition, operation=EvtInfo_WDGM_E_IMPROPER_CALLER.GetEventEnableCondition
        OpEventGetEventEnableCondition_GetEventEnableCondition_EvtInfo_DTC_0x1ca000: start-on-event=DemSatellite_0InternalBehavior/GetEventEnableCondition, operation=EvtInfo_DTC_0x1ca000.GetEventEnableCondition
        OpEventGetEventEnableCondition_GetEventEnableCondition_EvtInfo_DTC_0xa10b00: start-on-event=DemSatellite_0InternalBehavior/GetEventEnableCondition, operation=EvtInfo_DTC_0xa10b00.GetEventEnableCondition
        OpEventGetEventEnableCondition_GetEventEnableCondition_EvtInfo_DTC_0xc44286: start-on-event=DemSatellite_0InternalBehavior/GetEventEnableCondition, operation=EvtInfo_DTC_0xc44286.GetEventEnableCondition
        OpEventGetEventEnableCondition_GetEventEnableCondition_EvtInfo_DTC_0xa10d00: start-on-event=DemSatellite_0InternalBehavior/GetEventEnableCondition, operation=EvtInfo_DTC_0xa10d00.GetEventEnableCondition
        OpEventGetEventEnableCondition_GetEventEnableCondition_EvtInfo_DTC_0xa28b45: start-on-event=DemSatellite_0InternalBehavior/GetEventEnableCondition, operation=EvtInfo_DTC_0xa28b45.GetEventEnableCondition
        OpEventGetEventEnableCondition_GetEventEnableCondition_EvtInfo_DTC_0xc45208: start-on-event=DemSatellite_0InternalBehavior/GetEventEnableCondition, operation=EvtInfo_DTC_0xc45208.GetEventEnableCondition
        OpEventGetEventEnableCondition_GetEventEnableCondition_EvtInfo_DTC_0xa28b49: start-on-event=DemSatellite_0InternalBehavior/GetEventEnableCondition, operation=EvtInfo_DTC_0xa28b49.GetEventEnableCondition
        OpEventGetEventEnableCondition_GetEventEnableCondition_EvtInfo_DTC_0xa28b47: start-on-event=DemSatellite_0InternalBehavior/GetEventEnableCondition, operation=EvtInfo_DTC_0xa28b47.GetEventEnableCondition
        OpEventGetEventEnableCondition_GetEventEnableCondition_EvtInfo_DTC_0xc41608: start-on-event=DemSatellite_0InternalBehavior/GetEventEnableCondition, operation=EvtInfo_DTC_0xc41608.GetEventEnableCondition
        OpEventGetEventEnableCondition_GetEventEnableCondition_EvtInfo_DTC_0xc20287: start-on-event=DemSatellite_0InternalBehavior/GetEventEnableCondition, operation=EvtInfo_DTC_0xc20287.GetEventEnableCondition
        OpEventGetEventEnableCondition_GetEventEnableCondition_EvtInfo_DTC_0xa20400: start-on-event=DemSatellite_0InternalBehavior/GetEventEnableCondition, operation=EvtInfo_DTC_0xa20400.GetEventEnableCondition
        OpEventGetEventEnableCondition_GetEventEnableCondition_EvtInfo_DTC_0x9a6857: start-on-event=DemSatellite_0InternalBehavior/GetEventEnableCondition, operation=EvtInfo_DTC_0x9a6857.GetEventEnableCondition
        OpEventGetEventEnableCondition_GetEventEnableCondition_EvtInfo_DTC_0xa28b71: start-on-event=DemSatellite_0InternalBehavior/GetEventEnableCondition, operation=EvtInfo_DTC_0xa28b71.GetEventEnableCondition
        OpEventGetEventEnableCondition_GetEventEnableCondition_EvtInfo_DTC_0xa10a00: start-on-event=DemSatellite_0InternalBehavior/GetEventEnableCondition, operation=EvtInfo_DTC_0xa10a00.GetEventEnableCondition
        OpEventGetEventEnableCondition_GetEventEnableCondition_EvtInfo_DTC_0xd12081: start-on-event=DemSatellite_0InternalBehavior/GetEventEnableCondition, operation=EvtInfo_DTC_0xd12081.GetEventEnableCondition
        OpEventGetEventEnableCondition_GetEventEnableCondition_EvtInfo_DTC_0xd12083: start-on-event=DemSatellite_0InternalBehavior/GetEventEnableCondition, operation=EvtInfo_DTC_0xd12083.GetEventEnableCondition
        OpEventGetEventEnableCondition_GetEventEnableCondition_EvtInfo_DTC_0xa10e00: start-on-event=DemSatellite_0InternalBehavior/GetEventEnableCondition, operation=EvtInfo_DTC_0xa10e00.GetEventEnableCondition
        OpEventGetEventEnableCondition_GetEventEnableCondition_EvtInfo_DTC_0x164456: start-on-event=DemSatellite_0InternalBehavior/GetEventEnableCondition, operation=EvtInfo_DTC_0x164456.GetEventEnableCondition
        OpEventGetEventEnableCondition_GetEventEnableCondition_EvtInfo_DTC_0xa28bfa: start-on-event=DemSatellite_0InternalBehavior/GetEventEnableCondition, operation=EvtInfo_DTC_0xa28bfa.GetEventEnableCondition
        OpEventGetEventEnableCondition_GetEventEnableCondition_EvtInfo_DTC_0xc15587: start-on-event=DemSatellite_0InternalBehavior/GetEventEnableCondition, operation=EvtInfo_DTC_0xc15587.GetEventEnableCondition
        OpEventGetEventEnableCondition_GetEventEnableCondition_EvtInfo_DTC_0xd22488: start-on-event=DemSatellite_0InternalBehavior/GetEventEnableCondition, operation=EvtInfo_DTC_0xd22488.GetEventEnableCondition
        OpEventGetEventEnableCondition_GetEventEnableCondition_EvtInfo_DTC_0xd12087: start-on-event=DemSatellite_0InternalBehavior/GetEventEnableCondition, operation=EvtInfo_DTC_0xd12087.GetEventEnableCondition
        OpEventGetEventEnableCondition_GetEventEnableCondition_EvtInfo_DTC_0xc11587: start-on-event=DemSatellite_0InternalBehavior/GetEventEnableCondition, operation=EvtInfo_DTC_0xc11587.GetEventEnableCondition
        OpEventGetEventEnableCondition_GetEventEnableCondition_EvtInfo_DTC_0xc15187: start-on-event=DemSatellite_0InternalBehavior/GetEventEnableCondition, operation=EvtInfo_DTC_0xc15187.GetEventEnableCondition
        OpEventGetEventEnableCondition_GetEventEnableCondition_EvtInfo_DTC_0xc20187: start-on-event=DemSatellite_0InternalBehavior/GetEventEnableCondition, operation=EvtInfo_DTC_0xc20187.GetEventEnableCondition
        OpEventGetEventEnableCondition_GetEventEnableCondition_EvtInfo_DTC_0xa28b4b: start-on-event=DemSatellite_0InternalBehavior/GetEventEnableCondition, operation=EvtInfo_DTC_0xa28b4b.GetEventEnableCondition
        OpEventGetEventEnableCondition_GetEventEnableCondition_EvtInfo_DTC_0xa28b96: start-on-event=DemSatellite_0InternalBehavior/GetEventEnableCondition, operation=EvtInfo_DTC_0xa28b96.GetEventEnableCondition
        OpEventGetEventEnableCondition_GetEventEnableCondition_EvtInfo_DTC_0xc12287: start-on-event=DemSatellite_0InternalBehavior/GetEventEnableCondition, operation=EvtInfo_DTC_0xc12287.GetEventEnableCondition
        OpEventGetEventEnableCondition_GetEventEnableCondition_EvtInfo_DTC_0xc16887: start-on-event=DemSatellite_0InternalBehavior/GetEventEnableCondition, operation=EvtInfo_DTC_0xc16887.GetEventEnableCondition
        OpEventGetEventEnableCondition_GetEventEnableCondition_EvtInfo_DTC_0xa28b97: start-on-event=DemSatellite_0InternalBehavior/GetEventEnableCondition, operation=EvtInfo_DTC_0xa28b97.GetEventEnableCondition
        OpEventGetEventEnableCondition_GetEventEnableCondition_EvtInfo_DTC_0xa28b16: start-on-event=DemSatellite_0InternalBehavior/GetEventEnableCondition, operation=EvtInfo_DTC_0xa28b16.GetEventEnableCondition
        OpEventGetEventEnableCondition_GetEventEnableCondition_EvtInfo_DTC_0xc42708: start-on-event=DemSatellite_0InternalBehavior/GetEventEnableCondition, operation=EvtInfo_DTC_0xc42708.GetEventEnableCondition
        OpEventGetEventEnableCondition_GetEventEnableCondition_EvtInfo_DTC_0xa28b17: start-on-event=DemSatellite_0InternalBehavior/GetEventEnableCondition, operation=EvtInfo_DTC_0xa28b17.GetEventEnableCondition
        OpEventGetEventEnableCondition_GetEventEnableCondition_GeneralEvtInfo: start-on-event=DemSatellite_0InternalBehavior/GetEventEnableCondition, operation=GeneralEvtInfo.GetEventEnableCondition
        OpEventGetDebouncingOfEvent_GetDebouncingOfEvent_EvtInfo_SPI_E_HARDWARE_ERROR: start-on-event=DemSatellite_0InternalBehavior/GetDebouncingOfEvent, operation=EvtInfo_SPI_E_HARDWARE_ERROR.GetDebouncingOfEvent
        OpEventGetDebouncingOfEvent_GetDebouncingOfEvent_EvtInfo_WDGM_E_MONITORING: start-on-event=DemSatellite_0InternalBehavior/GetDebouncingOfEvent, operation=EvtInfo_WDGM_E_MONITORING.GetDebouncingOfEvent
        OpEventGetDebouncingOfEvent_GetDebouncingOfEvent_EvtInfo_WDGM_E_IMPROPER_CALLER: start-on-event=DemSatellite_0InternalBehavior/GetDebouncingOfEvent, operation=EvtInfo_WDGM_E_IMPROPER_CALLER.GetDebouncingOfEvent
        OpEventGetDebouncingOfEvent_GetDebouncingOfEvent_EvtInfo_DTC_0x1ca000: start-on-event=DemSatellite_0InternalBehavior/GetDebouncingOfEvent, operation=EvtInfo_DTC_0x1ca000.GetDebouncingOfEvent
        OpEventGetDebouncingOfEvent_GetDebouncingOfEvent_EvtInfo_DTC_0xa10b00: start-on-event=DemSatellite_0InternalBehavior/GetDebouncingOfEvent, operation=EvtInfo_DTC_0xa10b00.GetDebouncingOfEvent
        OpEventGetDebouncingOfEvent_GetDebouncingOfEvent_EvtInfo_DTC_0xc44286: start-on-event=DemSatellite_0InternalBehavior/GetDebouncingOfEvent, operation=EvtInfo_DTC_0xc44286.GetDebouncingOfEvent
        OpEventGetDebouncingOfEvent_GetDebouncingOfEvent_EvtInfo_DTC_0xa10d00: start-on-event=DemSatellite_0InternalBehavior/GetDebouncingOfEvent, operation=EvtInfo_DTC_0xa10d00.GetDebouncingOfEvent
        OpEventGetDebouncingOfEvent_GetDebouncingOfEvent_EvtInfo_DTC_0xa28b45: start-on-event=DemSatellite_0InternalBehavior/GetDebouncingOfEvent, operation=EvtInfo_DTC_0xa28b45.GetDebouncingOfEvent
        OpEventGetDebouncingOfEvent_GetDebouncingOfEvent_EvtInfo_DTC_0xc45208: start-on-event=DemSatellite_0InternalBehavior/GetDebouncingOfEvent, operation=EvtInfo_DTC_0xc45208.GetDebouncingOfEvent
        OpEventGetDebouncingOfEvent_GetDebouncingOfEvent_EvtInfo_DTC_0xa28b49: start-on-event=DemSatellite_0InternalBehavior/GetDebouncingOfEvent, operation=EvtInfo_DTC_0xa28b49.GetDebouncingOfEvent
        OpEventGetDebouncingOfEvent_GetDebouncingOfEvent_EvtInfo_DTC_0xa28b47: start-on-event=DemSatellite_0InternalBehavior/GetDebouncingOfEvent, operation=EvtInfo_DTC_0xa28b47.GetDebouncingOfEvent
        OpEventGetDebouncingOfEvent_GetDebouncingOfEvent_EvtInfo_DTC_0xc41608: start-on-event=DemSatellite_0InternalBehavior/GetDebouncingOfEvent, operation=EvtInfo_DTC_0xc41608.GetDebouncingOfEvent
        OpEventGetDebouncingOfEvent_GetDebouncingOfEvent_EvtInfo_DTC_0xc20287: start-on-event=DemSatellite_0InternalBehavior/GetDebouncingOfEvent, operation=EvtInfo_DTC_0xc20287.GetDebouncingOfEvent
        OpEventGetDebouncingOfEvent_GetDebouncingOfEvent_EvtInfo_DTC_0xa20400: start-on-event=DemSatellite_0InternalBehavior/GetDebouncingOfEvent, operation=EvtInfo_DTC_0xa20400.GetDebouncingOfEvent
        OpEventGetDebouncingOfEvent_GetDebouncingOfEvent_EvtInfo_DTC_0x9a6857: start-on-event=DemSatellite_0InternalBehavior/GetDebouncingOfEvent, operation=EvtInfo_DTC_0x9a6857.GetDebouncingOfEvent
        OpEventGetDebouncingOfEvent_GetDebouncingOfEvent_EvtInfo_DTC_0xa28b71: start-on-event=DemSatellite_0InternalBehavior/GetDebouncingOfEvent, operation=EvtInfo_DTC_0xa28b71.GetDebouncingOfEvent
        OpEventGetDebouncingOfEvent_GetDebouncingOfEvent_EvtInfo_DTC_0xa10a00: start-on-event=DemSatellite_0InternalBehavior/GetDebouncingOfEvent, operation=EvtInfo_DTC_0xa10a00.GetDebouncingOfEvent
        OpEventGetDebouncingOfEvent_GetDebouncingOfEvent_EvtInfo_DTC_0xd12081: start-on-event=DemSatellite_0InternalBehavior/GetDebouncingOfEvent, operation=EvtInfo_DTC_0xd12081.GetDebouncingOfEvent
        OpEventGetDebouncingOfEvent_GetDebouncingOfEvent_EvtInfo_DTC_0xd12083: start-on-event=DemSatellite_0InternalBehavior/GetDebouncingOfEvent, operation=EvtInfo_DTC_0xd12083.GetDebouncingOfEvent
        OpEventGetDebouncingOfEvent_GetDebouncingOfEvent_EvtInfo_DTC_0xa10e00: start-on-event=DemSatellite_0InternalBehavior/GetDebouncingOfEvent, operation=EvtInfo_DTC_0xa10e00.GetDebouncingOfEvent
        OpEventGetDebouncingOfEvent_GetDebouncingOfEvent_EvtInfo_DTC_0x164456: start-on-event=DemSatellite_0InternalBehavior/GetDebouncingOfEvent, operation=EvtInfo_DTC_0x164456.GetDebouncingOfEvent
        OpEventGetDebouncingOfEvent_GetDebouncingOfEvent_EvtInfo_DTC_0xa28bfa: start-on-event=DemSatellite_0InternalBehavior/GetDebouncingOfEvent, operation=EvtInfo_DTC_0xa28bfa.GetDebouncingOfEvent
        OpEventGetDebouncingOfEvent_GetDebouncingOfEvent_EvtInfo_DTC_0xc15587: start-on-event=DemSatellite_0InternalBehavior/GetDebouncingOfEvent, operation=EvtInfo_DTC_0xc15587.GetDebouncingOfEvent
        OpEventGetDebouncingOfEvent_GetDebouncingOfEvent_EvtInfo_DTC_0xd22488: start-on-event=DemSatellite_0InternalBehavior/GetDebouncingOfEvent, operation=EvtInfo_DTC_0xd22488.GetDebouncingOfEvent
        OpEventGetDebouncingOfEvent_GetDebouncingOfEvent_EvtInfo_DTC_0xd12087: start-on-event=DemSatellite_0InternalBehavior/GetDebouncingOfEvent, operation=EvtInfo_DTC_0xd12087.GetDebouncingOfEvent
        OpEventGetDebouncingOfEvent_GetDebouncingOfEvent_EvtInfo_DTC_0xc11587: start-on-event=DemSatellite_0InternalBehavior/GetDebouncingOfEvent, operation=EvtInfo_DTC_0xc11587.GetDebouncingOfEvent
        OpEventGetDebouncingOfEvent_GetDebouncingOfEvent_EvtInfo_DTC_0xc15187: start-on-event=DemSatellite_0InternalBehavior/GetDebouncingOfEvent, operation=EvtInfo_DTC_0xc15187.GetDebouncingOfEvent
        OpEventGetDebouncingOfEvent_GetDebouncingOfEvent_EvtInfo_DTC_0xc20187: start-on-event=DemSatellite_0InternalBehavior/GetDebouncingOfEvent, operation=EvtInfo_DTC_0xc20187.GetDebouncingOfEvent
        OpEventGetDebouncingOfEvent_GetDebouncingOfEvent_EvtInfo_DTC_0xa28b4b: start-on-event=DemSatellite_0InternalBehavior/GetDebouncingOfEvent, operation=EvtInfo_DTC_0xa28b4b.GetDebouncingOfEvent
        OpEventGetDebouncingOfEvent_GetDebouncingOfEvent_EvtInfo_DTC_0xa28b96: start-on-event=DemSatellite_0InternalBehavior/GetDebouncingOfEvent, operation=EvtInfo_DTC_0xa28b96.GetDebouncingOfEvent
        OpEventGetDebouncingOfEvent_GetDebouncingOfEvent_EvtInfo_DTC_0xc12287: start-on-event=DemSatellite_0InternalBehavior/GetDebouncingOfEvent, operation=EvtInfo_DTC_0xc12287.GetDebouncingOfEvent
        OpEventGetDebouncingOfEvent_GetDebouncingOfEvent_EvtInfo_DTC_0xc16887: start-on-event=DemSatellite_0InternalBehavior/GetDebouncingOfEvent, operation=EvtInfo_DTC_0xc16887.GetDebouncingOfEvent
        OpEventGetDebouncingOfEvent_GetDebouncingOfEvent_EvtInfo_DTC_0xa28b97: start-on-event=DemSatellite_0InternalBehavior/GetDebouncingOfEvent, operation=EvtInfo_DTC_0xa28b97.GetDebouncingOfEvent
        OpEventGetDebouncingOfEvent_GetDebouncingOfEvent_EvtInfo_DTC_0xa28b16: start-on-event=DemSatellite_0InternalBehavior/GetDebouncingOfEvent, operation=EvtInfo_DTC_0xa28b16.GetDebouncingOfEvent
        OpEventGetDebouncingOfEvent_GetDebouncingOfEvent_EvtInfo_DTC_0xc42708: start-on-event=DemSatellite_0InternalBehavior/GetDebouncingOfEvent, operation=EvtInfo_DTC_0xc42708.GetDebouncingOfEvent
        OpEventGetDebouncingOfEvent_GetDebouncingOfEvent_EvtInfo_DTC_0xa28b17: start-on-event=DemSatellite_0InternalBehavior/GetDebouncingOfEvent, operation=EvtInfo_DTC_0xa28b17.GetDebouncingOfEvent
        OpEventGetDebouncingOfEvent_GetDebouncingOfEvent_GeneralEvtInfo: start-on-event=DemSatellite_0InternalBehavior/GetDebouncingOfEvent, operation=GeneralEvtInfo.GetDebouncingOfEvent
        OpEventGetMonitorStatus_GetMonitorStatus_EvtInfo_SPI_E_HARDWARE_ERROR: start-on-event=DemSatellite_0InternalBehavior/GetMonitorStatus, operation=EvtInfo_SPI_E_HARDWARE_ERROR.GetMonitorStatus
        OpEventGetMonitorStatus_GetMonitorStatus_EvtInfo_WDGM_E_MONITORING: start-on-event=DemSatellite_0InternalBehavior/GetMonitorStatus, operation=EvtInfo_WDGM_E_MONITORING.GetMonitorStatus
        OpEventGetMonitorStatus_GetMonitorStatus_EvtInfo_WDGM_E_IMPROPER_CALLER: start-on-event=DemSatellite_0InternalBehavior/GetMonitorStatus, operation=EvtInfo_WDGM_E_IMPROPER_CALLER.GetMonitorStatus
        OpEventGetMonitorStatus_GetMonitorStatus_EvtInfo_DTC_0x1ca000: start-on-event=DemSatellite_0InternalBehavior/GetMonitorStatus, operation=EvtInfo_DTC_0x1ca000.GetMonitorStatus
        OpEventGetMonitorStatus_GetMonitorStatus_EvtInfo_DTC_0xa10b00: start-on-event=DemSatellite_0InternalBehavior/GetMonitorStatus, operation=EvtInfo_DTC_0xa10b00.GetMonitorStatus
        OpEventGetMonitorStatus_GetMonitorStatus_EvtInfo_DTC_0xc44286: start-on-event=DemSatellite_0InternalBehavior/GetMonitorStatus, operation=EvtInfo_DTC_0xc44286.GetMonitorStatus
        OpEventGetMonitorStatus_GetMonitorStatus_EvtInfo_DTC_0xa10d00: start-on-event=DemSatellite_0InternalBehavior/GetMonitorStatus, operation=EvtInfo_DTC_0xa10d00.GetMonitorStatus
        OpEventGetMonitorStatus_GetMonitorStatus_EvtInfo_DTC_0xa28b45: start-on-event=DemSatellite_0InternalBehavior/GetMonitorStatus, operation=EvtInfo_DTC_0xa28b45.GetMonitorStatus
        OpEventGetMonitorStatus_GetMonitorStatus_EvtInfo_DTC_0xc45208: start-on-event=DemSatellite_0InternalBehavior/GetMonitorStatus, operation=EvtInfo_DTC_0xc45208.GetMonitorStatus
        OpEventGetMonitorStatus_GetMonitorStatus_EvtInfo_DTC_0xa28b49: start-on-event=DemSatellite_0InternalBehavior/GetMonitorStatus, operation=EvtInfo_DTC_0xa28b49.GetMonitorStatus
        OpEventGetMonitorStatus_GetMonitorStatus_EvtInfo_DTC_0xa28b47: start-on-event=DemSatellite_0InternalBehavior/GetMonitorStatus, operation=EvtInfo_DTC_0xa28b47.GetMonitorStatus
        OpEventGetMonitorStatus_GetMonitorStatus_EvtInfo_DTC_0xc41608: start-on-event=DemSatellite_0InternalBehavior/GetMonitorStatus, operation=EvtInfo_DTC_0xc41608.GetMonitorStatus
        OpEventGetMonitorStatus_GetMonitorStatus_EvtInfo_DTC_0xc20287: start-on-event=DemSatellite_0InternalBehavior/GetMonitorStatus, operation=EvtInfo_DTC_0xc20287.GetMonitorStatus
        OpEventGetMonitorStatus_GetMonitorStatus_EvtInfo_DTC_0xa20400: start-on-event=DemSatellite_0InternalBehavior/GetMonitorStatus, operation=EvtInfo_DTC_0xa20400.GetMonitorStatus
        OpEventGetMonitorStatus_GetMonitorStatus_EvtInfo_DTC_0x9a6857: start-on-event=DemSatellite_0InternalBehavior/GetMonitorStatus, operation=EvtInfo_DTC_0x9a6857.GetMonitorStatus
        OpEventGetMonitorStatus_GetMonitorStatus_EvtInfo_DTC_0xa28b71: start-on-event=DemSatellite_0InternalBehavior/GetMonitorStatus, operation=EvtInfo_DTC_0xa28b71.GetMonitorStatus
        OpEventGetMonitorStatus_GetMonitorStatus_EvtInfo_DTC_0xa10a00: start-on-event=DemSatellite_0InternalBehavior/GetMonitorStatus, operation=EvtInfo_DTC_0xa10a00.GetMonitorStatus
        OpEventGetMonitorStatus_GetMonitorStatus_EvtInfo_DTC_0xd12081: start-on-event=DemSatellite_0InternalBehavior/GetMonitorStatus, operation=EvtInfo_DTC_0xd12081.GetMonitorStatus
        OpEventGetMonitorStatus_GetMonitorStatus_EvtInfo_DTC_0xd12083: start-on-event=DemSatellite_0InternalBehavior/GetMonitorStatus, operation=EvtInfo_DTC_0xd12083.GetMonitorStatus
        OpEventGetMonitorStatus_GetMonitorStatus_EvtInfo_DTC_0xa10e00: start-on-event=DemSatellite_0InternalBehavior/GetMonitorStatus, operation=EvtInfo_DTC_0xa10e00.GetMonitorStatus
        OpEventGetMonitorStatus_GetMonitorStatus_EvtInfo_DTC_0x164456: start-on-event=DemSatellite_0InternalBehavior/GetMonitorStatus, operation=EvtInfo_DTC_0x164456.GetMonitorStatus
        OpEventGetMonitorStatus_GetMonitorStatus_EvtInfo_DTC_0xa28bfa: start-on-event=DemSatellite_0InternalBehavior/GetMonitorStatus, operation=EvtInfo_DTC_0xa28bfa.GetMonitorStatus
        OpEventGetMonitorStatus_GetMonitorStatus_EvtInfo_DTC_0xc15587: start-on-event=DemSatellite_0InternalBehavior/GetMonitorStatus, operation=EvtInfo_DTC_0xc15587.GetMonitorStatus
        OpEventGetMonitorStatus_GetMonitorStatus_EvtInfo_DTC_0xd22488: start-on-event=DemSatellite_0InternalBehavior/GetMonitorStatus, operation=EvtInfo_DTC_0xd22488.GetMonitorStatus
        OpEventGetMonitorStatus_GetMonitorStatus_EvtInfo_DTC_0xd12087: start-on-event=DemSatellite_0InternalBehavior/GetMonitorStatus, operation=EvtInfo_DTC_0xd12087.GetMonitorStatus
        OpEventGetMonitorStatus_GetMonitorStatus_EvtInfo_DTC_0xc11587: start-on-event=DemSatellite_0InternalBehavior/GetMonitorStatus, operation=EvtInfo_DTC_0xc11587.GetMonitorStatus
        OpEventGetMonitorStatus_GetMonitorStatus_EvtInfo_DTC_0xc15187: start-on-event=DemSatellite_0InternalBehavior/GetMonitorStatus, operation=EvtInfo_DTC_0xc15187.GetMonitorStatus
        OpEventGetMonitorStatus_GetMonitorStatus_EvtInfo_DTC_0xc20187: start-on-event=DemSatellite_0InternalBehavior/GetMonitorStatus, operation=EvtInfo_DTC_0xc20187.GetMonitorStatus
        OpEventGetMonitorStatus_GetMonitorStatus_EvtInfo_DTC_0xa28b4b: start-on-event=DemSatellite_0InternalBehavior/GetMonitorStatus, operation=EvtInfo_DTC_0xa28b4b.GetMonitorStatus
        OpEventGetMonitorStatus_GetMonitorStatus_EvtInfo_DTC_0xa28b96: start-on-event=DemSatellite_0InternalBehavior/GetMonitorStatus, operation=EvtInfo_DTC_0xa28b96.GetMonitorStatus
        OpEventGetMonitorStatus_GetMonitorStatus_EvtInfo_DTC_0xc12287: start-on-event=DemSatellite_0InternalBehavior/GetMonitorStatus, operation=EvtInfo_DTC_0xc12287.GetMonitorStatus
        OpEventGetMonitorStatus_GetMonitorStatus_EvtInfo_DTC_0xc16887: start-on-event=DemSatellite_0InternalBehavior/GetMonitorStatus, operation=EvtInfo_DTC_0xc16887.GetMonitorStatus
        OpEventGetMonitorStatus_GetMonitorStatus_EvtInfo_DTC_0xa28b97: start-on-event=DemSatellite_0InternalBehavior/GetMonitorStatus, operation=EvtInfo_DTC_0xa28b97.GetMonitorStatus
        OpEventGetMonitorStatus_GetMonitorStatus_EvtInfo_DTC_0xa28b16: start-on-event=DemSatellite_0InternalBehavior/GetMonitorStatus, operation=EvtInfo_DTC_0xa28b16.GetMonitorStatus
        OpEventGetMonitorStatus_GetMonitorStatus_EvtInfo_DTC_0xc42708: start-on-event=DemSatellite_0InternalBehavior/GetMonitorStatus, operation=EvtInfo_DTC_0xc42708.GetMonitorStatus
        OpEventGetMonitorStatus_GetMonitorStatus_EvtInfo_DTC_0xa28b17: start-on-event=DemSatellite_0InternalBehavior/GetMonitorStatus, operation=EvtInfo_DTC_0xa28b17.GetMonitorStatus
        OpEventGetMonitorStatus_GetMonitorStatus_GeneralEvtInfo: start-on-event=DemSatellite_0InternalBehavior/GetMonitorStatus, operation=GeneralEvtInfo.GetMonitorStatus
        OpEventSetEventStatus_SetEventStatus_Event_DTC_0x1ca000: start-on-event=SetEventStatus, operation=Event_DTC_0x1ca000.SetEventStatus
        OpEventSetEventStatus_SetEventStatus_Event_DTC_0xa10b00: start-on-event=SetEventStatus, operation=Event_DTC_0xa10b00.SetEventStatus
        OpEventSetEventStatus_SetEventStatus_Event_DTC_0xc44286: start-on-event=SetEventStatus, operation=Event_DTC_0xc44286.SetEventStatus
        OpEventSetEventStatus_SetEventStatus_Event_DTC_0xa10d00: start-on-event=SetEventStatus, operation=Event_DTC_0xa10d00.SetEventStatus
        OpEventSetEventStatus_SetEventStatus_Event_DTC_0xa28b45: start-on-event=SetEventStatus, operation=Event_DTC_0xa28b45.SetEventStatus
        OpEventSetEventStatus_SetEventStatus_Event_DTC_0xc45208: start-on-event=SetEventStatus, operation=Event_DTC_0xc45208.SetEventStatus
        OpEventSetEventStatus_SetEventStatus_Event_DTC_0xa28b49: start-on-event=SetEventStatus, operation=Event_DTC_0xa28b49.SetEventStatus
        OpEventSetEventStatus_SetEventStatus_Event_DTC_0xa28b47: start-on-event=SetEventStatus, operation=Event_DTC_0xa28b47.SetEventStatus
        OpEventSetEventStatus_SetEventStatus_Event_DTC_0xc41608: start-on-event=SetEventStatus, operation=Event_DTC_0xc41608.SetEventStatus
        OpEventSetEventStatus_SetEventStatus_Event_DTC_0xc20287: start-on-event=SetEventStatus, operation=Event_DTC_0xc20287.SetEventStatus
        OpEventSetEventStatus_SetEventStatus_Event_DTC_0xa20400: start-on-event=SetEventStatus, operation=Event_DTC_0xa20400.SetEventStatus
        OpEventSetEventStatus_SetEventStatus_Event_DTC_0x9a6857: start-on-event=SetEventStatus, operation=Event_DTC_0x9a6857.SetEventStatus
        OpEventSetEventStatus_SetEventStatus_Event_DTC_0xa28b71: start-on-event=SetEventStatus, operation=Event_DTC_0xa28b71.SetEventStatus
        OpEventSetEventStatus_SetEventStatus_Event_DTC_0xa10a00: start-on-event=SetEventStatus, operation=Event_DTC_0xa10a00.SetEventStatus
        OpEventSetEventStatus_SetEventStatus_Event_DTC_0xd12081: start-on-event=SetEventStatus, operation=Event_DTC_0xd12081.SetEventStatus
        OpEventSetEventStatus_SetEventStatus_Event_DTC_0xd12083: start-on-event=SetEventStatus, operation=Event_DTC_0xd12083.SetEventStatus
        OpEventSetEventStatus_SetEventStatus_Event_DTC_0xa10e00: start-on-event=SetEventStatus, operation=Event_DTC_0xa10e00.SetEventStatus
        OpEventSetEventStatus_SetEventStatus_Event_DTC_0x164456: start-on-event=SetEventStatus, operation=Event_DTC_0x164456.SetEventStatus
        OpEventSetEventStatus_SetEventStatus_Event_DTC_0xa28bfa: start-on-event=SetEventStatus, operation=Event_DTC_0xa28bfa.SetEventStatus
        OpEventSetEventStatus_SetEventStatus_Event_DTC_0xc15587: start-on-event=SetEventStatus, operation=Event_DTC_0xc15587.SetEventStatus
        OpEventSetEventStatus_SetEventStatus_Event_DTC_0xd22488: start-on-event=SetEventStatus, operation=Event_DTC_0xd22488.SetEventStatus
        OpEventSetEventStatus_SetEventStatus_Event_DTC_0xd12087: start-on-event=SetEventStatus, operation=Event_DTC_0xd12087.SetEventStatus
        OpEventSetEventStatus_SetEventStatus_Event_DTC_0xc11587: start-on-event=SetEventStatus, operation=Event_DTC_0xc11587.SetEventStatus
        OpEventSetEventStatus_SetEventStatus_Event_DTC_0xc15187: start-on-event=SetEventStatus, operation=Event_DTC_0xc15187.SetEventStatus
        OpEventSetEventStatus_SetEventStatus_Event_DTC_0xc20187: start-on-event=SetEventStatus, operation=Event_DTC_0xc20187.SetEventStatus
        OpEventSetEventStatus_SetEventStatus_Event_DTC_0xa28b4b: start-on-event=SetEventStatus, operation=Event_DTC_0xa28b4b.SetEventStatus
        OpEventSetEventStatus_SetEventStatus_Event_DTC_0xa28b96: start-on-event=SetEventStatus, operation=Event_DTC_0xa28b96.SetEventStatus
        OpEventSetEventStatus_SetEventStatus_Event_DTC_0xc12287: start-on-event=SetEventStatus, operation=Event_DTC_0xc12287.SetEventStatus
        OpEventSetEventStatus_SetEventStatus_Event_DTC_0xc16887: start-on-event=SetEventStatus, operation=Event_DTC_0xc16887.SetEventStatus
        OpEventSetEventStatus_SetEventStatus_Event_DTC_0xa28b97: start-on-event=SetEventStatus, operation=Event_DTC_0xa28b97.SetEventStatus
        OpEventSetEventStatus_SetEventStatus_Event_DTC_0xa28b16: start-on-event=SetEventStatus, operation=Event_DTC_0xa28b16.SetEventStatus
        OpEventSetEventStatus_SetEventStatus_Event_DTC_0xc42708: start-on-event=SetEventStatus, operation=Event_DTC_0xc42708.SetEventStatus
        OpEventSetEventStatus_SetEventStatus_Event_DTC_0xa28b17: start-on-event=SetEventStatus, operation=Event_DTC_0xa28b17.SetEventStatus
        OpEventResetEventStatus_ResetEventStatus_Event_DTC_0x1ca000: start-on-event=ResetEventStatus, operation=Event_DTC_0x1ca000.ResetEventStatus
        OpEventResetEventStatus_ResetEventStatus_Event_DTC_0xa10b00: start-on-event=ResetEventStatus, operation=Event_DTC_0xa10b00.ResetEventStatus
        OpEventResetEventStatus_ResetEventStatus_Event_DTC_0xc44286: start-on-event=ResetEventStatus, operation=Event_DTC_0xc44286.ResetEventStatus
        OpEventResetEventStatus_ResetEventStatus_Event_DTC_0xa10d00: start-on-event=ResetEventStatus, operation=Event_DTC_0xa10d00.ResetEventStatus
        OpEventResetEventStatus_ResetEventStatus_Event_DTC_0xa28b45: start-on-event=ResetEventStatus, operation=Event_DTC_0xa28b45.ResetEventStatus
        OpEventResetEventStatus_ResetEventStatus_Event_DTC_0xc45208: start-on-event=ResetEventStatus, operation=Event_DTC_0xc45208.ResetEventStatus
        OpEventResetEventStatus_ResetEventStatus_Event_DTC_0xa28b49: start-on-event=ResetEventStatus, operation=Event_DTC_0xa28b49.ResetEventStatus
        OpEventResetEventStatus_ResetEventStatus_Event_DTC_0xa28b47: start-on-event=ResetEventStatus, operation=Event_DTC_0xa28b47.ResetEventStatus
        OpEventResetEventStatus_ResetEventStatus_Event_DTC_0xc41608: start-on-event=ResetEventStatus, operation=Event_DTC_0xc41608.ResetEventStatus
        OpEventResetEventStatus_ResetEventStatus_Event_DTC_0xc20287: start-on-event=ResetEventStatus, operation=Event_DTC_0xc20287.ResetEventStatus
        OpEventResetEventStatus_ResetEventStatus_Event_DTC_0xa20400: start-on-event=ResetEventStatus, operation=Event_DTC_0xa20400.ResetEventStatus
        OpEventResetEventStatus_ResetEventStatus_Event_DTC_0x9a6857: start-on-event=ResetEventStatus, operation=Event_DTC_0x9a6857.ResetEventStatus
        OpEventResetEventStatus_ResetEventStatus_Event_DTC_0xa28b71: start-on-event=ResetEventStatus, operation=Event_DTC_0xa28b71.ResetEventStatus
        OpEventResetEventStatus_ResetEventStatus_Event_DTC_0xa10a00: start-on-event=ResetEventStatus, operation=Event_DTC_0xa10a00.ResetEventStatus
        OpEventResetEventStatus_ResetEventStatus_Event_DTC_0xd12081: start-on-event=ResetEventStatus, operation=Event_DTC_0xd12081.ResetEventStatus
        OpEventResetEventStatus_ResetEventStatus_Event_DTC_0xd12083: start-on-event=ResetEventStatus, operation=Event_DTC_0xd12083.ResetEventStatus
        OpEventResetEventStatus_ResetEventStatus_Event_DTC_0xa10e00: start-on-event=ResetEventStatus, operation=Event_DTC_0xa10e00.ResetEventStatus
        OpEventResetEventStatus_ResetEventStatus_Event_DTC_0x164456: start-on-event=ResetEventStatus, operation=Event_DTC_0x164456.ResetEventStatus
        OpEventResetEventStatus_ResetEventStatus_Event_DTC_0xa28bfa: start-on-event=ResetEventStatus, operation=Event_DTC_0xa28bfa.ResetEventStatus
        OpEventResetEventStatus_ResetEventStatus_Event_DTC_0xc15587: start-on-event=ResetEventStatus, operation=Event_DTC_0xc15587.ResetEventStatus
        OpEventResetEventStatus_ResetEventStatus_Event_DTC_0xd22488: start-on-event=ResetEventStatus, operation=Event_DTC_0xd22488.ResetEventStatus
        OpEventResetEventStatus_ResetEventStatus_Event_DTC_0xd12087: start-on-event=ResetEventStatus, operation=Event_DTC_0xd12087.ResetEventStatus
        OpEventResetEventStatus_ResetEventStatus_Event_DTC_0xc11587: start-on-event=ResetEventStatus, operation=Event_DTC_0xc11587.ResetEventStatus
        OpEventResetEventStatus_ResetEventStatus_Event_DTC_0xc15187: start-on-event=ResetEventStatus, operation=Event_DTC_0xc15187.ResetEventStatus
        OpEventResetEventStatus_ResetEventStatus_Event_DTC_0xc20187: start-on-event=ResetEventStatus, operation=Event_DTC_0xc20187.ResetEventStatus
        OpEventResetEventStatus_ResetEventStatus_Event_DTC_0xa28b4b: start-on-event=ResetEventStatus, operation=Event_DTC_0xa28b4b.ResetEventStatus
        OpEventResetEventStatus_ResetEventStatus_Event_DTC_0xa28b96: start-on-event=ResetEventStatus, operation=Event_DTC_0xa28b96.ResetEventStatus
        OpEventResetEventStatus_ResetEventStatus_Event_DTC_0xc12287: start-on-event=ResetEventStatus, operation=Event_DTC_0xc12287.ResetEventStatus
        OpEventResetEventStatus_ResetEventStatus_Event_DTC_0xc16887: start-on-event=ResetEventStatus, operation=Event_DTC_0xc16887.ResetEventStatus
        OpEventResetEventStatus_ResetEventStatus_Event_DTC_0xa28b97: start-on-event=ResetEventStatus, operation=Event_DTC_0xa28b97.ResetEventStatus
        OpEventResetEventStatus_ResetEventStatus_Event_DTC_0xa28b16: start-on-event=ResetEventStatus, operation=Event_DTC_0xa28b16.ResetEventStatus
        OpEventResetEventStatus_ResetEventStatus_Event_DTC_0xc42708: start-on-event=ResetEventStatus, operation=Event_DTC_0xc42708.ResetEventStatus
        OpEventResetEventStatus_ResetEventStatus_Event_DTC_0xa28b17: start-on-event=ResetEventStatus, operation=Event_DTC_0xa28b17.ResetEventStatus
        OpEventResetEventDebounceStatus_ResetEventDebounceStatus_Event_DTC_0x1ca000: start-on-event=ResetEventDebounceStatus, operation=Event_DTC_0x1ca000.ResetEventDebounceStatus
        OpEventResetEventDebounceStatus_ResetEventDebounceStatus_Event_DTC_0xa10b00: start-on-event=ResetEventDebounceStatus, operation=Event_DTC_0xa10b00.ResetEventDebounceStatus
        OpEventResetEventDebounceStatus_ResetEventDebounceStatus_Event_DTC_0xc44286: start-on-event=ResetEventDebounceStatus, operation=Event_DTC_0xc44286.ResetEventDebounceStatus
        OpEventResetEventDebounceStatus_ResetEventDebounceStatus_Event_DTC_0xa10d00: start-on-event=ResetEventDebounceStatus, operation=Event_DTC_0xa10d00.ResetEventDebounceStatus
        OpEventResetEventDebounceStatus_ResetEventDebounceStatus_Event_DTC_0xa28b45: start-on-event=ResetEventDebounceStatus, operation=Event_DTC_0xa28b45.ResetEventDebounceStatus
        OpEventResetEventDebounceStatus_ResetEventDebounceStatus_Event_DTC_0xc45208: start-on-event=ResetEventDebounceStatus, operation=Event_DTC_0xc45208.ResetEventDebounceStatus
        OpEventResetEventDebounceStatus_ResetEventDebounceStatus_Event_DTC_0xa28b49: start-on-event=ResetEventDebounceStatus, operation=Event_DTC_0xa28b49.ResetEventDebounceStatus
        OpEventResetEventDebounceStatus_ResetEventDebounceStatus_Event_DTC_0xa28b47: start-on-event=ResetEventDebounceStatus, operation=Event_DTC_0xa28b47.ResetEventDebounceStatus
        OpEventResetEventDebounceStatus_ResetEventDebounceStatus_Event_DTC_0xc41608: start-on-event=ResetEventDebounceStatus, operation=Event_DTC_0xc41608.ResetEventDebounceStatus
        OpEventResetEventDebounceStatus_ResetEventDebounceStatus_Event_DTC_0xc20287: start-on-event=ResetEventDebounceStatus, operation=Event_DTC_0xc20287.ResetEventDebounceStatus
        OpEventResetEventDebounceStatus_ResetEventDebounceStatus_Event_DTC_0xa20400: start-on-event=ResetEventDebounceStatus, operation=Event_DTC_0xa20400.ResetEventDebounceStatus
        OpEventResetEventDebounceStatus_ResetEventDebounceStatus_Event_DTC_0x9a6857: start-on-event=ResetEventDebounceStatus, operation=Event_DTC_0x9a6857.ResetEventDebounceStatus
        OpEventResetEventDebounceStatus_ResetEventDebounceStatus_Event_DTC_0xa28b71: start-on-event=ResetEventDebounceStatus, operation=Event_DTC_0xa28b71.ResetEventDebounceStatus
        OpEventResetEventDebounceStatus_ResetEventDebounceStatus_Event_DTC_0xa10a00: start-on-event=ResetEventDebounceStatus, operation=Event_DTC_0xa10a00.ResetEventDebounceStatus
        OpEventResetEventDebounceStatus_ResetEventDebounceStatus_Event_DTC_0xd12081: start-on-event=ResetEventDebounceStatus, operation=Event_DTC_0xd12081.ResetEventDebounceStatus
        OpEventResetEventDebounceStatus_ResetEventDebounceStatus_Event_DTC_0xd12083: start-on-event=ResetEventDebounceStatus, operation=Event_DTC_0xd12083.ResetEventDebounceStatus
        OpEventResetEventDebounceStatus_ResetEventDebounceStatus_Event_DTC_0xa10e00: start-on-event=ResetEventDebounceStatus, operation=Event_DTC_0xa10e00.ResetEventDebounceStatus
        OpEventResetEventDebounceStatus_ResetEventDebounceStatus_Event_DTC_0x164456: start-on-event=ResetEventDebounceStatus, operation=Event_DTC_0x164456.ResetEventDebounceStatus
        OpEventResetEventDebounceStatus_ResetEventDebounceStatus_Event_DTC_0xa28bfa: start-on-event=ResetEventDebounceStatus, operation=Event_DTC_0xa28bfa.ResetEventDebounceStatus
        OpEventResetEventDebounceStatus_ResetEventDebounceStatus_Event_DTC_0xc15587: start-on-event=ResetEventDebounceStatus, operation=Event_DTC_0xc15587.ResetEventDebounceStatus
        OpEventResetEventDebounceStatus_ResetEventDebounceStatus_Event_DTC_0xd22488: start-on-event=ResetEventDebounceStatus, operation=Event_DTC_0xd22488.ResetEventDebounceStatus
        OpEventResetEventDebounceStatus_ResetEventDebounceStatus_Event_DTC_0xd12087: start-on-event=ResetEventDebounceStatus, operation=Event_DTC_0xd12087.ResetEventDebounceStatus
        OpEventResetEventDebounceStatus_ResetEventDebounceStatus_Event_DTC_0xc11587: start-on-event=ResetEventDebounceStatus, operation=Event_DTC_0xc11587.ResetEventDebounceStatus
        OpEventResetEventDebounceStatus_ResetEventDebounceStatus_Event_DTC_0xc15187: start-on-event=ResetEventDebounceStatus, operation=Event_DTC_0xc15187.ResetEventDebounceStatus
        OpEventResetEventDebounceStatus_ResetEventDebounceStatus_Event_DTC_0xc20187: start-on-event=ResetEventDebounceStatus, operation=Event_DTC_0xc20187.ResetEventDebounceStatus
        OpEventResetEventDebounceStatus_ResetEventDebounceStatus_Event_DTC_0xa28b4b: start-on-event=ResetEventDebounceStatus, operation=Event_DTC_0xa28b4b.ResetEventDebounceStatus
        OpEventResetEventDebounceStatus_ResetEventDebounceStatus_Event_DTC_0xa28b96: start-on-event=ResetEventDebounceStatus, operation=Event_DTC_0xa28b96.ResetEventDebounceStatus
        OpEventResetEventDebounceStatus_ResetEventDebounceStatus_Event_DTC_0xc12287: start-on-event=ResetEventDebounceStatus, operation=Event_DTC_0xc12287.ResetEventDebounceStatus
        OpEventResetEventDebounceStatus_ResetEventDebounceStatus_Event_DTC_0xc16887: start-on-event=ResetEventDebounceStatus, operation=Event_DTC_0xc16887.ResetEventDebounceStatus
        OpEventResetEventDebounceStatus_ResetEventDebounceStatus_Event_DTC_0xa28b97: start-on-event=ResetEventDebounceStatus, operation=Event_DTC_0xa28b97.ResetEventDebounceStatus
        OpEventResetEventDebounceStatus_ResetEventDebounceStatus_Event_DTC_0xa28b16: start-on-event=ResetEventDebounceStatus, operation=Event_DTC_0xa28b16.ResetEventDebounceStatus
        OpEventResetEventDebounceStatus_ResetEventDebounceStatus_Event_DTC_0xc42708: start-on-event=ResetEventDebounceStatus, operation=Event_DTC_0xc42708.ResetEventDebounceStatus
        OpEventResetEventDebounceStatus_ResetEventDebounceStatus_Event_DTC_0xa28b17: start-on-event=ResetEventDebounceStatus, operation=Event_DTC_0xa28b17.ResetEventDebounceStatus
        OpEventGetEventUdsStatus_GetEventUdsStatus_EvtInfo_ADC_ERROR_Dummy: start-on-event=DemSatellite_0InternalBehavior/GetEventUdsStatus, operation=EvtInfo_ADC_ERROR_Dummy.GetEventUdsStatus
        OpEventGetEventUdsStatus_GetEventUdsStatus_Event_ADC_ERROR_Dummy: start-on-event=DemSatellite_0InternalBehavior/GetEventUdsStatus, operation=Event_ADC_ERROR_Dummy.GetEventUdsStatus
        OpEventGetEventStatus_GetEventStatus_EvtInfo_ADC_ERROR_Dummy: start-on-event=DemSatellite_0InternalBehavior/GetEventStatus, operation=EvtInfo_ADC_ERROR_Dummy.GetEventStatus
        OpEventGetEventStatus_GetEventStatus_Event_ADC_ERROR_Dummy: start-on-event=DemSatellite_0InternalBehavior/GetEventStatus, operation=Event_ADC_ERROR_Dummy.GetEventStatus
        OpEventGetEventFailed_GetEventFailed_EvtInfo_ADC_ERROR_Dummy: start-on-event=DemSatellite_0InternalBehavior/GetEventFailed, operation=EvtInfo_ADC_ERROR_Dummy.GetEventFailed
        OpEventGetEventFailed_GetEventFailed_Event_ADC_ERROR_Dummy: start-on-event=DemSatellite_0InternalBehavior/GetEventFailed, operation=Event_ADC_ERROR_Dummy.GetEventFailed
        OpEventGetEventTested_GetEventTested_EvtInfo_ADC_ERROR_Dummy: start-on-event=DemSatellite_0InternalBehavior/GetEventTested, operation=EvtInfo_ADC_ERROR_Dummy.GetEventTested
        OpEventGetEventTested_GetEventTested_Event_ADC_ERROR_Dummy: start-on-event=DemSatellite_0InternalBehavior/GetEventTested, operation=Event_ADC_ERROR_Dummy.GetEventTested
        OpEventGetDTCOfEvent_GetDTCOfEvent_EvtInfo_ADC_ERROR_Dummy: start-on-event=DemSatellite_0InternalBehavior/GetDTCOfEvent, operation=EvtInfo_ADC_ERROR_Dummy.GetDTCOfEvent
        OpEventGetDTCOfEvent_GetDTCOfEvent_Event_ADC_ERROR_Dummy: start-on-event=DemSatellite_0InternalBehavior/GetDTCOfEvent, operation=Event_ADC_ERROR_Dummy.GetDTCOfEvent
        OpEventGetFaultDetectionCounter_GetFaultDetectionCounter_EvtInfo_ADC_ERROR_Dummy: start-on-event=DemSatellite_0InternalBehavior/GetFaultDetectionCounter, operation=EvtInfo_ADC_ERROR_Dummy.GetFaultDetectionCounter
        OpEventGetFaultDetectionCounter_GetFaultDetectionCounter_Event_ADC_ERROR_Dummy: start-on-event=DemSatellite_0InternalBehavior/GetFaultDetectionCounter, operation=Event_ADC_ERROR_Dummy.GetFaultDetectionCounter
        OpEventGetEventFreezeFrameDataEx_GetEventFreezeFrameDataEx_EvtInfo_ADC_ERROR_Dummy: start-on-event=DemSatellite_0InternalBehavior/GetEventFreezeFrameDataEx, operation=EvtInfo_ADC_ERROR_Dummy.GetEventFreezeFrameDataEx
        OpEventGetEventFreezeFrameDataEx_GetEventFreezeFrameDataEx_Event_ADC_ERROR_Dummy: start-on-event=DemSatellite_0InternalBehavior/GetEventFreezeFrameDataEx, operation=Event_ADC_ERROR_Dummy.GetEventFreezeFrameDataEx
        OpEventGetEventExtendedDataRecordEx_GetEventExtendedDataRecordEx_EvtInfo_ADC_ERROR_Dummy: start-on-event=DemSatellite_0InternalBehavior/GetEventExtendedDataRecordEx, operation=EvtInfo_ADC_ERROR_Dummy.GetEventExtendedDataRecordEx
        OpEventGetEventExtendedDataRecordEx_GetEventExtendedDataRecordEx_Event_ADC_ERROR_Dummy: start-on-event=DemSatellite_0InternalBehavior/GetEventExtendedDataRecordEx, operation=Event_ADC_ERROR_Dummy.GetEventExtendedDataRecordEx
        OpEventGetEventEnableCondition_GetEventEnableCondition_EvtInfo_ADC_ERROR_Dummy: start-on-event=DemSatellite_0InternalBehavior/GetEventEnableCondition, operation=EvtInfo_ADC_ERROR_Dummy.GetEventEnableCondition
        OpEventGetDebouncingOfEvent_GetDebouncingOfEvent_EvtInfo_ADC_ERROR_Dummy: start-on-event=DemSatellite_0InternalBehavior/GetDebouncingOfEvent, operation=EvtInfo_ADC_ERROR_Dummy.GetDebouncingOfEvent
        OpEventGetMonitorStatus_GetMonitorStatus_EvtInfo_ADC_ERROR_Dummy: start-on-event=DemSatellite_0InternalBehavior/GetMonitorStatus, operation=EvtInfo_ADC_ERROR_Dummy.GetMonitorStatus
        OpEventSetEventStatus_SetEventStatus_Event_ADC_ERROR_Dummy: start-on-event=SetEventStatus, operation=Event_ADC_ERROR_Dummy.SetEventStatus
        OpEventResetEventStatus_ResetEventStatus_Event_ADC_ERROR_Dummy: start-on-event=ResetEventStatus, operation=Event_ADC_ERROR_Dummy.ResetEventStatus
        OpEventResetEventDebounceStatus_ResetEventDebounceStatus_Event_ADC_ERROR_Dummy: start-on-event=ResetEventDebounceStatus, operation=Event_ADC_ERROR_Dummy.ResetEventDebounceStatus
        OpEventGetEventUdsStatus_GetEventUdsStatus_EvtInfo_MCU_E_OSC_FAILURE: start-on-event=DemSatellite_0InternalBehavior/GetEventUdsStatus, operation=EvtInfo_MCU_E_OSC_FAILURE.GetEventUdsStatus
        OpEventGetEventStatus_GetEventStatus_EvtInfo_MCU_E_OSC_FAILURE: start-on-event=DemSatellite_0InternalBehavior/GetEventStatus, operation=EvtInfo_MCU_E_OSC_FAILURE.GetEventStatus
        OpEventGetEventFailed_GetEventFailed_EvtInfo_MCU_E_OSC_FAILURE: start-on-event=DemSatellite_0InternalBehavior/GetEventFailed, operation=EvtInfo_MCU_E_OSC_FAILURE.GetEventFailed
        OpEventGetEventTested_GetEventTested_EvtInfo_MCU_E_OSC_FAILURE: start-on-event=DemSatellite_0InternalBehavior/GetEventTested, operation=EvtInfo_MCU_E_OSC_FAILURE.GetEventTested
        OpEventGetDTCOfEvent_GetDTCOfEvent_EvtInfo_MCU_E_OSC_FAILURE: start-on-event=DemSatellite_0InternalBehavior/GetDTCOfEvent, operation=EvtInfo_MCU_E_OSC_FAILURE.GetDTCOfEvent
        OpEventGetFaultDetectionCounter_GetFaultDetectionCounter_EvtInfo_MCU_E_OSC_FAILURE: start-on-event=DemSatellite_0InternalBehavior/GetFaultDetectionCounter, operation=EvtInfo_MCU_E_OSC_FAILURE.GetFaultDetectionCounter
        OpEventGetEventFreezeFrameDataEx_GetEventFreezeFrameDataEx_EvtInfo_MCU_E_OSC_FAILURE: start-on-event=DemSatellite_0InternalBehavior/GetEventFreezeFrameDataEx, operation=EvtInfo_MCU_E_OSC_FAILURE.GetEventFreezeFrameDataEx
        OpEventGetEventExtendedDataRecordEx_GetEventExtendedDataRecordEx_EvtInfo_MCU_E_OSC_FAILURE: start-on-event=DemSatellite_0InternalBehavior/GetEventExtendedDataRecordEx, operation=EvtInfo_MCU_E_OSC_FAILURE.GetEventExtendedDataRecordEx
        OpEventGetEventEnableCondition_GetEventEnableCondition_EvtInfo_MCU_E_OSC_FAILURE: start-on-event=DemSatellite_0InternalBehavior/GetEventEnableCondition, operation=EvtInfo_MCU_E_OSC_FAILURE.GetEventEnableCondition
        OpEventGetDebouncingOfEvent_GetDebouncingOfEvent_EvtInfo_MCU_E_OSC_FAILURE: start-on-event=DemSatellite_0InternalBehavior/GetDebouncingOfEvent, operation=EvtInfo_MCU_E_OSC_FAILURE.GetDebouncingOfEvent
        OpEventGetMonitorStatus_GetMonitorStatus_EvtInfo_MCU_E_OSC_FAILURE: start-on-event=DemSatellite_0InternalBehavior/GetMonitorStatus, operation=EvtInfo_MCU_E_OSC_FAILURE.GetMonitorStatus
        OpEventGetEventUdsStatus_GetEventUdsStatus_EvtInfo_MCU_E_SYSTEM_PLL_LOCK_LOSS: start-on-event=DemSatellite_0InternalBehavior/GetEventUdsStatus, operation=EvtInfo_MCU_E_SYSTEM_PLL_LOCK_LOSS.GetEventUdsStatus
        OpEventGetEventStatus_GetEventStatus_EvtInfo_MCU_E_SYSTEM_PLL_LOCK_LOSS: start-on-event=DemSatellite_0InternalBehavior/GetEventStatus, operation=EvtInfo_MCU_E_SYSTEM_PLL_LOCK_LOSS.GetEventStatus
        OpEventGetEventFailed_GetEventFailed_EvtInfo_MCU_E_SYSTEM_PLL_LOCK_LOSS: start-on-event=DemSatellite_0InternalBehavior/GetEventFailed, operation=EvtInfo_MCU_E_SYSTEM_PLL_LOCK_LOSS.GetEventFailed
        OpEventGetEventTested_GetEventTested_EvtInfo_MCU_E_SYSTEM_PLL_LOCK_LOSS: start-on-event=DemSatellite_0InternalBehavior/GetEventTested, operation=EvtInfo_MCU_E_SYSTEM_PLL_LOCK_LOSS.GetEventTested
        OpEventGetDTCOfEvent_GetDTCOfEvent_EvtInfo_MCU_E_SYSTEM_PLL_LOCK_LOSS: start-on-event=DemSatellite_0InternalBehavior/GetDTCOfEvent, operation=EvtInfo_MCU_E_SYSTEM_PLL_LOCK_LOSS.GetDTCOfEvent
        OpEventGetFaultDetectionCounter_GetFaultDetectionCounter_EvtInfo_MCU_E_SYSTEM_PLL_LOCK_LOSS: start-on-event=DemSatellite_0InternalBehavior/GetFaultDetectionCounter, operation=EvtInfo_MCU_E_SYSTEM_PLL_LOCK_LOSS.GetFaultDetectionCounter
        OpEventGetEventFreezeFrameDataEx_GetEventFreezeFrameDataEx_EvtInfo_MCU_E_SYSTEM_PLL_LOCK_LOSS: start-on-event=DemSatellite_0InternalBehavior/GetEventFreezeFrameDataEx, operation=EvtInfo_MCU_E_SYSTEM_PLL_LOCK_LOSS.GetEventFreezeFrameDataEx
        OpEventGetEventExtendedDataRecordEx_GetEventExtendedDataRecordEx_EvtInfo_MCU_E_SYSTEM_PLL_LOCK_LOSS: start-on-event=DemSatellite_0InternalBehavior/GetEventExtendedDataRecordEx, operation=EvtInfo_MCU_E_SYSTEM_PLL_LOCK_LOSS.GetEventExtendedDataRecordEx
        OpEventGetEventEnableCondition_GetEventEnableCondition_EvtInfo_MCU_E_SYSTEM_PLL_LOCK_LOSS: start-on-event=DemSatellite_0InternalBehavior/GetEventEnableCondition, operation=EvtInfo_MCU_E_SYSTEM_PLL_LOCK_LOSS.GetEventEnableCondition
        OpEventGetDebouncingOfEvent_GetDebouncingOfEvent_EvtInfo_MCU_E_SYSTEM_PLL_LOCK_LOSS: start-on-event=DemSatellite_0InternalBehavior/GetDebouncingOfEvent, operation=EvtInfo_MCU_E_SYSTEM_PLL_LOCK_LOSS.GetDebouncingOfEvent
        OpEventGetMonitorStatus_GetMonitorStatus_EvtInfo_MCU_E_SYSTEM_PLL_LOCK_LOSS: start-on-event=DemSatellite_0InternalBehavior/GetMonitorStatus, operation=EvtInfo_MCU_E_SYSTEM_PLL_LOCK_LOSS.GetMonitorStatus
        OpEventGetEventUdsStatus_GetEventUdsStatus_EvtInfo_FEE_E_READ: start-on-event=DemSatellite_0InternalBehavior/GetEventUdsStatus, operation=EvtInfo_FEE_E_READ.GetEventUdsStatus
        OpEventGetEventStatus_GetEventStatus_EvtInfo_FEE_E_READ: start-on-event=DemSatellite_0InternalBehavior/GetEventStatus, operation=EvtInfo_FEE_E_READ.GetEventStatus
        OpEventGetEventFailed_GetEventFailed_EvtInfo_FEE_E_READ: start-on-event=DemSatellite_0InternalBehavior/GetEventFailed, operation=EvtInfo_FEE_E_READ.GetEventFailed
        OpEventGetEventTested_GetEventTested_EvtInfo_FEE_E_READ: start-on-event=DemSatellite_0InternalBehavior/GetEventTested, operation=EvtInfo_FEE_E_READ.GetEventTested
        OpEventGetDTCOfEvent_GetDTCOfEvent_EvtInfo_FEE_E_READ: start-on-event=DemSatellite_0InternalBehavior/GetDTCOfEvent, operation=EvtInfo_FEE_E_READ.GetDTCOfEvent
        OpEventGetFaultDetectionCounter_GetFaultDetectionCounter_EvtInfo_FEE_E_READ: start-on-event=DemSatellite_0InternalBehavior/GetFaultDetectionCounter, operation=EvtInfo_FEE_E_READ.GetFaultDetectionCounter
        OpEventGetEventFreezeFrameDataEx_GetEventFreezeFrameDataEx_EvtInfo_FEE_E_READ: start-on-event=DemSatellite_0InternalBehavior/GetEventFreezeFrameDataEx, operation=EvtInfo_FEE_E_READ.GetEventFreezeFrameDataEx
        OpEventGetEventExtendedDataRecordEx_GetEventExtendedDataRecordEx_EvtInfo_FEE_E_READ: start-on-event=DemSatellite_0InternalBehavior/GetEventExtendedDataRecordEx, operation=EvtInfo_FEE_E_READ.GetEventExtendedDataRecordEx
        OpEventGetEventEnableCondition_GetEventEnableCondition_EvtInfo_FEE_E_READ: start-on-event=DemSatellite_0InternalBehavior/GetEventEnableCondition, operation=EvtInfo_FEE_E_READ.GetEventEnableCondition
        OpEventGetDebouncingOfEvent_GetDebouncingOfEvent_EvtInfo_FEE_E_READ: start-on-event=DemSatellite_0InternalBehavior/GetDebouncingOfEvent, operation=EvtInfo_FEE_E_READ.GetDebouncingOfEvent
        OpEventGetMonitorStatus_GetMonitorStatus_EvtInfo_FEE_E_READ: start-on-event=DemSatellite_0InternalBehavior/GetMonitorStatus, operation=EvtInfo_FEE_E_READ.GetMonitorStatus
        OpEventGetEventUdsStatus_GetEventUdsStatus_EvtInfo_DTC_0xd88987: start-on-event=DemSatellite_0InternalBehavior/GetEventUdsStatus, operation=EvtInfo_DTC_0xd88987.GetEventUdsStatus
        OpEventGetEventUdsStatus_GetEventUdsStatus_Event_DTC_0xd88987: start-on-event=DemSatellite_0InternalBehavior/GetEventUdsStatus, operation=Event_DTC_0xd88987.GetEventUdsStatus
        OpEventGetEventStatus_GetEventStatus_EvtInfo_DTC_0xd88987: start-on-event=DemSatellite_0InternalBehavior/GetEventStatus, operation=EvtInfo_DTC_0xd88987.GetEventStatus
        OpEventGetEventStatus_GetEventStatus_Event_DTC_0xd88987: start-on-event=DemSatellite_0InternalBehavior/GetEventStatus, operation=Event_DTC_0xd88987.GetEventStatus
        OpEventGetEventFailed_GetEventFailed_EvtInfo_DTC_0xd88987: start-on-event=DemSatellite_0InternalBehavior/GetEventFailed, operation=EvtInfo_DTC_0xd88987.GetEventFailed
        OpEventGetEventFailed_GetEventFailed_Event_DTC_0xd88987: start-on-event=DemSatellite_0InternalBehavior/GetEventFailed, operation=Event_DTC_0xd88987.GetEventFailed
        OpEventGetEventTested_GetEventTested_EvtInfo_DTC_0xd88987: start-on-event=DemSatellite_0InternalBehavior/GetEventTested, operation=EvtInfo_DTC_0xd88987.GetEventTested
        OpEventGetEventTested_GetEventTested_Event_DTC_0xd88987: start-on-event=DemSatellite_0InternalBehavior/GetEventTested, operation=Event_DTC_0xd88987.GetEventTested
        OpEventGetDTCOfEvent_GetDTCOfEvent_EvtInfo_DTC_0xd88987: start-on-event=DemSatellite_0InternalBehavior/GetDTCOfEvent, operation=EvtInfo_DTC_0xd88987.GetDTCOfEvent
        OpEventGetDTCOfEvent_GetDTCOfEvent_Event_DTC_0xd88987: start-on-event=DemSatellite_0InternalBehavior/GetDTCOfEvent, operation=Event_DTC_0xd88987.GetDTCOfEvent
        OpEventGetFaultDetectionCounter_GetFaultDetectionCounter_EvtInfo_DTC_0xd88987: start-on-event=DemSatellite_0InternalBehavior/GetFaultDetectionCounter, operation=EvtInfo_DTC_0xd88987.GetFaultDetectionCounter
        OpEventGetFaultDetectionCounter_GetFaultDetectionCounter_Event_DTC_0xd88987: start-on-event=DemSatellite_0InternalBehavior/GetFaultDetectionCounter, operation=Event_DTC_0xd88987.GetFaultDetectionCounter
        OpEventGetEventFreezeFrameDataEx_GetEventFreezeFrameDataEx_EvtInfo_DTC_0xd88987: start-on-event=DemSatellite_0InternalBehavior/GetEventFreezeFrameDataEx, operation=EvtInfo_DTC_0xd88987.GetEventFreezeFrameDataEx
        OpEventGetEventFreezeFrameDataEx_GetEventFreezeFrameDataEx_Event_DTC_0xd88987: start-on-event=DemSatellite_0InternalBehavior/GetEventFreezeFrameDataEx, operation=Event_DTC_0xd88987.GetEventFreezeFrameDataEx
        OpEventGetEventExtendedDataRecordEx_GetEventExtendedDataRecordEx_EvtInfo_DTC_0xd88987: start-on-event=DemSatellite_0InternalBehavior/GetEventExtendedDataRecordEx, operation=EvtInfo_DTC_0xd88987.GetEventExtendedDataRecordEx
        OpEventGetEventExtendedDataRecordEx_GetEventExtendedDataRecordEx_Event_DTC_0xd88987: start-on-event=DemSatellite_0InternalBehavior/GetEventExtendedDataRecordEx, operation=Event_DTC_0xd88987.GetEventExtendedDataRecordEx
        OpEventGetEventEnableCondition_GetEventEnableCondition_EvtInfo_DTC_0xd88987: start-on-event=DemSatellite_0InternalBehavior/GetEventEnableCondition, operation=EvtInfo_DTC_0xd88987.GetEventEnableCondition
        OpEventGetDebouncingOfEvent_GetDebouncingOfEvent_EvtInfo_DTC_0xd88987: start-on-event=DemSatellite_0InternalBehavior/GetDebouncingOfEvent, operation=EvtInfo_DTC_0xd88987.GetDebouncingOfEvent
        OpEventGetMonitorStatus_GetMonitorStatus_EvtInfo_DTC_0xd88987: start-on-event=DemSatellite_0InternalBehavior/GetMonitorStatus, operation=EvtInfo_DTC_0xd88987.GetMonitorStatus
        OpEventSetEventStatus_SetEventStatus_Event_DTC_0xd88987: start-on-event=SetEventStatus, operation=Event_DTC_0xd88987.SetEventStatus
        OpEventResetEventStatus_ResetEventStatus_Event_DTC_0xd88987: start-on-event=ResetEventStatus, operation=Event_DTC_0xd88987.ResetEventStatus
        OpEventResetEventDebounceStatus_ResetEventDebounceStatus_Event_DTC_0xd88987: start-on-event=ResetEventDebounceStatus, operation=Event_DTC_0xd88987.ResetEventDebounceStatus
        OpEventGetEventUdsStatus_GetEventUdsStatus_EvtInfo_DTC_0xd88a08: start-on-event=DemSatellite_0InternalBehavior/GetEventUdsStatus, operation=EvtInfo_DTC_0xd88a08.GetEventUdsStatus
        OpEventGetEventUdsStatus_GetEventUdsStatus_Event_DTC_0xd88a08: start-on-event=DemSatellite_0InternalBehavior/GetEventUdsStatus, operation=Event_DTC_0xd88a08.GetEventUdsStatus
        OpEventGetEventStatus_GetEventStatus_EvtInfo_DTC_0xd88a08: start-on-event=DemSatellite_0InternalBehavior/GetEventStatus, operation=EvtInfo_DTC_0xd88a08.GetEventStatus
        OpEventGetEventStatus_GetEventStatus_Event_DTC_0xd88a08: start-on-event=DemSatellite_0InternalBehavior/GetEventStatus, operation=Event_DTC_0xd88a08.GetEventStatus
        OpEventGetEventFailed_GetEventFailed_EvtInfo_DTC_0xd88a08: start-on-event=DemSatellite_0InternalBehavior/GetEventFailed, operation=EvtInfo_DTC_0xd88a08.GetEventFailed
        OpEventGetEventFailed_GetEventFailed_Event_DTC_0xd88a08: start-on-event=DemSatellite_0InternalBehavior/GetEventFailed, operation=Event_DTC_0xd88a08.GetEventFailed
        OpEventGetEventTested_GetEventTested_EvtInfo_DTC_0xd88a08: start-on-event=DemSatellite_0InternalBehavior/GetEventTested, operation=EvtInfo_DTC_0xd88a08.GetEventTested
        OpEventGetEventTested_GetEventTested_Event_DTC_0xd88a08: start-on-event=DemSatellite_0InternalBehavior/GetEventTested, operation=Event_DTC_0xd88a08.GetEventTested
        OpEventGetDTCOfEvent_GetDTCOfEvent_EvtInfo_DTC_0xd88a08: start-on-event=DemSatellite_0InternalBehavior/GetDTCOfEvent, operation=EvtInfo_DTC_0xd88a08.GetDTCOfEvent
        OpEventGetDTCOfEvent_GetDTCOfEvent_Event_DTC_0xd88a08: start-on-event=DemSatellite_0InternalBehavior/GetDTCOfEvent, operation=Event_DTC_0xd88a08.GetDTCOfEvent
        OpEventGetFaultDetectionCounter_GetFaultDetectionCounter_EvtInfo_DTC_0xd88a08: start-on-event=DemSatellite_0InternalBehavior/GetFaultDetectionCounter, operation=EvtInfo_DTC_0xd88a08.GetFaultDetectionCounter
        OpEventGetFaultDetectionCounter_GetFaultDetectionCounter_Event_DTC_0xd88a08: start-on-event=DemSatellite_0InternalBehavior/GetFaultDetectionCounter, operation=Event_DTC_0xd88a08.GetFaultDetectionCounter
        OpEventGetEventFreezeFrameDataEx_GetEventFreezeFrameDataEx_EvtInfo_DTC_0xd88a08: start-on-event=DemSatellite_0InternalBehavior/GetEventFreezeFrameDataEx, operation=EvtInfo_DTC_0xd88a08.GetEventFreezeFrameDataEx
        OpEventGetEventFreezeFrameDataEx_GetEventFreezeFrameDataEx_Event_DTC_0xd88a08: start-on-event=DemSatellite_0InternalBehavior/GetEventFreezeFrameDataEx, operation=Event_DTC_0xd88a08.GetEventFreezeFrameDataEx
        OpEventGetEventExtendedDataRecordEx_GetEventExtendedDataRecordEx_EvtInfo_DTC_0xd88a08: start-on-event=DemSatellite_0InternalBehavior/GetEventExtendedDataRecordEx, operation=EvtInfo_DTC_0xd88a08.GetEventExtendedDataRecordEx
        OpEventGetEventExtendedDataRecordEx_GetEventExtendedDataRecordEx_Event_DTC_0xd88a08: start-on-event=DemSatellite_0InternalBehavior/GetEventExtendedDataRecordEx, operation=Event_DTC_0xd88a08.GetEventExtendedDataRecordEx
        OpEventGetEventEnableCondition_GetEventEnableCondition_EvtInfo_DTC_0xd88a08: start-on-event=DemSatellite_0InternalBehavior/GetEventEnableCondition, operation=EvtInfo_DTC_0xd88a08.GetEventEnableCondition
        OpEventGetDebouncingOfEvent_GetDebouncingOfEvent_EvtInfo_DTC_0xd88a08: start-on-event=DemSatellite_0InternalBehavior/GetDebouncingOfEvent, operation=EvtInfo_DTC_0xd88a08.GetDebouncingOfEvent
        OpEventGetMonitorStatus_GetMonitorStatus_EvtInfo_DTC_0xd88a08: start-on-event=DemSatellite_0InternalBehavior/GetMonitorStatus, operation=EvtInfo_DTC_0xd88a08.GetMonitorStatus
        OpEventSetEventStatus_SetEventStatus_Event_DTC_0xd88a08: start-on-event=SetEventStatus, operation=Event_DTC_0xd88a08.SetEventStatus
        OpEventResetEventStatus_ResetEventStatus_Event_DTC_0xd88a08: start-on-event=ResetEventStatus, operation=Event_DTC_0xd88a08.ResetEventStatus
        OpEventResetEventDebounceStatus_ResetEventDebounceStatus_Event_DTC_0xd88a08: start-on-event=ResetEventDebounceStatus, operation=Event_DTC_0xd88a08.ResetEventDebounceStatus
      port-api-options:
        enable-take-address=true, indirect-api=false, port=DemSatellite_0/GeneralEvtInfo
        enable-take-address=true, indirect-api=false, port=DemSatellite_0/CBReadData_Data_DID_0x133_Current_Operating_Time
        enable-take-address=true, indirect-api=false, port=DemSatellite_0/CBReadData_Data_DID_0x10a_Vehicle_Odometer_in_Low_Resolution
        enable-take-address=true, indirect-api=false, port=DemSatellite_0/CBReadData_Data_DID_0x18b_SecOcDataID
        enable-take-address=true, indirect-api=false, port=DemSatellite_0/CBReadData_Data_DID_0x133_Operating_Time_Status
        {enable-take-address=true, indirect-api=false, port-defined-argument-value{value=1, value-type=Dem_EventIdType}, port=EvtInfo_DTC_0x1ca000}
        {enable-take-address=true, indirect-api=false, port-defined-argument-value{value=1, value-type=Dem_EventIdType}, port=Event_DTC_0x1ca000}
        {enable-take-address=true, indirect-api=false, port-defined-argument-value{value=5, value-type=Dem_EventIdType}, port=EvtInfo_DTC_0xa10b00}
        {enable-take-address=true, indirect-api=false, port-defined-argument-value{value=5, value-type=Dem_EventIdType}, port=Event_DTC_0xa10b00}
        {enable-take-address=true, indirect-api=false, port-defined-argument-value{value=28, value-type=Dem_EventIdType}, port=EvtInfo_DTC_0xc44286}
        {enable-take-address=true, indirect-api=false, port-defined-argument-value{value=28, value-type=Dem_EventIdType}, port=Event_DTC_0xc44286}
        {enable-take-address=true, indirect-api=false, port-defined-argument-value{value=6, value-type=Dem_EventIdType}, port=EvtInfo_DTC_0xa10d00}
        {enable-take-address=true, indirect-api=false, port-defined-argument-value{value=6, value-type=Dem_EventIdType}, port=Event_DTC_0xa10d00}
        {enable-take-address=true, indirect-api=false, port-defined-argument-value{value=11, value-type=Dem_EventIdType}, port=EvtInfo_DTC_0xa28b45}
        {enable-take-address=true, indirect-api=false, port-defined-argument-value{value=11, value-type=Dem_EventIdType}, port=Event_DTC_0xa28b45}
        {enable-take-address=true, indirect-api=false, port-defined-argument-value{value=29, value-type=Dem_EventIdType}, port=EvtInfo_DTC_0xc45208}
        {enable-take-address=true, indirect-api=false, port-defined-argument-value{value=29, value-type=Dem_EventIdType}, port=Event_DTC_0xc45208}
        {enable-take-address=true, indirect-api=false, port-defined-argument-value{value=13, value-type=Dem_EventIdType}, port=EvtInfo_DTC_0xa28b49}
        {enable-take-address=true, indirect-api=false, port-defined-argument-value{value=13, value-type=Dem_EventIdType}, port=Event_DTC_0xa28b49}
        {enable-take-address=true, indirect-api=false, port-defined-argument-value{value=12, value-type=Dem_EventIdType}, port=EvtInfo_DTC_0xa28b47}
        {enable-take-address=true, indirect-api=false, port-defined-argument-value{value=12, value-type=Dem_EventIdType}, port=Event_DTC_0xa28b47}
        {enable-take-address=true, indirect-api=false, port-defined-argument-value{value=26, value-type=Dem_EventIdType}, port=EvtInfo_DTC_0xc41608}
        {enable-take-address=true, indirect-api=false, port-defined-argument-value{value=26, value-type=Dem_EventIdType}, port=Event_DTC_0xc41608}
        {enable-take-address=true, indirect-api=false, port-defined-argument-value{value=25, value-type=Dem_EventIdType}, port=EvtInfo_DTC_0xc20287}
        {enable-take-address=true, indirect-api=false, port-defined-argument-value{value=25, value-type=Dem_EventIdType}, port=Event_DTC_0xc20287}
        {enable-take-address=true, indirect-api=false, port-defined-argument-value{value=18, value-type=Dem_EventIdType}, port=EvtInfo_DTC_0xa20400}
        {enable-take-address=true, indirect-api=false, port-defined-argument-value{value=18, value-type=Dem_EventIdType}, port=Event_DTC_0xa20400}
        {enable-take-address=true, indirect-api=false, port-defined-argument-value{value=2, value-type=Dem_EventIdType}, port=EvtInfo_DTC_0x9a6857}
        {enable-take-address=true, indirect-api=false, port-defined-argument-value{value=2, value-type=Dem_EventIdType}, port=Event_DTC_0x9a6857}
        {enable-take-address=true, indirect-api=false, port-defined-argument-value{value=14, value-type=Dem_EventIdType}, port=EvtInfo_DTC_0xa28b71}
        {enable-take-address=true, indirect-api=false, port-defined-argument-value{value=14, value-type=Dem_EventIdType}, port=Event_DTC_0xa28b71}
        {enable-take-address=true, indirect-api=false, port-defined-argument-value{value=4, value-type=Dem_EventIdType}, port=EvtInfo_DTC_0xa10a00}
        {enable-take-address=true, indirect-api=false, port-defined-argument-value{value=4, value-type=Dem_EventIdType}, port=Event_DTC_0xa10a00}
        {enable-take-address=true, indirect-api=false, port-defined-argument-value{value=30, value-type=Dem_EventIdType}, port=EvtInfo_DTC_0xd12081}
        {enable-take-address=true, indirect-api=false, port-defined-argument-value{value=30, value-type=Dem_EventIdType}, port=Event_DTC_0xd12081}
        {enable-take-address=true, indirect-api=false, port-defined-argument-value{value=31, value-type=Dem_EventIdType}, port=EvtInfo_DTC_0xd12083}
        {enable-take-address=true, indirect-api=false, port-defined-argument-value{value=31, value-type=Dem_EventIdType}, port=Event_DTC_0xd12083}
        {enable-take-address=true, indirect-api=false, port-defined-argument-value{value=7, value-type=Dem_EventIdType}, port=EvtInfo_DTC_0xa10e00}
        {enable-take-address=true, indirect-api=false, port-defined-argument-value{value=7, value-type=Dem_EventIdType}, port=Event_DTC_0xa10e00}
        {enable-take-address=true, indirect-api=false, port-defined-argument-value{value=3, value-type=Dem_EventIdType}, port=EvtInfo_DTC_0x164456}
        {enable-take-address=true, indirect-api=false, port-defined-argument-value{value=3, value-type=Dem_EventIdType}, port=Event_DTC_0x164456}
        {enable-take-address=true, indirect-api=false, port-defined-argument-value{value=17, value-type=Dem_EventIdType}, port=EvtInfo_DTC_0xa28bfa}
        {enable-take-address=true, indirect-api=false, port-defined-argument-value{value=17, value-type=Dem_EventIdType}, port=Event_DTC_0xa28bfa}
        {enable-take-address=true, indirect-api=false, port-defined-argument-value{value=22, value-type=Dem_EventIdType}, port=EvtInfo_DTC_0xc15587}
        {enable-take-address=true, indirect-api=false, port-defined-argument-value{value=22, value-type=Dem_EventIdType}, port=Event_DTC_0xc15587}
        {enable-take-address=true, indirect-api=false, port-defined-argument-value{value=33, value-type=Dem_EventIdType}, port=EvtInfo_DTC_0xd22488}
        {enable-take-address=true, indirect-api=false, port-defined-argument-value{value=33, value-type=Dem_EventIdType}, port=Event_DTC_0xd22488}
        {enable-take-address=true, indirect-api=false, port-defined-argument-value{value=32, value-type=Dem_EventIdType}, port=EvtInfo_DTC_0xd12087}
        {enable-take-address=true, indirect-api=false, port-defined-argument-value{value=32, value-type=Dem_EventIdType}, port=Event_DTC_0xd12087}
        {enable-take-address=true, indirect-api=false, port-defined-argument-value{value=19, value-type=Dem_EventIdType}, port=EvtInfo_DTC_0xc11587}
        {enable-take-address=true, indirect-api=false, port-defined-argument-value{value=19, value-type=Dem_EventIdType}, port=Event_DTC_0xc11587}
        {enable-take-address=true, indirect-api=false, port-defined-argument-value{value=21, value-type=Dem_EventIdType}, port=EvtInfo_DTC_0xc15187}
        {enable-take-address=true, indirect-api=false, port-defined-argument-value{value=21, value-type=Dem_EventIdType}, port=Event_DTC_0xc15187}
        {enable-take-address=true, indirect-api=false, port-defined-argument-value{value=24, value-type=Dem_EventIdType}, port=EvtInfo_DTC_0xc20187}
        {enable-take-address=true, indirect-api=false, port-defined-argument-value{value=24, value-type=Dem_EventIdType}, port=Event_DTC_0xc20187}
        {enable-take-address=true, indirect-api=false, port-defined-argument-value{value=8, value-type=Dem_EventIdType}, port=EvtInfo_DTC_0xa28b4b}
        {enable-take-address=true, indirect-api=false, port-defined-argument-value{value=8, value-type=Dem_EventIdType}, port=Event_DTC_0xa28b4b}
        {enable-take-address=true, indirect-api=false, port-defined-argument-value{value=15, value-type=Dem_EventIdType}, port=EvtInfo_DTC_0xa28b96}
        {enable-take-address=true, indirect-api=false, port-defined-argument-value{value=15, value-type=Dem_EventIdType}, port=Event_DTC_0xa28b96}
        {enable-take-address=true, indirect-api=false, port-defined-argument-value{value=20, value-type=Dem_EventIdType}, port=EvtInfo_DTC_0xc12287}
        {enable-take-address=true, indirect-api=false, port-defined-argument-value{value=20, value-type=Dem_EventIdType}, port=Event_DTC_0xc12287}
        {enable-take-address=true, indirect-api=false, port-defined-argument-value{value=23, value-type=Dem_EventIdType}, port=EvtInfo_DTC_0xc16887}
        {enable-take-address=true, indirect-api=false, port-defined-argument-value{value=23, value-type=Dem_EventIdType}, port=Event_DTC_0xc16887}
        {enable-take-address=true, indirect-api=false, port-defined-argument-value{value=16, value-type=Dem_EventIdType}, port=EvtInfo_DTC_0xa28b97}
        {enable-take-address=true, indirect-api=false, port-defined-argument-value{value=16, value-type=Dem_EventIdType}, port=Event_DTC_0xa28b97}
        {enable-take-address=true, indirect-api=false, port-defined-argument-value{value=9, value-type=Dem_EventIdType}, port=EvtInfo_DTC_0xa28b16}
        {enable-take-address=true, indirect-api=false, port-defined-argument-value{value=9, value-type=Dem_EventIdType}, port=Event_DTC_0xa28b16}
        {enable-take-address=true, indirect-api=false, port-defined-argument-value{value=27, value-type=Dem_EventIdType}, port=EvtInfo_DTC_0xc42708}
        {enable-take-address=true, indirect-api=false, port-defined-argument-value{value=27, value-type=Dem_EventIdType}, port=Event_DTC_0xc42708}
        {enable-take-address=true, indirect-api=false, port-defined-argument-value{value=10, value-type=Dem_EventIdType}, port=EvtInfo_DTC_0xa28b17}
        {enable-take-address=true, indirect-api=false, port-defined-argument-value{value=10, value-type=Dem_EventIdType}, port=Event_DTC_0xa28b17}
        {enable-take-address=true, indirect-api=false, port-defined-argument-value{value=34, value-type=Dem_EventIdType}, port=EvtInfo_DTC_0xd88987}
        {enable-take-address=true, indirect-api=false, port-defined-argument-value{value=34, value-type=Dem_EventIdType}, port=Event_DTC_0xd88987}
        {enable-take-address=true, indirect-api=false, port-defined-argument-value{value=36, value-type=Dem_EventIdType}, port=EvtInfo_SPI_E_HARDWARE_ERROR}
        {enable-take-address=true, indirect-api=false, port-defined-argument-value{value=37, value-type=Dem_EventIdType}, port=EvtInfo_WDGM_E_MONITORING}
        {enable-take-address=true, indirect-api=false, port-defined-argument-value{value=38, value-type=Dem_EventIdType}, port=EvtInfo_WDGM_E_IMPROPER_CALLER}
        {enable-take-address=true, indirect-api=false, port-defined-argument-value{value=39, value-type=Dem_EventIdType}, port=EvtInfo_ADC_ERROR_Dummy}
        {enable-take-address=true, indirect-api=false, port-defined-argument-value{value=39, value-type=Dem_EventIdType}, port=Event_ADC_ERROR_Dummy}
        {enable-take-address=true, indirect-api=false, port-defined-argument-value{value=40, value-type=Dem_EventIdType}, port=EvtInfo_MCU_E_OSC_FAILURE}
        {enable-take-address=true, indirect-api=false, port-defined-argument-value{value=41, value-type=Dem_EventIdType}, port=EvtInfo_MCU_E_SYSTEM_PLL_LOCK_LOSS}
        {enable-take-address=true, indirect-api=false, port-defined-argument-value{value=42, value-type=Dem_EventIdType}, port=EvtInfo_FEE_E_READ}
        {enable-take-address=true, indirect-api=false, port-defined-argument-value{value=35, value-type=Dem_EventIdType}, port=EvtInfo_DTC_0xd88a08}
        {enable-take-address=true, indirect-api=false, port-defined-argument-value{value=35, value-type=Dem_EventIdType}, port=Event_DTC_0xd88a08}
        enable-take-address=true, indirect-api=false, port=DemSatellite_0/CBReadData_Data_DID_0xfd05_Root_Causes
      15 x runnable:
        Dem_SatelliteMainFunction
          5 x sync call, all with timeout=0:
            OpServerCallDem_SatelliteMainFunction_ReadData_CBReadData_Data_DID_0x133_Current_Operating_Time: operation=CBReadData_Data_DID_0x133_Current_Operating_Time.ReadData
            OpServerCallDem_SatelliteMainFunction_ReadData_CBReadData_Data_DID_0x10a_Vehicle_Odometer_in_Low_Resolution: operation=CBReadData_Data_DID_0x10a_Vehicle_Odometer_in_Low_Resolution.ReadData
            OpServerCallDem_SatelliteMainFunction_ReadData_CBReadData_Data_DID_0x18b_SecOcDataID: operation=CBReadData_Data_DID_0x18b_SecOcDataID.ReadData
            OpServerCallDem_SatelliteMainFunction_ReadData_CBReadData_Data_DID_0x133_Operating_Time_Status: operation=CBReadData_Data_DID_0x133_Operating_Time_Status.ReadData
            OpServerCallDem_SatelliteMainFunction_ReadData_CBReadData_Data_DID_0xfd05_Root_Causes: operation=CBReadData_Data_DID_0xfd05_Root_Causes.ReadData
        GetEventUdsStatus: can-be-invoked-concurrently=true, symbol=Dem_GetEventUdsStatus
        GetEventStatus: can-be-invoked-concurrently=true, symbol=Dem_GetEventUdsStatus
        GetEventFailed: can-be-invoked-concurrently=true, symbol=Dem_GetEventFailed
        GetEventTested: can-be-invoked-concurrently=true, symbol=Dem_GetEventTested
        GetDTCOfEvent: can-be-invoked-concurrently=true, symbol=Dem_GetDTCOfEvent
        GetFaultDetectionCounter: can-be-invoked-concurrently=true, symbol=Dem_GetFaultDetectionCounter
        GetEventFreezeFrameDataEx: can-be-invoked-concurrently=true, symbol=Dem_GetEventFreezeFrameDataEx
        GetEventExtendedDataRecordEx: can-be-invoked-concurrently=true, symbol=Dem_GetEventExtendedDataRecordEx
        GetEventEnableCondition: can-be-invoked-concurrently=true, symbol=Dem_GetEventEnableCondition
        GetDebouncingOfEvent: can-be-invoked-concurrently=true, symbol=Dem_GetDebouncingOfEvent
        GetMonitorStatus: can-be-invoked-concurrently=true, symbol=Dem_GetMonitorStatus
        SetEventStatus: can-be-invoked-concurrently=true, symbol=Dem_SetEventStatus
        ResetEventStatus: can-be-invoked-concurrently=true, symbol=Dem_ResetEventStatus
        ResetEventDebounceStatus: can-be-invoked-concurrently=true, symbol=Dem_ResetEventDebounceStatus
  swc implementation DemSatellite_0Implementation: programming-language=C, behavior=DemSatellite_0InternalBehavior
